VERSION "dbc-export 1 2025.20.8"

NS_ :

BS_:

BU_: ADSP APB APP APS APSB BB BMS CC CMP CMPD CP DAS DI DIF DIR DPB EPAS3P EPAS3S EPASTP EPASTS EPBL EPBR ESP EVSE FC GTW HCML HCMR HVP IBST ICR IDB LS OCS1P PARK PCS PM PMF PMR PNCD PTC RADC RCM RCM2 RCM3 RCU SCCM SCM SCS SDCR TAS TCU TPMS TRCM UI UIS UMC USM VC VCFRONT VCLEFT VCRIGHT VCSEC VEH

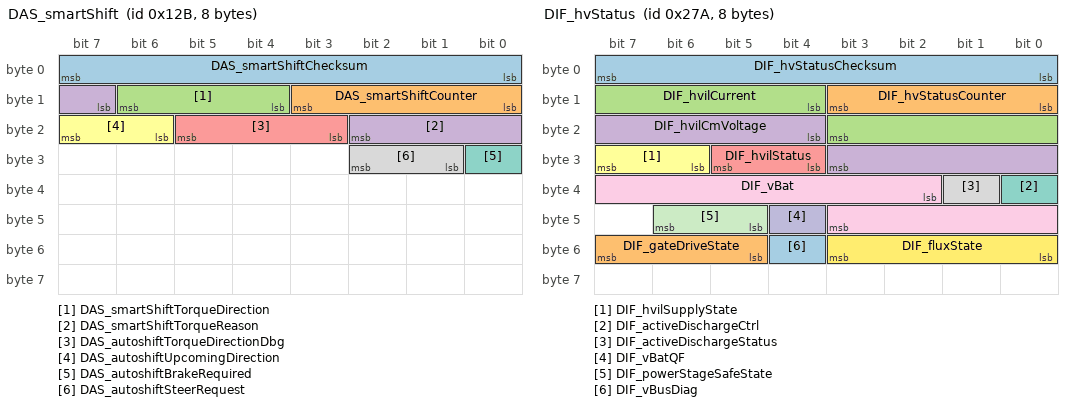
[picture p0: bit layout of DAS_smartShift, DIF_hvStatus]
BO_ 299 DAS_smartShift: 8 DAS
 SG_ DAS_smartShiftChecksum : 0|8@1+ (1,0) [0|255] "" Vector__XXX
 SG_ DAS_smartShiftCounter : 8|4@1+ (1,0) [0|15] "" Vector__XXX
 SG_ DAS_smartShiftTorqueDirection : 12|3@1+ (1,0) [0|7] "" Vector__XXX
 SG_ DAS_smartShiftTorqueReason : 15|4@1+ (1,0) [0|15] "" Vector__XXX
 SG_ DAS_autoshiftTorqueDirectionDbg : 19|3@1+ (1,0) [0|7] "" Vector__XXX
 SG_ DAS_autoshiftUpcomingDirection : 22|2@1+ (1,0) [0|3] "" Vector__XXX
 SG_ DAS_autoshiftBrakeRequired : 24|1@1+ (1,0) [0|1] "" Vector__XXX
 SG_ DAS_autoshiftSteerRequest : 25|2@1+ (1,0) [0|3] "" Vector__XXX

BO_ 921 DAS_status: 8 DAS
 SG_ DAS_autopilotState : 0|4@1+ (1,0) [0|15] "" Vector__XXX
 SG_ DAS_blindSpotRearLeft : 4|2@1+ (1,0) [0|3] "" Vector__XXX
 SG_ DAS_blindSpotRearRight : 6|2@1+ (1,0) [0|3] "" Vector__XXX
 SG_ DAS_fusedSpeedLimit : 8|5@1+ (5,0) [0|150] "kph/mph" Vector__XXX
 SG_ DAS_suppressSpeedWarning : 13|1@1+ (1,0) [0|1] "" Vector__XXX
 SG_ DAS_summonObstacle : 14|1@1+ (1,0) [0|1] "" Vector__XXX
 SG_ DAS_summonClearedGate : 15|1@1+ (1,0) [0|1] "" Vector__XXX
 SG_ DAS_visionOnlySpeedLimit : 16|5@1+ (5,0) [0|150] "kph/mph" Vector__XXX
 SG_ DAS_heaterState : 21|1@1+ (1,0) [0|1] "" Vector__XXX
 SG_ DAS_forwardCollisionWarning : 22|2@1+ (1,0) [0|3] "" Vector__XXX
 SG_ DAS_autoparkReady : 24|1@1+ (1,0) [0|1] "" Vector__XXX
 SG_ DAS_autoParked : 25|1@1+ (1,0) [0|1] "" Vector__XXX
 SG_ DAS_autoparkActive : 26|1@1+ (1,0) [0|1] "" Vector__XXX
 SG_ DAS_summonFwdLeashReached : 27|1@1+ (1,0) [0|1] "" Vector__XXX
 SG_ DAS_summonRvsLeashReached : 28|1@1+ (1,0) [0|1] "" Vector__XXX
 SG_ DAS_lssState : 29|3@1+ (1,0) [0|7] "" Vector__XXX
 SG_ DAS_sideCollisionAvoid : 32|2@1+ (1,0) [0|3] "" Vector__XXX
 SG_ DAS_sideCollisionWarning : 34|2@1+ (1,0) [0|3] "" Vector__XXX
 SG_ DAS_sideCollisionInhibit : 36|1@1+ (1,0) [0|1] "" Vector__XXX
 SG_ DAS_laneDepartureWarning : 37|3@1+ (1,0) [0|7] "" Vector__XXX
 SG_ DAS_fleetSpeedState : 40|2@1+ (1,0) [0|3] "" Vector__XXX
 SG_ DAS_autopilotHandsOnState : 42|4@1+ (1,0) [0|15] "" Vector__XXX
 SG_ DAS_autoLaneChangeState : 46|5@1+ (1,0) [0|31] "" Vector__XXX
 SG_ DAS_summonAvailable : 51|1@1+ (1,0) [0|1] "" Vector__XXX
 SG_ DAS_statusCounter : 52|4@1+ (1,0) [0|15] "" Vector__XXX
 SG_ DAS_statusChecksum : 56|8@1+ (1,0) [0|255] "" Vector__XXX

BO_ 905 DAS_status2: 8 DAS
 SG_ DAS_accSpeedLimit : 0|9@1+ (0.4,0) [0|200] "mph" Vector__XXX
 SG_ DAS_versionIdentifier : 9|1@1+ (1,0) [0|1] "" Vector__XXX
 SG_ DAS_pmmObstacleSeverity : 10|3@1+ (1,0) [0|7] "" Vector__XXX
 SG_ DAS_pmmLoggingRequest : 13|1@1+ (1,0) [0|1] "" Vector__XXX
 SG_ DAS_activationFailureStatus : 14|2@1+ (1,0) [0|3] "" Vector__XXX
 SG_ DAS_pmmUltrasonicsFaultReason : 16|3@1+ (1,0) [0|7] "" Vector__XXX
 SG_ DAS_pmmRadarFaultReason : 19|2@1+ (1,0) [0|3] "" Vector__XXX
 SG_ DAS_pmmSysFaultReason : 21|3@1+ (1,0) [0|7] "" Vector__XXX
 SG_ DAS_pmmCameraFaultReason : 24|2@1+ (1,0) [0|3] "" Vector__XXX
 SG_ DAS_ACC_report : 26|5@1+ (1,0) [0|31] "" Vector__XXX
 SG_ DAS_relaxCruiseLimits : 31|1@1+ (1,0) [0|1] "" Vector__XXX
 SG_ DAS_csaState : 32|2@1+ (1,0) [0|3] "" Vector__XXX
 SG_ DAS_radarTelemetry : 34|2@1+ (1,0) [0|3] "" Vector__XXX
 SG_ DAS_robState : 36|2@1+ (1,0) [0|3] "" Vector__XXX
 SG_ DAS_driverInteractionLevel : 38|2@1+ (1,0) [0|3] "" Vector__XXX
 SG_ DAS_ppOffsetDesiredRamp : 40|8@1+ (0.01,-1.28) [-1.28|1.27] "m" Vector__XXX
 SG_ DAS_longCollisionWarning : 48|4@1+ (1,0) [0|15] "" Vector__XXX
 SG_ DAS_status2Counter : 52|4@1+ (1,0) [0|15] "" Vector__XXX
 SG_ DAS_status2Checksum : 56|8@1+ (1,0) [0|255] "" Vector__XXX

BO_ 1548 DAS_telemetryRadar: 8 DAS
 SG_ DAS_TR_ObjIndex M : 0|5@1+ (1,0) [0|31] "" Vector__XXX
 SG_ DAS_TR_Counter : 54|2@1+ (1,0) [0|3] "" Vector__XXX
 SG_ DAS_TR_Obj00_Class m0 : 5|3@1+ (1,0) [0|7] "" Vector__XXX
 SG_ DAS_TR_Obj00_Dx m0 : 8|10@1+ (0.15625,0) [0|159.84375] "m" Vector__XXX
 SG_ DAS_TR_Obj00_Dy m0 : 18|6@1+ (0.5,-15.5) [-15.5|16] "m" Vector__XXX
 SG_ DAS_TR_Obj00_Vx m0 : 24|8@1+ (0.5,-63.5) [-63.5|64] "m/s" Vector__XXX
 SG_ DAS_TR_Obj00_RCS m0 : 32|8@1+ (0.25,-14) [-14|49.75] "dB" Vector__XXX
 SG_ DAS_TR_Obj00_Length m0 : 40|6@1+ (0.125,0) [0|7.875] "m" Vector__XXX
 SG_ DAS_TR_Obj00_MovingState m0 : 46|2@1+ (1,0) [0|3] "" Vector__XXX
 SG_ DAS_TR_Obj00_Dz m0 : 48|6@1+ (0.25,-5) [-5|10.75] "m" Vector__XXX
 SG_ DAS_TR_Obj00_Exist m0 : 56|5@1+ (3.125,0) [0|96.875] "%" Vector__XXX

BO_ 586 DAS_visualDebug: 8 DAS
 SG_ DAS_autosteerVehiclesUsage : 4|2@1+ (1,0) [0|3] "" Vector__XXX
 SG_ DAS_autosteerHPPUsage : 6|2@1+ (1,0) [0|3] "" Vector__XXX
 SG_ DAS_autosteerNavigationUsage : 8|2@1+ (1,0) [0|3] "" Vector__XXX
 SG_ DAS_autosteerModelUsage : 10|2@1+ (1,0) [0|3] "" Vector__XXX
 SG_ DAS_autosteerBottsDotsUsage : 12|2@1+ (1,0) [0|3] "" Vector__XXX
 SG_ DAS_offsetSide : 14|2@1+ (1,0) [0|3] "" Vector__XXX
 SG_ DAS_roadSurfaceType : 16|2@1+ (1,0) [0|3] "" Vector__XXX
 SG_ DAS_autosteerHealthAnomalyLevel : 18|3@1+ (1,0) [0|7] "" Vector__XXX
 SG_ DAS_autosteerHealthState : 21|3@1+ (1,0) [0|7] "" Vector__XXX
 SG_ DAS_lastLinePreferenceReason : 24|4@1+ (1,0) [0|15] "" Vector__XXX
 SG_ DAS_plannerState : 28|4@1+ (1,0) [0|15] "" Vector__XXX
 SG_ DAS_lastAutosteerAbortReason : 32|6@1+ (1,0) [0|63] "" Vector__XXX
 SG_ DAS_devAppInterfaceEnabled : 38|1@1+ (1,0) [0|1] "" Vector__XXX
 SG_ DAS_navAvailable : 39|1@1+ (1,0) [0|1] "" Vector__XXX
 SG_ DAS_navDistance : 40|8@1+ (100,0) [0|25500] "km" Vector__XXX
 SG_ DAS_accSmartSpeedActive : 48|1@1+ (1,0) [0|1] "" Vector__XXX
 SG_ DAS_accSmartSpeedState : 49|3@1+ (1,0) [0|7] "" Vector__XXX
 SG_ DAS_ulcInProgress : 52|1@1+ (1,0) [0|1] "" Vector__XXX
 SG_ DAS_trafficAwareSetSpeedInUse : 53|1@1+ (1,0) [0|1] "" Vector__XXX
 SG_ DAS_isaSystemState : 54|2@1+ (1,0) [0|3] "" Vector__XXX
 SG_ DAS_behaviorType : 56|2@1+ (1,0) [0|3] "" Vector__XXX
 SG_ DAS_ulcType : 58|2@1+ (1,0) [0|3] "" Vector__XXX
 SG_ DAS_rearVehDetectedThisCycle : 60|1@1+ (1,0) [0|1] "" Vector__XXX
 SG_ DAS_rearLeftVehDetectedCurrent : 61|1@1+ (1,0) [0|1] "" Vector__XXX
 SG_ DAS_rearRightVehDetectedTrip : 62|1@1+ (1,0) [0|1] "" Vector__XXX
 SG_ DAS_rearLeftVehDetectedTrip : 63|1@1+ (1,0) [0|1] "" Vector__XXX

BO_ 2040 DAS_warningMatrix0: 8 DAS
 SG_ DAS_w002_ldwDisabled : 1|1@1+ (1,0) [0|1] "" Vector__XXX
 SG_ DAS_w003_isaDisabled : 2|1@1+ (1,0) [0|1] "" Vector__XXX
 SG_ DAS_w004_accDisabled : 3|1@1+ (1,0) [0|1] "" Vector__XXX
 SG_ DAS_w005_fcwCancelled : 4|1@1+ (1,0) [0|1] "" Vector__XXX
 SG_ DAS_w006_aebCancelled : 5|1@1+ (1,0) [0|1] "" Vector__XXX
 SG_ DAS_w007_ahlbDisabled : 6|1@1+ (1,0) [0|1] "" Vector__XXX
 SG_ DAS_w008_parkDisabled : 7|1@1+ (1,0) [0|1] "" Vector__XXX
 SG_ DAS_w009_aebFault : 8|1@1+ (1,0) [0|1] "" Vector__XXX
 SG_ DAS_w010_radcCalibIssue : 9|1@1+ (1,0) [0|1] "" Vector__XXX
 SG_ DAS_w011_scaEvent : 10|1@1+ (1,0) [0|1] "" Vector__XXX
 SG_ DAS_w012_Cam_BootFailure : 11|1@1+ (1,0) [0|1] "" Vector__XXX
 SG_ DAS_w013_Cam_Watchdog : 12|1@1+ (1,0) [0|1] "" Vector__XXX
 SG_ DAS_w014_swAssert : 13|1@1+ (1,0) [0|1] "" Vector__XXX
 SG_ DAS_w015_Camera_Failsafes : 14|1@1+ (1,0) [0|1] "" Vector__XXX
 SG_ DAS_w016_aeb_e_event : 15|1@1+ (1,0) [0|1] "" Vector__XXX
 SG_ DAS_w017_Cam_Msg_MIA : 16|1@1+ (1,0) [0|1] "" Vector__XXX
 SG_ DAS_w018_ECU_Power_Issue : 17|1@1+ (1,0) [0|1] "" Vector__XXX
 SG_ DAS_w019_ECU_Stack_Overflow : 18|1@1+ (1,0) [0|1] "" Vector__XXX
 SG_ DAS_w020_ECU_checkstopError : 19|1@1+ (1,0) [0|1] "" Vector__XXX
 SG_ DAS_w021_ECU_Temperature_Issue : 20|1@1+ (1,0) [0|1] "" Vector__XXX
 SG_ DAS_w022_ECU_EEPROM_Failure : 21|1@1+ (1,0) [0|1] "" Vector__XXX
 SG_ DAS_w023_ECU_Cam_Statemismatc : 22|1@1+ (1,0) [0|1] "" Vector__XXX
 SG_ DAS_w024_ECU_Watchdog_Reset : 23|1@1+ (1,0) [0|1] "" Vector__XXX
 SG_ DAS_w025_LC_Steering_Override : 24|1@1+ (1,0) [0|1] "" Vector__XXX
 SG_ DAS_w026_ECU_timingIssue : 25|1@1+ (1,0) [0|1] "" Vector__XXX
 SG_ DAS_w027_ECU_Reset_Fault : 26|1@1+ (1,0) [0|1] "" Vector__XXX
 SG_ DAS_w028_spi_rx_error : 27|1@1+ (1,0) [0|1] "" Vector__XXX
 SG_ DAS_w029_spi_tx_error : 28|1@1+ (1,0) [0|1] "" Vector__XXX
 SG_ DAS_w030_Heater_Issue : 29|1@1+ (1,0) [0|1] "" Vector__XXX
 SG_ DAS_w031_canRxError : 30|1@1+ (1,0) [0|1] "" Vector__XXX
 SG_ DAS_w032_canTxError : 31|1@1+ (1,0) [0|1] "" Vector__XXX
 SG_ DAS_w033_gtwMia : 32|1@1+ (1,0) [0|1] "" Vector__XXX
 SG_ DAS_w034_sccmMia : 33|1@1+ (1,0) [0|1] "" Vector__XXX
 SG_ DAS_w035_espMia : 34|1@1+ (1,0) [0|1] "" Vector__XXX
 SG_ DAS_w036_bdyMia : 35|1@1+ (1,0) [0|1] "" Vector__XXX
 SG_ DAS_w037_camTacIssue : 36|1@1+ (1,0) [0|1] "" Vector__XXX
 SG_ DAS_w038_camFailure : 37|1@1+ (1,0) [0|1] "" Vector__XXX
 SG_ DAS_w039_sdm_rcm_Mia : 38|1@1+ (1,0) [0|1] "" Vector__XXX
 SG_ DAS_w040_autopilotAngleSaturated : 39|1@1+ (1,0) [0|1] "" Vector__XXX
 SG_ DAS_w041_autopilotRateSaturated : 40|1@1+ (1,0) [0|1] "" Vector__XXX
 SG_ DAS_w042_autopilotAborting : 41|1@1+ (1,0) [0|1] "" Vector__XXX
 SG_ DAS_w043_camLongRunTime : 42|1@1+ (1,0) [0|1] "" Vector__XXX
 SG_ DAS_w044_appMobileyeFailure : 43|1@1+ (1,0) [0|1] "" Vector__XXX
 SG_ DAS_w045_radMia : 44|1@1+ (1,0) [0|1] "" Vector__XXX
 SG_ DAS_w046_eepromRecordAbsent : 45|1@1+ (1,0) [0|1] "" Vector__XXX
 SG_ DAS_w047_edrEvent : 46|1@1+ (1,0) [0|1] "" Vector__XXX
 SG_ DAS_w048_DAS_Features_Disabled : 47|1@1+ (1,0) [0|1] "" Vector__XXX
 SG_ DAS_w049_eyeqVersionMismatch : 48|1@1+ (1,0) [0|1] "" Vector__XXX
 SG_ DAS_w050_aeb_event : 49|1@1+ (1,0) [0|1] "" Vector__XXX
 SG_ DAS_w051_radcEcuIssue : 50|1@1+ (1,0) [0|1] "" Vector__XXX
 SG_ DAS_w052_radcSensorIssue : 51|1@1+ (1,0) [0|1] "" Vector__XXX
 SG_ DAS_w053_radcCommIssue : 52|1@1+ (1,0) [0|1] "" Vector__XXX
 SG_ DAS_w054_camAutofix : 53|1@1+ (1,0) [0|1] "" Vector__XXX
 SG_ DAS_w055_radcVersionMismatch : 54|1@1+ (1,0) [0|1] "" Vector__XXX
 SG_ DAS_w056_diMia : 55|1@1+ (1,0) [0|1] "" Vector__XXX
 SG_ DAS_w057_mcuMia : 56|1@1+ (1,0) [0|1] "" Vector__XXX
 SG_ DAS_w058_epbMia : 57|1@1+ (1,0) [0|1] "" Vector__XXX
 SG_ DAS_w059_parkMia : 58|1@1+ (1,0) [0|1] "" Vector__XXX
 SG_ DAS_w060_fcw_event : 59|1@1+ (1,0) [0|1] "" Vector__XXX
 SG_ DAS_w061_airSuspensionMia : 60|1@1+ (1,0) [0|1] "" Vector__XXX
 SG_ DAS_w062_radcAlignment : 61|1@1+ (1,0) [0|1] "" Vector__XXX
 SG_ DAS_w063_parkVersionMismatch : 62|1@1+ (1,0) [0|1] "" Vector__XXX
 SG_ DAS_w064_epasMia : 63|1@1+ (1,0) [0|1] "" Vector__XXX

BO_ 874 DAS_warningMatrix1: 8 DAS
 SG_ DAS_w065_deserializerOvercurrent : 0|1@1+ (1,0) [0|1] "" Vector__XXX
 SG_ DAS_w066_deserializerLockLost : 1|1@1+ (1,0) [0|1] "" Vector__XXX
 SG_ DAS_w067_steeringAlignment : 2|1@1+ (1,0) [0|1] "" Vector__XXX
 SG_ DAS_w068_vlInconsistency : 3|1@1+ (1,0) [0|1] "" Vector__XXX
 SG_ DAS_w069_apcSpaceMasked : 4|1@1+ (1,0) [0|1] "" Vector__XXX
 SG_ DAS_w070_apcIncompleteCal : 5|1@1+ (1,0) [0|1] "" Vector__XXX
 SG_ DAS_w071_selfparkStarted : 6|1@1+ (1,0) [0|1] "" Vector__XXX
 SG_ DAS_w072_selfparkComplete : 7|1@1+ (1,0) [0|1] "" Vector__XXX
 SG_ DAS_w073_issueEscalatedLDW : 8|1@1+ (1,0) [0|1] "" Vector__XXX
 SG_ DAS_w074_inPathStationaryObst : 9|1@1+ (1,0) [0|1] "" Vector__XXX
 SG_ DAS_w075_scMia : 10|1@1+ (1,0) [0|1] "" Vector__XXX
 SG_ DAS_w076_mobilEyeSetC : 11|1@1+ (1,0) [0|1] "" Vector__XXX
 SG_ DAS_w077_pmmActive : 12|1@1+ (1,0) [0|1] "" Vector__XXX
 SG_ DAS_w078_pmmActive2 : 13|1@1+ (1,0) [0|1] "" Vector__XXX
 SG_ DAS_w079_edrAvailable : 14|1@1+ (1,0) [0|1] "" Vector__XXX
 SG_ DAS_w080_accFailedActivation : 15|1@1+ (1,0) [0|1] "" Vector__XXX
 SG_ DAS_w081_pmmActiveBraking : 16|1@1+ (1,0) [0|1] "" Vector__XXX
 SG_ DAS_w082_inPathFSviolation : 17|1@1+ (1,0) [0|1] "" Vector__XXX
 SG_ DAS_w083_inPathRADObject : 18|1@1+ (1,0) [0|1] "" Vector__XXX
 SG_ DAS_w084_pmmIPSO : 19|1@1+ (1,0) [0|1] "" Vector__XXX
 SG_ DAS_w085_pmmSteering : 20|1@1+ (1,0) [0|1] "" Vector__XXX
 SG_ DAS_w086_robCollision : 21|1@1+ (1,0) [0|1] "" Vector__XXX
 SG_ DAS_w087_DEPRECATED : 22|1@1+ (1,0) [0|1] "" Vector__XXX
 SG_ DAS_w088_DEPRECATED : 23|1@1+ (1,0) [0|1] "" Vector__XXX
 SG_ DAS_w089_DEPRECATED : 24|1@1+ (1,0) [0|1] "" Vector__XXX
 SG_ DAS_w090_DEPRECATED : 25|1@1+ (1,0) [0|1] "" Vector__XXX
 SG_ DAS_w091_DEPRECATED : 26|1@1+ (1,0) [0|1] "" Vector__XXX
 SG_ DAS_w092_DEPRECATED : 27|1@1+ (1,0) [0|1] "" Vector__XXX
 SG_ DAS_w093_DEPRECATED : 28|1@1+ (1,0) [0|1] "" Vector__XXX
 SG_ DAS_w094_DEPRECATED : 29|1@1+ (1,0) [0|1] "" Vector__XXX
 SG_ DAS_w095_DEPRECATED : 30|1@1+ (1,0) [0|1] "" Vector__XXX
 SG_ DAS_w096_DEPRECATED : 31|1@1+ (1,0) [0|1] "" Vector__XXX
 SG_ DAS_w097_DEPRECATED : 32|1@1+ (1,0) [0|1] "" Vector__XXX
 SG_ DAS_w098_DEPRECATED : 33|1@1+ (1,0) [0|1] "" Vector__XXX
 SG_ DAS_w099_DEPRECATED : 34|1@1+ (1,0) [0|1] "" Vector__XXX
 SG_ DAS_w100_DEPRECATED : 35|1@1+ (1,0) [0|1] "" Vector__XXX
 SG_ DAS_w101_DEPRECATED : 36|1@1+ (1,0) [0|1] "" Vector__XXX
 SG_ DAS_w102_DEPRECATED : 37|1@1+ (1,0) [0|1] "" Vector__XXX
 SG_ DAS_w103_robExperimentalAEB : 38|1@1+ (1,0) [0|1] "" Vector__XXX
 SG_ DAS_w104_DEPRECATED : 39|1@1+ (1,0) [0|1] "" Vector__XXX
 SG_ DAS_w105_DEPRECATED : 40|1@1+ (1,0) [0|1] "" Vector__XXX
 SG_ DAS_w106_torsionBarCalibrated : 41|1@1+ (1,0) [0|1] "" Vector__XXX

BO_ 841 DAS_warningMatrix2: 8 DAS
 SG_ DAS_w129_mainCamExtNotCal : 0|1@1+ (1,0) [0|1] "" Vector__XXX
 SG_ DAS_w130_narrowCamExtNotCal : 1|1@1+ (1,0) [0|1] "" Vector__XXX
 SG_ DAS_w131_mainCamCalSaved : 2|1@1+ (1,0) [0|1] "" Vector__XXX
 SG_ DAS_w132_narrowCamCalSaved : 3|1@1+ (1,0) [0|1] "" Vector__XXX
 SG_ DAS_w133_mainCamInitFault : 4|1@1+ (1,0) [0|1] "" Vector__XXX
 SG_ DAS_w134_narrowCamInitFault : 5|1@1+ (1,0) [0|1] "" Vector__XXX
 SG_ DAS_w135_fisheyeCamInitFault : 6|1@1+ (1,0) [0|1] "" Vector__XXX
 SG_ DAS_w136_lPillarCamInitFault : 7|1@1+ (1,0) [0|1] "" Vector__XXX
 SG_ DAS_w137_rPillarCamInitFault : 8|1@1+ (1,0) [0|1] "" Vector__XXX
 SG_ DAS_w138_lRepeatCamInitFault : 9|1@1+ (1,0) [0|1] "" Vector__XXX
 SG_ DAS_w139_rRepeatCamInitFault : 10|1@1+ (1,0) [0|1] "" Vector__XXX
 SG_ DAS_w140_backupCamInitFault : 11|1@1+ (1,0) [0|1] "" Vector__XXX
 SG_ DAS_w141_ECU_Thermal_Issue : 12|1@1+ (1,0) [0|1] "" Vector__XXX
 SG_ DAS_w142_fwdCamPitchProblem : 13|1@1+ (1,0) [0|1] "" Vector__XXX
 SG_ DAS_w143_IDF_event : 14|1@1+ (1,0) [0|1] "" Vector__XXX
 SG_ DAS_w144_selfieCamInitFault : 15|1@1+ (1,0) [0|1] "" Vector__XXX
 SG_ DAS_w171_fisheyeCamExtNotCal : 42|1@1+ (1,0) [0|1] "" Vector__XXX
 SG_ DAS_w172_lPillarCamExtNotCal : 43|1@1+ (1,0) [0|1] "" Vector__XXX
 SG_ DAS_w173_rPillarCamExtNotCal : 44|1@1+ (1,0) [0|1] "" Vector__XXX
 SG_ DAS_w174_lRepeatCamExtNotCal : 45|1@1+ (1,0) [0|1] "" Vector__XXX
 SG_ DAS_w175_rRepeatCamExtNotCal : 46|1@1+ (1,0) [0|1] "" Vector__XXX
 SG_ DAS_w177_fisheyeCamCalSaved : 48|1@1+ (1,0) [0|1] "" Vector__XXX
 SG_ DAS_w178_lPillarCamCalSaved : 49|1@1+ (1,0) [0|1] "" Vector__XXX
 SG_ DAS_w179_rPillarCamCalSaved : 50|1@1+ (1,0) [0|1] "" Vector__XXX
 SG_ DAS_w180_lRepeatCamCalSaved : 51|1@1+ (1,0) [0|1] "" Vector__XXX
 SG_ DAS_w181_rRepeatCamCalSaved : 52|1@1+ (1,0) [0|1] "" Vector__XXX

BO_ 1082 DAS_warningMatrix3: 8 DAS
 SG_ DAS_w193_camWindshieldUnclean : 0|1@1+ (1,0) [0|1] "" Vector__XXX
 SG_ DAS_w194_accDriverResumeRqrd : 1|1@1+ (1,0) [0|1] "" Vector__XXX
 SG_ DAS_w195_scwUnavailable : 2|1@1+ (1,0) [0|1] "" Vector__XXX
 SG_ DAS_w196_stopSignWarning : 3|1@1+ (1,0) [0|1] "" Vector__XXX
 SG_ DAS_w197_redLightWarning : 4|1@1+ (1,0) [0|1] "" Vector__XXX
 SG_ DAS_w198_tsrUnavailable : 5|1@1+ (1,0) [0|1] "" Vector__XXX
 SG_ DAS_w199_apcAbort : 6|1@1+ (1,0) [0|1] "" Vector__XXX
 SG_ DAS_w200_lcSlowdown : 7|1@1+ (1,0) [0|1] "" Vector__XXX
 SG_ DAS_w201_lcAborting : 8|1@1+ (1,0) [0|1] "" Vector__XXX
 SG_ DAS_w202_scwNoisyEnvironment : 9|1@1+ (1,0) [0|1] "" Vector__XXX
 SG_ DAS_w203_apcActivation : 10|1@1+ (1,0) [0|1] "" Vector__XXX
 SG_ DAS_w204_apcFinalFront : 11|1@1+ (1,0) [0|1] "" Vector__XXX
 SG_ DAS_w205_apcFinalRear : 12|1@1+ (1,0) [0|1] "" Vector__XXX
 SG_ DAS_w206_autosteerNotEnabled : 13|1@1+ (1,0) [0|1] "" Vector__XXX
 SG_ DAS_w207_autosteerUnavailable : 14|1@1+ (1,0) [0|1] "" Vector__XXX
 SG_ DAS_w208_rackDetected : 15|1@1+ (1,0) [0|1] "" Vector__XXX
 SG_ DAS_w209_autoSummonRequest : 16|1@1+ (1,0) [0|1] "" Vector__XXX
 SG_ DAS_w210_camObstrcted : 17|1@1+ (1,0) [0|1] "" Vector__XXX
 SG_ DAS_w211_accNoSeatBelt : 18|1@1+ (1,0) [0|1] "" Vector__XXX
 SG_ DAS_w212_lcUnavailableStrikeOut : 19|1@1+ (1,0) [0|1] "" Vector__XXX
 SG_ DAS_w213_autosteerStruckOut : 20|1@1+ (1,0) [0|1] "" Vector__XXX
 SG_ DAS_w214_driverNotIntracting : 21|1@1+ (1,0) [0|1] "" Vector__XXX
 SG_ DAS_w215_contDriverNotIntracting : 22|1@1+ (1,0) [0|1] "" Vector__XXX
 SG_ DAS_w216_driverOverriding : 23|1@1+ (1,0) [0|1] "" Vector__XXX
 SG_ DAS_w217_lcUnavailableSpeeding : 24|1@1+ (1,0) [0|1] "" Vector__XXX
 SG_ DAS_w218_lcSpeedExceededLimit : 25|1@1+ (1,0) [0|1] "" Vector__XXX
 SG_ DAS_w219_lcTempUnavailableSpeed : 26|1@1+ (1,0) [0|1] "" Vector__XXX
 SG_ DAS_w220_lcTempUnavailableRoad : 27|1@1+ (1,0) [0|1] "" Vector__XXX
 SG_ DAS_w221_accRadarBlind : 28|1@1+ (1,0) [0|1] "" Vector__XXX
 SG_ DAS_w222_accCameraBlind : 29|1@1+ (1,0) [0|1] "" Vector__XXX
 SG_ DAS_w223_accObjectInPath : 30|1@1+ (1,0) [0|1] "" Vector__XXX
 SG_ DAS_w224_accCameraCalibration : 31|1@1+ (1,0) [0|1] "" Vector__XXX
 SG_ DAS_w225_lcDegradedVisSpeedLmt : 32|1@1+ (1,0) [0|1] "" Vector__XXX
 SG_ DAS_w226_lcCamCalNeededSpeedLmt : 33|1@1+ (1,0) [0|1] "" Vector__XXX
 SG_ DAS_w227_virtualWallBlocked : 34|1@1+ (1,0) [0|1] "" Vector__XXX
 SG_ DAS_w228_DEPRECATED : 35|1@1+ (1,0) [0|1] "" Vector__XXX
 SG_ DAS_w229_alcUltrasoundDamaged : 36|1@1+ (1,0) [0|1] "" Vector__XXX
 SG_ DAS_w230_alcUltrasoundBlocked : 37|1@1+ (1,0) [0|1] "" Vector__XXX
 SG_ DAS_w231_idfEvent : 38|1@1+ (1,0) [0|1] "" Vector__XXX
 SG_ DAS_w232_laneChangeRequested : 39|1@1+ (1,0) [0|1] "" Vector__XXX

BO_ 1318 DIF_alertLog: 8 DIF
 SG_ DIF_alertID M : 0|8@1+ (1,0) [0|255] "" Vector__XXX
 SG_ DIF_alertState : 15|1@1+ (1,0) [0|1] "" Vector__XXX
 SG_ DIF_a001_thermalWarning_H m1 : 16|1@1+ (1,0) [0|1] "" Vector__XXX
 SG_ DIF_a001_thermalShutdown_H m1 : 17|1@1+ (1,0) [0|1] "" Vector__XXX
 SG_ DIF_a001_undervoltVL_H m1 : 18|1@1+ (1,0) [0|1] "" Vector__XXX
 SG_ DIF_a001_undervoltVH_H m1 : 19|1@1+ (1,0) [0|1] "" Vector__XXX
 SG_ DIF_a001_sense_H m1 : 20|1@1+ (1,0) [0|1] "" Vector__XXX
 SG_ DIF_a001_desat_H m1 : 21|1@1+ (1,0) [0|1] "" Vector__XXX
 SG_ DIF_a001_overvoltVL_H m1 : 22|1@1+ (1,0) [0|1] "" Vector__XXX
 SG_ DIF_a001_overvoltVH_H m1 : 23|1@1+ (1,0) [0|1] "" Vector__XXX
 SG_ DIF_a001_undervoltVCC_H m1 : 24|1@1+ (1,0) [0|1] "" Vector__XXX
 SG_ DIF_a001_asynchStop_H m1 : 25|1@1+ (1,0) [0|1] "" Vector__XXX
 SG_ DIF_a001_remoteRegError_H m1 : 26|1@1+ (1,0) [0|1] "" Vector__XXX
 SG_ DIF_a001_undervoltVDD_H m1 : 27|1@1+ (1,0) [0|1] "" Vector__XXX
 SG_ DIF_a001_overvoltVDD_H m1 : 28|1@1+ (1,0) [0|1] "" Vector__XXX
 SG_ DIF_a001_localRegError_H m1 : 29|1@1+ (1,0) [0|1] "" Vector__XXX
 SG_ DIF_a001_spiError_H m1 : 30|1@1+ (1,0) [0|1] "" Vector__XXX
 SG_ DIF_a001_deadtimeError_H m1 : 31|1@1+ (1,0) [0|1] "" Vector__XXX
 SG_ DIF_a001_thermalWarning_L m1 : 32|1@1+ (1,0) [0|1] "" Vector__XXX
 SG_ DIF_a001_thermalShutdown_L m1 : 33|1@1+ (1,0) [0|1] "" Vector__XXX
 SG_ DIF_a001_undervoltVL_L m1 : 34|1@1+ (1,0) [0|1] "" Vector__XXX
 SG_ DIF_a001_undervoltVH_L m1 : 35|1@1+ (1,0) [0|1] "" Vector__XXX
 SG_ DIF_a001_sense_L m1 : 36|1@1+ (1,0) [0|1] "" Vector__XXX
 SG_ DIF_a001_desat_L m1 : 37|1@1+ (1,0) [0|1] "" Vector__XXX
 SG_ DIF_a001_overvoltVL_L m1 : 38|1@1+ (1,0) [0|1] "" Vector__XXX
 SG_ DIF_a001_overvoltVH_L m1 : 39|1@1+ (1,0) [0|1] "" Vector__XXX
 SG_ DIF_a001_undervoltVCC_L m1 : 40|1@1+ (1,0) [0|1] "" Vector__XXX
 SG_ DIF_a001_asynchStop_L m1 : 41|1@1+ (1,0) [0|1] "" Vector__XXX
 SG_ DIF_a001_remoteRegError_L m1 : 42|1@1+ (1,0) [0|1] "" Vector__XXX
 SG_ DIF_a001_undervoltVDD_L m1 : 43|1@1+ (1,0) [0|1] "" Vector__XXX
 SG_ DIF_a001_overvoltVDD_L m1 : 44|1@1+ (1,0) [0|1] "" Vector__XXX
 SG_ DIF_a001_localRegError_L m1 : 45|1@1+ (1,0) [0|1] "" Vector__XXX
 SG_ DIF_a001_spiError_L m1 : 46|1@1+ (1,0) [0|1] "" Vector__XXX
 SG_ DIF_a001_deadtimeError_L m1 : 47|1@1+ (1,0) [0|1] "" Vector__XXX
 SG_ DIF_a001_gateDriveErrCounter m1 : 48|4@1+ (1,0) [0|15] "" Vector__XXX
 SG_ DIF_a001_remoteCommError_H m1 : 52|1@1+ (1,0) [0|1] "" Vector__XXX
 SG_ DIF_a001_localCommError_H m1 : 53|1@1+ (1,0) [0|1] "" Vector__XXX
 SG_ DIF_a001_remoteReset_H m1 : 54|1@1+ (1,0) [0|1] "" Vector__XXX
 SG_ DIF_a001_localReset_H m1 : 55|1@1+ (1,0) [0|1] "" Vector__XXX
 SG_ DIF_a001_remoteCommError_L m1 : 56|1@1+ (1,0) [0|1] "" Vector__XXX
 SG_ DIF_a001_localCommError_L m1 : 57|1@1+ (1,0) [0|1] "" Vector__XXX
 SG_ DIF_a001_remoteReset_L m1 : 58|1@1+ (1,0) [0|1] "" Vector__XXX
 SG_ DIF_a001_localReset_L m1 : 59|1@1+ (1,0) [0|1] "" Vector__XXX
 SG_ DIF_a001_faultLine1Gpio_H m1 : 60|1@1+ (1,0) [0|1] "" Vector__XXX
 SG_ DIF_a001_faultLine1Gpio_L m1 : 61|1@1+ (1,0) [0|1] "" Vector__XXX
 SG_ DIF_a002_thermalWarning_H m2 : 16|1@1+ (1,0) [0|1] "" Vector__XXX
 SG_ DIF_a002_thermalShutdown_H m2 : 17|1@1+ (1,0) [0|1] "" Vector__XXX
 SG_ DIF_a002_undervoltVL_H m2 : 18|1@1+ (1,0) [0|1] "" Vector__XXX
 SG_ DIF_a002_undervoltVH_H m2 : 19|1@1+ (1,0) [0|1] "" Vector__XXX
 SG_ DIF_a002_sense_H m2 : 20|1@1+ (1,0) [0|1] "" Vector__XXX
 SG_ DIF_a002_desat_H m2 : 21|1@1+ (1,0) [0|1] "" Vector__XXX
 SG_ DIF_a002_overvoltVL_H m2 : 22|1@1+ (1,0) [0|1] "" Vector__XXX
 SG_ DIF_a002_overvoltVH_H m2 : 23|1@1+ (1,0) [0|1] "" Vector__XXX
 SG_ DIF_a002_undervoltVCC_H m2 : 24|1@1+ (1,0) [0|1] "" Vector__XXX
 SG_ DIF_a002_asynchStop_H m2 : 25|1@1+ (1,0) [0|1] "" Vector__XXX
 SG_ DIF_a002_remoteRegError_H m2 : 26|1@1+ (1,0) [0|1] "" Vector__XXX
 SG_ DIF_a002_undervoltVDD_H m2 : 27|1@1+ (1,0) [0|1] "" Vector__XXX
 SG_ DIF_a002_overvoltVDD_H m2 : 28|1@1+ (1,0) [0|1] "" Vector__XXX
 SG_ DIF_a002_localRegError_H m2 : 29|1@1+ (1,0) [0|1] "" Vector__XXX
 SG_ DIF_a002_spiError_H m2 : 30|1@1+ (1,0) [0|1] "" Vector__XXX
 SG_ DIF_a002_deadtimeError_H m2 : 31|1@1+ (1,0) [0|1] "" Vector__XXX
 SG_ DIF_a002_thermalWarning_L m2 : 32|1@1+ (1,0) [0|1] "" Vector__XXX
 SG_ DIF_a002_thermalShutdown_L m2 : 33|1@1+ (1,0) [0|1] "" Vector__XXX
 SG_ DIF_a002_undervoltVL_L m2 : 34|1@1+ (1,0) [0|1] "" Vector__XXX
 SG_ DIF_a002_undervoltVH_L m2 : 35|1@1+ (1,0) [0|1] "" Vector__XXX
 SG_ DIF_a002_sense_L m2 : 36|1@1+ (1,0) [0|1] "" Vector__XXX
 SG_ DIF_a002_desat_L m2 : 37|1@1+ (1,0) [0|1] "" Vector__XXX
 SG_ DIF_a002_overvoltVL_L m2 : 38|1@1+ (1,0) [0|1] "" Vector__XXX
 SG_ DIF_a002_overvoltVH_L m2 : 39|1@1+ (1,0) [0|1] "" Vector__XXX
 SG_ DIF_a002_undervoltVCC_L m2 : 40|1@1+ (1,0) [0|1] "" Vector__XXX
 SG_ DIF_a002_asynchStop_L m2 : 41|1@1+ (1,0) [0|1] "" Vector__XXX
 SG_ DIF_a002_remoteRegError_L m2 : 42|1@1+ (1,0) [0|1] "" Vector__XXX
 SG_ DIF_a002_undervoltVDD_L m2 : 43|1@1+ (1,0) [0|1] "" Vector__XXX
 SG_ DIF_a002_overvoltVDD_L m2 : 44|1@1+ (1,0) [0|1] "" Vector__XXX
 SG_ DIF_a002_localRegError_L m2 : 45|1@1+ (1,0) [0|1] "" Vector__XXX
 SG_ DIF_a002_spiError_L m2 : 46|1@1+ (1,0) [0|1] "" Vector__XXX
 SG_ DIF_a002_deadtimeError_L m2 : 47|1@1+ (1,0) [0|1] "" Vector__XXX
 SG_ DIF_a002_gateDriveErrCounter m2 : 48|4@1+ (1,0) [0|15] "" Vector__XXX
 SG_ DIF_a002_selftestDesat_L m2 : 52|1@1+ (1,0) [0|1] "" Vector__XXX
 SG_ DIF_a002_selftestDesat_H m2 : 53|1@1+ (1,0) [0|1] "" Vector__XXX
 SG_ DIF_a002_remoteCommError_H m2 : 54|1@1+ (1,0) [0|1] "" Vector__XXX
 SG_ DIF_a002_localCommError_H m2 : 55|1@1+ (1,0) [0|1] "" Vector__XXX
 SG_ DIF_a002_remoteReset_H m2 : 56|1@1+ (1,0) [0|1] "" Vector__XXX
 SG_ DIF_a002_localReset_H m2 : 57|1@1+ (1,0) [0|1] "" Vector__XXX
 SG_ DIF_a002_remoteCommError_L m2 : 58|1@1+ (1,0) [0|1] "" Vector__XXX
 SG_ DIF_a002_localCommError_L m2 : 59|1@1+ (1,0) [0|1] "" Vector__XXX
 SG_ DIF_a002_remoteReset_L m2 : 60|1@1+ (1,0) [0|1] "" Vector__XXX
 SG_ DIF_a002_localReset_L m2 : 61|1@1+ (1,0) [0|1] "" Vector__XXX
 SG_ DIF_a002_faultLine1Gpio_H m2 : 62|1@1+ (1,0) [0|1] "" Vector__XXX
 SG_ DIF_a002_faultLine1Gpio_L m2 : 63|1@1+ (1,0) [0|1] "" Vector__XXX
 SG_ DIF_a003_thermalWarning_H m3 : 16|1@1+ (1,0) [0|1] "" Vector__XXX
 SG_ DIF_a003_thermalShutdown_H m3 : 17|1@1+ (1,0) [0|1] "" Vector__XXX
 SG_ DIF_a003_undervoltVL_H m3 : 18|1@1+ (1,0) [0|1] "" Vector__XXX
 SG_ DIF_a003_undervoltVH_H m3 : 19|1@1+ (1,0) [0|1] "" Vector__XXX
 SG_ DIF_a003_sense_H m3 : 20|1@1+ (1,0) [0|1] "" Vector__XXX
 SG_ DIF_a003_desat_H m3 : 21|1@1+ (1,0) [0|1] "" Vector__XXX
 SG_ DIF_a003_overvoltVL_H m3 : 22|1@1+ (1,0) [0|1] "" Vector__XXX
 SG_ DIF_a003_overvoltVH_H m3 : 23|1@1+ (1,0) [0|1] "" Vector__XXX
 SG_ DIF_a003_undervoltVCC_H m3 : 24|1@1+ (1,0) [0|1] "" Vector__XXX
 SG_ DIF_a003_asynchStop_H m3 : 25|1@1+ (1,0) [0|1] "" Vector__XXX
 SG_ DIF_a003_remoteRegError_H m3 : 26|1@1+ (1,0) [0|1] "" Vector__XXX
 SG_ DIF_a003_undervoltVDD_H m3 : 27|1@1+ (1,0) [0|1] "" Vector__XXX
 SG_ DIF_a003_overvoltVDD_H m3 : 28|1@1+ (1,0) [0|1] "" Vector__XXX
 SG_ DIF_a003_localRegError_H m3 : 29|1@1+ (1,0) [0|1] "" Vector__XXX
 SG_ DIF_a003_spiError_H m3 : 30|1@1+ (1,0) [0|1] "" Vector__XXX
 SG_ DIF_a003_deadtimeError_H m3 : 31|1@1+ (1,0) [0|1] "" Vector__XXX
 SG_ DIF_a003_thermalWarning_L m3 : 32|1@1+ (1,0) [0|1] "" Vector__XXX
 SG_ DIF_a003_thermalShutdown_L m3 : 33|1@1+ (1,0) [0|1] "" Vector__XXX
 SG_ DIF_a003_undervoltVL_L m3 : 34|1@1+ (1,0) [0|1] "" Vector__XXX
 SG_ DIF_a003_undervoltVH_L m3 : 35|1@1+ (1,0) [0|1] "" Vector__XXX
 SG_ DIF_a003_sense_L m3 : 36|1@1+ (1,0) [0|1] "" Vector__XXX
 SG_ DIF_a003_desat_L m3 : 37|1@1+ (1,0) [0|1] "" Vector__XXX
 SG_ DIF_a003_overvoltVL_L m3 : 38|1@1+ (1,0) [0|1] "" Vector__XXX
 SG_ DIF_a003_overvoltVH_L m3 : 39|1@1+ (1,0) [0|1] "" Vector__XXX
 SG_ DIF_a003_undervoltVCC_L m3 : 40|1@1+ (1,0) [0|1] "" Vector__XXX
 SG_ DIF_a003_asynchStop_L m3 : 41|1@1+ (1,0) [0|1] "" Vector__XXX
 SG_ DIF_a003_remoteRegError_L m3 : 42|1@1+ (1,0) [0|1] "" Vector__XXX
 SG_ DIF_a003_undervoltVDD_L m3 : 43|1@1+ (1,0) [0|1] "" Vector__XXX
 SG_ DIF_a003_overvoltVDD_L m3 : 44|1@1+ (1,0) [0|1] "" Vector__XXX
 SG_ DIF_a003_localRegError_L m3 : 45|1@1+ (1,0) [0|1] "" Vector__XXX
 SG_ DIF_a003_spiError_L m3 : 46|1@1+ (1,0) [0|1] "" Vector__XXX
 SG_ DIF_a003_deadtimeError_L m3 : 47|1@1+ (1,0) [0|1] "" Vector__XXX
 SG_ DIF_a003_gateDriveErrCounter m3 : 48|4@1+ (1,0) [0|15] "" Vector__XXX
 SG_ DIF_a003_selftestDesat_L m3 : 52|1@1+ (1,0) [0|1] "" Vector__XXX
 SG_ DIF_a003_selftestDesat_H m3 : 53|1@1+ (1,0) [0|1] "" Vector__XXX
 SG_ DIF_a003_remoteCommError_H m3 : 54|1@1+ (1,0) [0|1] "" Vector__XXX
 SG_ DIF_a003_localCommError_H m3 : 55|1@1+ (1,0) [0|1] "" Vector__XXX
 SG_ DIF_a003_remoteReset_H m3 : 56|1@1+ (1,0) [0|1] "" Vector__XXX
 SG_ DIF_a003_localReset_H m3 : 57|1@1+ (1,0) [0|1] "" Vector__XXX
 SG_ DIF_a003_remoteCommError_L m3 : 58|1@1+ (1,0) [0|1] "" Vector__XXX
 SG_ DIF_a003_localCommError_L m3 : 59|1@1+ (1,0) [0|1] "" Vector__XXX
 SG_ DIF_a003_remoteReset_L m3 : 60|1@1+ (1,0) [0|1] "" Vector__XXX
 SG_ DIF_a003_localReset_L m3 : 61|1@1+ (1,0) [0|1] "" Vector__XXX
 SG_ DIF_a003_faultLine1Gpio_H m3 : 62|1@1+ (1,0) [0|1] "" Vector__XXX
 SG_ DIF_a003_faultLine1Gpio_L m3 : 63|1@1+ (1,0) [0|1] "" Vector__XXX
 SG_ DIF_a007_phaseAcurrent m7 : 16|8@1+ (8,0) [0|2040] "" Vector__XXX
 SG_ DIF_a007_phaseBcurrent m7 : 24|8@1+ (8,0) [0|2040] "" Vector__XXX
 SG_ DIF_a007_offsetError m7 : 32|14@1- (0.0003834952,0) [-3.1415926784|3.1412091832] "" Vector__XXX
 SG_ DIF_a007_idFdbStdDeviation m7 : 46|8@1+ (4,0) [0|1020] "" Vector__XXX
 SG_ DIF_a007_iqFdbStdDeviation m7 : 54|8@1+ (4,0) [0|1020] "" Vector__XXX
 SG_ DIF_a007_motorShift m7 : 62|1@1+ (1,0) [0|1] "" Vector__XXX
 SG_ DIF_a007_motorShort m7 : 63|1@1+ (1,0) [0|1] "" Vector__XXX
 SG_ DIF_a010_sccReset m10 : 16|1@1+ (1,0) [0|1] "" Vector__XXX
 SG_ DIF_a010_hibernate m10 : 17|1@1+ (1,0) [0|1] "" Vector__XXX
 SG_ DIF_a010_hwBist m10 : 18|1@1+ (1,0) [0|1] "" Vector__XXX
 SG_ DIF_a010_nmiWatchdog m10 : 19|1@1+ (1,0) [0|1] "" Vector__XXX
 SG_ DIF_a010_watchdog m10 : 20|1@1+ (1,0) [0|1] "" Vector__XXX
 SG_ DIF_a010_clockFailNmi m10 : 21|1@1+ (1,0) [0|1] "" Vector__XXX
 SG_ DIF_a010_ramUncErrorNmi m10 : 22|1@1+ (1,0) [0|1] "" Vector__XXX
 SG_ DIF_a010_flashUncErrorNmi m10 : 23|1@1+ (1,0) [0|1] "" Vector__XXX
 SG_ DIF_a010_cpu1signMismatchNmi m10 : 24|1@1+ (1,0) [0|1] "" Vector__XXX
 SG_ DIF_a010_cpu2signMismatchNmi m10 : 25|1@1+ (1,0) [0|1] "" Vector__XXX
 SG_ DIF_a010_pieVectErrorNmi m10 : 26|1@1+ (1,0) [0|1] "" Vector__XXX
 SG_ DIF_a010_sysDbgNmi m10 : 27|1@1+ (1,0) [0|1] "" Vector__XXX
 SG_ DIF_a010_rlNmi m10 : 28|1@1+ (1,0) [0|1] "" Vector__XXX
 SG_ DIF_a010_ovfNmi m10 : 29|1@1+ (1,0) [0|1] "" Vector__XXX
 SG_ DIF_a010_wdtFlags m10 : 32|16@1+ (1,0) [0|65535] "" Vector__XXX
 SG_ DIF_a011_reason m11 : 16|3@1+ (1,0) [0|7] "" Vector__XXX
 SG_ DIF_a011_phaseAHigh m11 : 19|1@1+ (1,0) [0|1] "" Vector__XXX
 SG_ DIF_a011_phaseALow m11 : 20|1@1+ (1,0) [0|1] "" Vector__XXX
 SG_ DIF_a011_phaseBHigh m11 : 21|1@1+ (1,0) [0|1] "" Vector__XXX
 SG_ DIF_a011_phaseBLow m11 : 22|1@1+ (1,0) [0|1] "" Vector__XXX
 SG_ DIF_a011_phaseCHigh m11 : 23|1@1+ (1,0) [0|1] "" Vector__XXX
 SG_ DIF_a011_phaseCLow m11 : 24|1@1+ (1,0) [0|1] "" Vector__XXX
 SG_ DIF_a011_regAddress m11 : 25|5@1+ (1,0) [0|31] "" Vector__XXX
 SG_ DIF_a011_badGateDriveIC m11 : 32|3@1+ (1,0) [0|7] "" Vector__XXX
 SG_ DIF_a011_badDataRead m11 : 40|8@1+ (1,0) [0|255] "" Vector__XXX
 SG_ DIF_a011_badDataExpected m11 : 48|8@1+ (1,0) [0|255] "" Vector__XXX
 SG_ DIF_a011_codeBranch m11 : 56|4@1+ (1,0) [0|15] "" Vector__XXX
 SG_ DIF_a012_hvilStatus m12 : 16|2@1+ (1,0) [0|3] "" Vector__XXX
 SG_ DIF_a012_hvilCmVoltage m12 : 24|8@1+ (0.08,0) [0|20.4] "" Vector__XXX
 SG_ DIF_a012_hvilCurrent m12 : 32|8@1+ (0.1,0) [0|25.5] "" Vector__XXX
 SG_ DIF_a012_hvilFaultGpio m12 : 40|1@1+ (1,0) [0|1] "" Vector__XXX
 SG_ DIF_a012_hvilSupplyPinDI m12 : 41|1@1+ (1,0) [0|1] "" Vector__XXX
 SG_ DIF_a012_hvilSupplyPinPM m12 : 42|1@1+ (1,0) [0|1] "" Vector__XXX
 SG_ DIF_a012_activeDisOn3V3 m12 : 43|1@1+ (1,0) [0|1] "" Vector__XXX
 SG_ DIF_a012_hvilHeaderFault m12 : 44|1@1+ (1,0) [0|1] "" Vector__XXX
 SG_ DIF_a013_address m13 : 16|32@1+ (1,0) [0|4294967295] "" Vector__XXX
 SG_ DIF_a013_errorType m13 : 48|4@1+ (1,0) [0|15] "" Vector__XXX
 SG_ DIF_a014_motorSpeed m14 : 16|14@1- (2,0) [-16384|16382] "" Vector__XXX
 SG_ DIF_a014_adState m14 : 30|2@1+ (1,0) [0|3] "" Vector__XXX
 SG_ DIF_a014_torqueCommandFwd m14 : 32|10@1- (2,0) [-1024|1022] "" Vector__XXX
 SG_ DIF_a014_brakeMasterCylPress m14 : 42|10@1+ (0.25,-42.5) [-42.5|213.25] "" Vector__XXX
 SG_ DIF_a014_rmsTorqueError m14 : 52|10@1+ (1,0) [0|1023] "" Vector__XXX
 SG_ DIF_a014_tcEnabled m14 : 62|1@1+ (1,0) [0|1] "" Vector__XXX
 SG_ DIF_a016_newSafeState m16 : 16|2@1+ (1,0) [0|3] "" Vector__XXX
 SG_ DIF_a016_oldSafeState m16 : 18|2@1+ (1,0) [0|3] "" Vector__XXX
 SG_ DIF_a016_gateDriveFaultLine m16 : 20|1@1+ (1,0) [0|1] "" Vector__XXX
 SG_ DIF_a016_ascMonitor m16 : 21|1@1+ (1,0) [0|1] "" Vector__XXX
 SG_ DIF_a016_uncontrolledRegenZone m16 : 22|1@1+ (1,0) [0|1] "" Vector__XXX
 SG_ DIF_a016_pedalMonitorPreWatchdog m16 : 23|1@1+ (1,0) [0|1] "" Vector__XXX
 SG_ DIF_a016_motorRPM m16 : 24|16@1- (1,0) [-32768|32767] "" Vector__XXX
 SG_ DIF_a016_torqueMotor m16 : 40|16@1- (1,0) [-32768|32767] "" Vector__XXX
 SG_ DIF_a016_safetyICfaultLine m16 : 56|1@1+ (1,0) [0|1] "" Vector__XXX
 SG_ DIF_a016_triggerEvent m16 : 57|5@1+ (1,0) [0|31] "" Vector__XXX
 SG_ DIF_a024_vBat m24 : 16|8@1+ (2,0) [0|510] "" Vector__XXX
 SG_ DIF_a024_failReason m24 : 24|3@1+ (1,0) [0|7] "" Vector__XXX
 SG_ DIF_a024_state m24 : 27|4@1+ (1,0) [0|15] "" Vector__XXX
 SG_ DIF_a024_Ia m24 : 31|7@1- (22.5,0) [-1440|1417.5] "" Vector__XXX
 SG_ DIF_a024_Ib m24 : 38|7@1- (22.5,0) [-1440|1417.5] "" Vector__XXX
 SG_ DIF_a024_maxCurrMagSqrd m24 : 45|12@1+ (500,0) [0|2047500] "" Vector__XXX
 SG_ DIF_a024_rotorAngle m24 : 57|7@1- (3,0) [-192|189] "" Vector__XXX
 SG_ DIF_a025_Ia m25 : 16|16@1- (0.1,0) [-3276.8|3276.7] "" Vector__XXX
 SG_ DIF_a025_torqueMotor m25 : 32|13@1- (0.25,0) [-1024|1023.75] "" Vector__XXX
 SG_ DIF_a025_motorSpeed m25 : 48|16@1- (1,0) [-32768|32767] "" Vector__XXX
 SG_ DIF_a026_Ib m26 : 16|16@1- (0.1,0) [-3276.8|3276.7] "" Vector__XXX
 SG_ DIF_a026_torqueMotor m26 : 32|13@1- (0.25,0) [-1024|1023.75] "" Vector__XXX
 SG_ DIF_a026_motorSpeed m26 : 48|16@1- (1,0) [-32768|32767] "" Vector__XXX
 SG_ DIF_a027_Ic m27 : 16|16@1- (0.1,0) [-3276.8|3276.7] "" Vector__XXX
 SG_ DIF_a027_torqueMotor m27 : 32|13@1- (0.25,0) [-1024|1023.75] "" Vector__XXX
 SG_ DIF_a027_motorSpeed m27 : 48|16@1- (1,0) [-32768|32767] "" Vector__XXX
 SG_ DIF_a028_phaseAirms m28 : 16|16@1+ (1,0) [0|65535] "" Vector__XXX
 SG_ DIF_a028_iArmsTorque m28 : 32|16@1+ (0.25,0) [0|16383.75] "" Vector__XXX
 SG_ DIF_a028_iArmsSpeed m28 : 48|16@1+ (1,0) [0|65535] "" Vector__XXX
 SG_ DIF_a029_phaseBirms m29 : 16|16@1+ (1,0) [0|65535] "" Vector__XXX
 SG_ DIF_a029_iBrmsTorque m29 : 32|16@1+ (0.25,0) [0|16383.75] "" Vector__XXX
 SG_ DIF_a029_iBrmsSpeed m29 : 48|16@1+ (1,0) [0|65535] "" Vector__XXX
 SG_ DIF_a030_phaseCirms m30 : 16|16@1+ (1,0) [0|65535] "" Vector__XXX
 SG_ DIF_a030_iCrmsTorque m30 : 32|16@1+ (0.25,0) [0|16383.75] "" Vector__XXX
 SG_ DIF_a030_iCrmsSpeed m30 : 48|16@1+ (1,0) [0|65535] "" Vector__XXX
 SG_ DIF_a031_phaseAoffset m31 : 16|16@1- (0.002,0) [-65.536|65.534] "" Vector__XXX
 SG_ DIF_a032_phaseBoffset m32 : 16|16@1- (0.002,0) [-65.536|65.534] "" Vector__XXX
 SG_ DIF_a033_phaseAcurrent m33 : 16|16@1- (1,0) [-32768|32767] "" Vector__XXX
 SG_ DIF_a033_deltaIa m33 : 32|16@1- (1,0) [-32768|32767] "" Vector__XXX
 SG_ DIF_a033_vRefIa m33 : 48|16@1- (0.001,0) [-32.768|32.767] "" Vector__XXX
 SG_ DIF_a034_phaseBcurrent m34 : 16|16@1- (1,0) [-32768|32767] "" Vector__XXX
 SG_ DIF_a034_deltaIb m34 : 32|16@1- (1,0) [-32768|32767] "" Vector__XXX
 SG_ DIF_a034_vRefIb m34 : 48|16@1- (0.001,0) [-32.768|32.767] "" Vector__XXX
 SG_ DIF_a035_phaseAerror m35 : 16|1@1+ (1,0) [0|1] "" Vector__XXX
 SG_ DIF_a035_phaseBerror m35 : 17|1@1+ (1,0) [0|1] "" Vector__XXX
 SG_ DIF_a035_phaseCerror m35 : 18|1@1+ (1,0) [0|1] "" Vector__XXX
 SG_ DIF_a035_standbyCurrent m35 : 19|1@1+ (1,0) [0|1] "" Vector__XXX
 SG_ DIF_a035_unbalancedCurrent m35 : 20|1@1+ (1,0) [0|1] "" Vector__XXX
 SG_ DIF_a035_wontMoveCurrent m35 : 21|1@1+ (1,0) [0|1] "" Vector__XXX
 SG_ DIF_a035_reportingPhase m35 : 22|2@1+ (1,0) [0|3] "" Vector__XXX
 SG_ DIF_a035_noDriveCurrent m35 : 24|1@1+ (1,0) [0|1] "" Vector__XXX
 SG_ DIF_a035_phaseDifference m35 : 25|7@1+ (1,0) [0|127] "" Vector__XXX
 SG_ DIF_a035_phaseCurrent m35 : 32|16@1+ (1,0) [0|65535] "" Vector__XXX
 SG_ DIF_a035_frequency m35 : 48|10@1+ (1,0) [0|1023] "" Vector__XXX
 SG_ DIF_a036_busVoltage m36 : 16|16@1+ (0.1,0) [0|6553.5] "" Vector__XXX
 SG_ DIF_a036_busHighLimit m36 : 32|16@1+ (0.1,0) [0|6553.5] "" Vector__XXX
 SG_ DIF_a037_busVoltage m37 : 16|16@1+ (0.1,0) [0|6553.5] "" Vector__XXX
 SG_ DIF_a037_busLowLimit m37 : 32|16@1+ (0.1,0) [0|6553.5] "" Vector__XXX
 SG_ DIF_a038_vBMS m38 : 16|13@1+ (0.2,0) [0|1638.2] "" Vector__XXX
 SG_ DIF_a038_vBat m38 : 32|13@1+ (0.2,0) [0|1638.2] "" Vector__XXX
 SG_ DIF_a038_iBat m38 : 48|13@1+ (0.5,0) [0|4095.5] "" Vector__XXX
 SG_ DIF_a038_reason m38 : 61|2@1+ (1,0) [0|3] "" Vector__XXX
 SG_ DIF_a040_torque m40 : 16|1@1+ (1,0) [0|1] "" Vector__XXX
 SG_ DIF_a040_capability m40 : 17|1@1+ (1,0) [0|1] "" Vector__XXX
 SG_ DIF_a040_power m40 : 18|1@1+ (1,0) [0|1] "" Vector__XXX
 SG_ DIF_a040_status m40 : 19|1@1+ (1,0) [0|1] "" Vector__XXX
 SG_ DIF_a040_capability2 m40 : 20|1@1+ (1,0) [0|1] "" Vector__XXX
 SG_ DIF_a040_hvStatus m40 : 21|1@1+ (1,0) [0|1] "" Vector__XXX
 SG_ DIF_a040_temperature m40 : 22|1@1+ (1,0) [0|1] "" Vector__XXX
 SG_ DIF_a041_uartRxDataAvailable m41 : 16|1@1+ (1,0) [0|1] "" Vector__XXX
 SG_ DIF_a041_SDC_status_MIA m41 : 17|1@1+ (1,0) [0|1] "" Vector__XXX
 SG_ DIF_a041_diUartRxVersion m41 : 18|4@1+ (1,0) [0|15] "" Vector__XXX
 SG_ DIF_a041_sdcUartRxVersion m41 : 24|4@1+ (1,0) [0|15] "" Vector__XXX
 SG_ DIF_a043_outletTemp m43 : 16|16@1- (0.1,0) [-3276.8|3276.7] "" Vector__XXX
 SG_ DIF_a044_outletTemp m44 : 16|16@1- (0.1,0) [-3276.8|3276.7] "" Vector__XXX
 SG_ DIF_a045_inletTemp m45 : 16|10@1+ (0.25,-60) [-60|195.75] "" Vector__XXX
 SG_ DIF_a045_outletTemp m45 : 26|10@1+ (0.25,-60) [-60|195.75] "" Vector__XXX
 SG_ DIF_a045_heatsinkTemp m45 : 36|10@1+ (0.25,-60) [-60|195.75] "" Vector__XXX
 SG_ DIF_a045_outletTempSlope m45 : 48|8@1- (0.5,0) [-64|63.5] "" Vector__XXX
 SG_ DIF_a046_statorTemp1 m46 : 16|16@1- (0.1,0) [-3276.8|3276.7] "" Vector__XXX
 SG_ DIF_a046_statorTemp2 m46 : 32|16@1- (0.1,0) [-3276.8|3276.7] "" Vector__XXX
 SG_ DIF_a047_statorTemp1 m47 : 16|16@1- (0.1,0) [-3276.8|3276.7] "" Vector__XXX
 SG_ DIF_a047_statorTslope1 m47 : 32|16@1- (0.1,0) [-3276.8|3276.7] "" Vector__XXX
 SG_ DIF_a050_statorTemp1 m50 : 16|16@1- (0.1,0) [-3276.8|3276.7] "" Vector__XXX
 SG_ DIF_a050_statorTemp2 m50 : 32|16@1- (0.1,0) [-3276.8|3276.7] "" Vector__XXX
 SG_ DIF_a052_torque m52 : 16|1@1+ (1,0) [0|1] "" Vector__XXX
 SG_ DIF_a052_capability m52 : 17|1@1+ (1,0) [0|1] "" Vector__XXX
 SG_ DIF_a052_power m52 : 18|1@1+ (1,0) [0|1] "" Vector__XXX
 SG_ DIF_a052_status m52 : 19|1@1+ (1,0) [0|1] "" Vector__XXX
 SG_ DIF_a052_capability2 m52 : 20|1@1+ (1,0) [0|1] "" Vector__XXX
 SG_ DIF_a052_hvStatus m52 : 21|1@1+ (1,0) [0|1] "" Vector__XXX
 SG_ DIF_a052_temperature m52 : 22|1@1+ (1,0) [0|1] "" Vector__XXX
 SG_ DIF_a054_outletTemp m54 : 16|16@1- (0.1,0) [-3276.8|3276.7] "" Vector__XXX
 SG_ DIF_a054_heatsinkTemp m54 : 32|16@1- (0.1,0) [-3276.8|3276.7] "" Vector__XXX
 SG_ DIF_a055_parameterDI m55 : 16|13@1- (0.25,0) [-1024|1023.75] "" Vector__XXX
 SG_ DIF_a055_parameterPM m55 : 32|13@1- (0.25,0) [-1024|1023.75] "" Vector__XXX
 SG_ DIF_a055_torqueType m55 : 45|2@1+ (1,0) [0|3] "" Vector__XXX
 SG_ DIF_a055_motorRPM m55 : 48|16@1- (1,0) [-32768|32767] "" Vector__XXX
 SG_ DIF_a056_pcbTemp m56 : 16|16@1- (0.1,0) [-3276.8|3276.7] "" Vector__XXX
 SG_ DIF_a057_pcbTemp m57 : 16|16@1- (0.1,0) [-3276.8|3276.7] "" Vector__XXX
 SG_ DIF_a058_pcbTemp m58 : 16|10@1+ (0.25,-60) [-60|195.75] "" Vector__XXX
 SG_ DIF_a058_outletTemp m58 : 26|10@1+ (0.25,-60) [-60|195.75] "" Vector__XXX
 SG_ DIF_a058_heatsinkTemp m58 : 36|10@1+ (0.25,-60) [-60|195.75] "" Vector__XXX
 SG_ DIF_a058_pcbTempSlope m58 : 48|8@1- (0.5,0) [-64|63.5] "" Vector__XXX
 SG_ DIF_a059_heatsinkTemp m59 : 16|16@1- (0.1,0) [-3276.8|3276.7] "" Vector__XXX
 SG_ DIF_a060_heatsinkTemp m60 : 16|16@1- (0.1,0) [-3276.8|3276.7] "" Vector__XXX
 SG_ DIF_a061_sensor m61 : 16|2@1+ (1,0) [0|3] "" Vector__XXX
 SG_ DIF_a061_reason m61 : 18|1@1+ (1,0) [0|1] "" Vector__XXX
 SG_ DIF_a061_phTemp m61 : 24|16@1- (0.1,0) [-3276.8|3276.7] "" Vector__XXX
 SG_ DIF_a061_otherTemp m61 : 40|16@1- (0.1,0) [-3276.8|3276.7] "" Vector__XXX
 SG_ DIF_a062_limpReason m62 : 16|6@1+ (1,0) [0|63] "" Vector__XXX
 SG_ DIF_a063_BB_status m63 : 16|1@1+ (1,0) [0|1] "" Vector__XXX
 SG_ DIF_a064_interventionType m64 : 16|4@1+ (1,0) [0|15] "" Vector__XXX
 SG_ DIF_a064_torqueCmdState m64 : 20|4@1+ (1,0) [0|15] "" Vector__XXX
 SG_ DIF_a066_badValue1 m66 : 16|16@1+ (1,0) [0|65535] "" Vector__XXX
 SG_ DIF_a066_badValue2 m66 : 32|16@1+ (1,0) [0|65535] "" Vector__XXX
 SG_ DIF_a066_canID m66 : 48|12@1+ (1,0) [0|4095] "" Vector__XXX
 SG_ DIF_a066_errorType m66 : 60|3@1+ (1,0) [0|7] "" Vector__XXX
 SG_ DIF_a069_motorSpeed m69 : 16|16@1- (1,0) [-32768|32767] "" Vector__XXX
 SG_ DIF_a069_rotorCoolingPower m69 : 32|8@1+ (20,0) [0|5100] "" Vector__XXX
 SG_ DIF_a069_rotorMagnetTemp m69 : 40|10@1+ (0.25,-60) [-60|195.75] "" Vector__XXX
 SG_ DIF_a069_fittedTorqueLimit m69 : 50|13@1- (0.25,0) [-1024|1023.75] "" Vector__XXX
 SG_ DIF_a072_reason m72 : 16|2@1+ (1,0) [0|3] "" Vector__XXX
 SG_ DIF_a073_motorSpeedrpm m73 : 16|16@1- (1,0) [-32768|32767] "" Vector__XXX
 SG_ DIF_a075_motorSpeed m75 : 16|16@1+ (1,0) [0|65535] "" Vector__XXX
 SG_ DIF_a075_absSpeed m75 : 32|16@1+ (1,0) [0|65535] "" Vector__XXX
 SG_ DIF_a076_lvSupplyV m76 : 16|16@1+ (0.001,0) [0|65.535] "" Vector__XXX
 SG_ DIF_a077_lvSupplyV m77 : 16|16@1+ (0.001,0) [0|65.535] "" Vector__XXX
 SG_ DIF_a078_adcRefChan m78 : 16|4@1+ (1,0) [0|15] "" Vector__XXX
 SG_ DIF_a078_adcRefLowAvg m78 : 24|16@1+ (1,0) [0|65535] "" Vector__XXX
 SG_ DIF_a079_adcRefChan m79 : 16|4@1+ (1,0) [0|15] "" Vector__XXX
 SG_ DIF_a079_adcRefHighAvg m79 : 24|16@1+ (1,0) [0|65535] "" Vector__XXX
 SG_ DIF_a087_gtwCarConfig m87 : 16|1@1+ (1,0) [0|1] "" Vector__XXX
 SG_ DIF_a087_gtwTime m87 : 17|1@1+ (1,0) [0|1] "" Vector__XXX
 SG_ DIF_a087_gtwUpdateStatus m87 : 18|1@1+ (1,0) [0|1] "" Vector__XXX
 SG_ DIF_a087_gearControl m87 : 19|1@1+ (1,0) [0|1] "" Vector__XXX
 SG_ DIF_a087_carState m87 : 20|1@1+ (1,0) [0|1] "" Vector__XXX
 SG_ DIF_a090_reason m90 : 16|1@1+ (1,0) [0|1] "" Vector__XXX
 SG_ DIF_a090_systemState m90 : 17|1@1+ (1,0) [0|1] "" Vector__XXX
 SG_ DIF_a090_state m90 : 18|1@1+ (1,0) [0|1] "" Vector__XXX
 SG_ DIF_a090_locState m90 : 19|1@1+ (1,0) [0|1] "" Vector__XXX
 SG_ DIF_a090_state2 m90 : 20|1@1+ (1,0) [0|1] "" Vector__XXX
 SG_ DIF_a090_state4 m90 : 21|1@1+ (1,0) [0|1] "" Vector__XXX
 SG_ DIF_a091_ESP_brakeTorque m91 : 16|1@1+ (1,0) [0|1] "" Vector__XXX
 SG_ DIF_a091_ESP_wheelSpeeds m91 : 17|1@1+ (1,0) [0|1] "" Vector__XXX
 SG_ DIF_a091_ESP_wheelRotation m91 : 18|1@1+ (1,0) [0|1] "" Vector__XXX
 SG_ DIF_a091_ESP_motorLimits m91 : 19|1@1+ (1,0) [0|1] "" Vector__XXX
 SG_ DIF_a091_ESP_offsets m91 : 20|1@1+ (1,0) [0|1] "" Vector__XXX
 SG_ DIF_a091_ESP_status m91 : 21|1@1+ (1,0) [0|1] "" Vector__XXX
 SG_ DIF_a091_ESP_party3 m91 : 22|1@1+ (1,0) [0|1] "" Vector__XXX
 SG_ DIF_a092_bmsStatus m92 : 16|1@1+ (1,0) [0|1] "" Vector__XXX
 SG_ DIF_a092_bmsDriveLimits m92 : 17|1@1+ (1,0) [0|1] "" Vector__XXX
 SG_ DIF_a092_bmsHvBusStatus m92 : 18|1@1+ (1,0) [0|1] "" Vector__XXX
 SG_ DIF_a092_bmsPowerAvailable m92 : 19|1@1+ (1,0) [0|1] "" Vector__XXX
 SG_ DIF_a092_bmsBmbMinMax m92 : 20|1@1+ (1,0) [0|1] "" Vector__XXX
 SG_ DIF_a092_bmsSocStatus m92 : 21|1@1+ (1,0) [0|1] "" Vector__XXX
 SG_ DIF_a092_bmsThermalStatus m92 : 22|1@1+ (1,0) [0|1] "" Vector__XXX
 SG_ DIF_a092_bmsCtrStatus m92 : 23|1@1+ (1,0) [0|1] "" Vector__XXX
 SG_ DIF_a092_bmsVoltageRegGain m92 : 24|1@1+ (1,0) [0|1] "" Vector__XXX
 SG_ DIF_a092_bmsPackConfig m92 : 25|1@1+ (1,0) [0|1] "" Vector__XXX
 SG_ DIF_a092_bmsSystemStatus m92 : 26|1@1+ (1,0) [0|1] "" Vector__XXX
 SG_ DIF_a094_canID m94 : 16|12@1+ (1,0) [0|4095] "" Vector__XXX
 SG_ DIF_a094_errorType m94 : 28|3@1+ (1,0) [0|7] "" Vector__XXX
 SG_ DIF_a094_badValue1 m94 : 32|16@1+ (1,0) [0|65535] "" Vector__XXX
 SG_ DIF_a094_badValue2 m94 : 48|16@1+ (1,0) [0|65535] "" Vector__XXX
 SG_ DIF_a096_const_fast m96 : 16|1@1+ (1,0) [0|1] "" Vector__XXX
 SG_ DIF_a096_text_fast m96 : 17|1@1+ (1,0) [0|1] "" Vector__XXX
 SG_ DIF_a096_text_flash m96 : 18|1@1+ (1,0) [0|1] "" Vector__XXX
 SG_ DIF_a096_mem_data m96 : 19|1@1+ (1,0) [0|1] "" Vector__XXX
 SG_ DIF_a096_mem_regs m96 : 20|1@1+ (1,0) [0|1] "" Vector__XXX
 SG_ DIF_a096_boot_flash m96 : 21|1@1+ (1,0) [0|1] "" Vector__XXX
 SG_ DIF_a096_word1 m96 : 24|16@1+ (1,0) [0|65535] "" Vector__XXX
 SG_ DIF_a096_word2 m96 : 40|16@1+ (1,0) [0|65535] "" Vector__XXX
 SG_ DIF_a097_errorType m97 : 16|3@1+ (1,0) [0|7] "" Vector__XXX
 SG_ DIF_a097_lineNumber m97 : 24|16@1+ (1,0) [0|65535] "" Vector__XXX
 SG_ DIF_a097_argument m97 : 40|16@1+ (1,0) [0|65535] "" Vector__XXX
 SG_ DIF_a098_pwmCount m98 : 16|16@1+ (1,0) [0|65535] "" Vector__XXX
 SG_ DIF_a098_fluxState m98 : 32|4@1+ (1,0) [0|15] "" Vector__XXX
 SG_ DIF_a103_fluidTorDeltaT m103 : 16|8@1- (2.007874,68.2677154541) [-188.740156546|323.267713454] "" Vector__XXX
 SG_ DIF_a103_noFlowDetected m103 : 24|1@1+ (1,0) [0|1] "" Vector__XXX
 SG_ DIF_a103_lowFlowDetected m103 : 25|1@1+ (1,0) [0|1] "" Vector__XXX
 SG_ DIF_a103_fluidImplausible m103 : 26|1@1+ (1,0) [0|1] "" Vector__XXX
 SG_ DIF_a103_inverterTemp m103 : 27|8@1- (2.007874,68.2677154541) [-188.740156546|323.267713454] "" Vector__XXX
 SG_ DIF_a103_rmsCurrent m103 : 35|10@1- (12.8199605942,0) [-6563.81982423|6550.99986364] "" Vector__XXX
 SG_ DIF_a103_ambientTemp m103 : 45|7@1- (1.5873016119,11.1111106873) [-90.4761924743|111.111112237] "" Vector__XXX
 SG_ DIF_a103_sensorTempEst m103 : 52|8@1- (1.25984251499,40.31496) [-120.944881919|200.314959404] "" Vector__XXX
 SG_ DIF_a107_fpgaVersion m107 : 16|16@1+ (1,0) [0|65535] "" Vector__XXX
 SG_ DIF_a107_fpgaBootVersion m107 : 32|16@1+ (1,0) [0|65535] "" Vector__XXX
 SG_ DIF_a107_fpgaMasterActive m107 : 48|1@1+ (1,0) [0|1] "" Vector__XXX
 SG_ DIF_a107_fpgaFaultActive m107 : 49|1@1+ (1,0) [0|1] "" Vector__XXX
 SG_ DIF_a107_fpgaWarningActive m107 : 50|1@1+ (1,0) [0|1] "" Vector__XXX
 SG_ DIF_a108_fromState m108 : 16|8@1+ (1,0) [0|255] "" Vector__XXX
 SG_ DIF_a108_toState m108 : 24|8@1+ (1,0) [0|255] "" Vector__XXX
 SG_ DIF_a108_blockingAlert m108 : 32|8@1+ (1,0) [0|255] "" Vector__XXX
 SG_ DIF_a110_EPBL_status m110 : 16|1@1+ (1,0) [0|1] "" Vector__XXX
 SG_ DIF_a110_EPBR_status m110 : 17|1@1+ (1,0) [0|1] "" Vector__XXX
 SG_ DIF_a111_phAcalib m111 : 16|16@1+ (1,0) [0|65535] "" Vector__XXX
 SG_ DIF_a111_phBcalib m111 : 32|16@1+ (1,0) [0|65535] "" Vector__XXX
 SG_ DIF_a112_phaseAcurrent m112 : 16|16@1+ (1,0) [0|65535] "" Vector__XXX
 SG_ DIF_a112_phaseBcurrent m112 : 32|16@1+ (1,0) [0|65535] "" Vector__XXX
 SG_ DIF_a113_heatsink1Temp m113 : 16|16@1- (0.1,0) [-3276.8|3276.7] "" Vector__XXX
 SG_ DIF_a113_heatsink2Temp m113 : 32|16@1- (0.1,0) [-3276.8|3276.7] "" Vector__XXX
 SG_ DIF_a113_heatsink3Temp m113 : 48|16@1- (0.1,0) [-3276.8|3276.7] "" Vector__XXX
 SG_ DIF_a115_faultAddress m115 : 16|32@1+ (1,0) [0|4294967295] "" Vector__XXX
 SG_ DIF_a115_isWriteNotRead m115 : 48|1@1+ (1,0) [0|1] "" Vector__XXX
 SG_ DIF_a117_torque m117 : 16|1@1+ (1,0) [0|1] "" Vector__XXX
 SG_ DIF_a117_slaveCommand m117 : 17|1@1+ (1,0) [0|1] "" Vector__XXX
 SG_ DIF_a117_power m117 : 18|1@1+ (1,0) [0|1] "" Vector__XXX
 SG_ DIF_a117_slaveCommand2 m117 : 19|1@1+ (1,0) [0|1] "" Vector__XXX
 SG_ DIF_a117_speed m117 : 20|1@1+ (1,0) [0|1] "" Vector__XXX
 SG_ DIF_a117_chassisControl m117 : 21|1@1+ (1,0) [0|1] "" Vector__XXX
 SG_ DIF_a117_systemStatus m117 : 22|1@1+ (1,0) [0|1] "" Vector__XXX
 SG_ DIF_a117_temperature m117 : 23|1@1+ (1,0) [0|1] "" Vector__XXX
 SG_ DIF_a117_vehicle m117 : 24|1@1+ (1,0) [0|1] "" Vector__XXX
 SG_ DIF_a117_AddTcLimit m117 : 26|1@1+ (1,0) [0|1] "" Vector__XXX
 SG_ DIF_a117_dixCommand m117 : 27|1@1+ (1,0) [0|1] "" Vector__XXX
 SG_ DIF_a117_odometerStatus m117 : 30|1@1+ (1,0) [0|1] "" Vector__XXX
 SG_ DIF_a117_maxRatedPower m117 : 31|1@1+ (1,0) [0|1] "" Vector__XXX
 SG_ DIF_a119_hvpFaults m119 : 16|1@1+ (1,0) [0|1] "" Vector__XXX
 SG_ DIF_a120_dcLinkInfo m120 : 16|1@1+ (1,0) [0|1] "" Vector__XXX
 SG_ DIF_a121_badRegReason m121 : 16|3@1+ (1,0) [0|7] "" Vector__XXX
 SG_ DIF_a121_torqueDelta m121 : 19|13@1- (0.25,0) [-1024|1023.75] "" Vector__XXX
 SG_ DIF_a121_badCurrent m121 : 32|16@1- (0.1,0) [-3276.8|3276.7] "" Vector__XXX
 SG_ DIF_a121_badFlux m121 : 48|16@1+ (0.0001,0) [0|6.5535] "" Vector__XXX
 SG_ DIF_a123_lossReason m123 : 16|3@1+ (1,0) [0|7] "" Vector__XXX
 SG_ DIF_a123_busVoltage m123 : 19|6@1+ (4,250) [250|502] "" Vector__XXX
 SG_ DIF_a123_badFlux m123 : 25|7@1+ (0.0015,0) [0|0.1905] "" Vector__XXX
 SG_ DIF_a123_lossRequest m123 : 32|7@1+ (0.1,0) [0|12.7] "" Vector__XXX
 SG_ DIF_a123_badCurrent m123 : 39|9@1- (10,0) [-2560|2550] "" Vector__XXX
 SG_ DIF_a123_motorRPM m123 : 48|8@1- (150,0) [-19200|19050] "" Vector__XXX
 SG_ DIF_a123_varianceD m123 : 56|4@1+ (20,0) [0|300] "" Vector__XXX
 SG_ DIF_a123_varianceQ m123 : 60|4@1+ (20,0) [0|300] "" Vector__XXX
 SG_ DIF_a126_limpReason m126 : 16|6@1+ (1,0) [0|63] "" Vector__XXX
 SG_ DIF_a127_gpoReason m127 : 16|4@1+ (1,0) [0|15] "" Vector__XXX
 SG_ DIF_a127_temp m127 : 24|16@1- (0.1,0) [-3276.8|3276.7] "" Vector__XXX
 SG_ DIF_a133_capacitorTemp m133 : 16|16@1- (0.1,0) [-3276.8|3276.7] "" Vector__XXX
 SG_ DIF_a133_badValue1 m133 : 32|16@1- (0.1,0) [-3276.8|3276.7] "" Vector__XXX
 SG_ DIF_a133_badValue2 m133 : 48|16@1- (0.1,0) [-3276.8|3276.7] "" Vector__XXX
 SG_ DIF_a134_wheelSpeedDiffFrL m134 : 16|12@1- (0.0625,0) [-128|127.9375] "" Vector__XXX
 SG_ DIF_a134_wheelSpeedDiffFrR m134 : 28|12@1- (0.0625,0) [-128|127.9375] "" Vector__XXX
 SG_ DIF_a134_wheelSpeedDiffReL m134 : 40|12@1- (0.0625,0) [-128|127.9375] "" Vector__XXX
 SG_ DIF_a134_wheelSpeedDiffReR m134 : 52|12@1- (0.0625,0) [-128|127.9375] "" Vector__XXX
 SG_ DIF_a136_spiError_BL m136 : 16|1@1+ (1,0) [0|1] "" Vector__XXX
 SG_ DIF_a136_crcError_BL m136 : 17|1@1+ (1,0) [0|1] "" Vector__XXX
 SG_ DIF_a136_busyError_BL m136 : 18|1@1+ (1,0) [0|1] "" Vector__XXX
 SG_ DIF_a136_spiError_BH m136 : 19|1@1+ (1,0) [0|1] "" Vector__XXX
 SG_ DIF_a136_crcError_BH m136 : 20|1@1+ (1,0) [0|1] "" Vector__XXX
 SG_ DIF_a136_busyError_BH m136 : 21|1@1+ (1,0) [0|1] "" Vector__XXX
 SG_ DIF_a136_spiError_CL m136 : 22|1@1+ (1,0) [0|1] "" Vector__XXX
 SG_ DIF_a136_crcError_CL m136 : 23|1@1+ (1,0) [0|1] "" Vector__XXX
 SG_ DIF_a136_busyError_CL m136 : 24|1@1+ (1,0) [0|1] "" Vector__XXX
 SG_ DIF_a136_spiError_CH m136 : 25|1@1+ (1,0) [0|1] "" Vector__XXX
 SG_ DIF_a136_crcError_CH m136 : 26|1@1+ (1,0) [0|1] "" Vector__XXX
 SG_ DIF_a136_busyError_CH m136 : 27|1@1+ (1,0) [0|1] "" Vector__XXX
 SG_ DIF_a136_spiError_AL m136 : 28|1@1+ (1,0) [0|1] "" Vector__XXX
 SG_ DIF_a136_crcError_AL m136 : 29|1@1+ (1,0) [0|1] "" Vector__XXX
 SG_ DIF_a136_busyError_AL m136 : 30|1@1+ (1,0) [0|1] "" Vector__XXX
 SG_ DIF_a136_spiError_AH m136 : 31|1@1+ (1,0) [0|1] "" Vector__XXX
 SG_ DIF_a136_crcError_AH m136 : 32|1@1+ (1,0) [0|1] "" Vector__XXX
 SG_ DIF_a136_busyError_AH m136 : 33|1@1+ (1,0) [0|1] "" Vector__XXX
 SG_ DIF_a144_autopilot m144 : 16|1@1+ (1,0) [0|1] "" Vector__XXX
 SG_ DIF_a144_chassisType m144 : 17|1@1+ (1,0) [0|1] "" Vector__XXX
 SG_ DIF_a144_drivetrainType m144 : 18|1@1+ (1,0) [0|1] "" Vector__XXX
 SG_ DIF_a144_packEnergy m144 : 19|1@1+ (1,0) [0|1] "" Vector__XXX
 SG_ DIF_a144_packPerformanceDeviatio m144 : 20|1@1+ (1,0) [0|1] "" Vector__XXX
 SG_ DIF_a144_performancePackage m144 : 21|1@1+ (1,0) [0|1] "" Vector__XXX
 SG_ DIF_a144_vdcType m144 : 22|1@1+ (1,0) [0|1] "" Vector__XXX
 SG_ DIF_a144_brakeHWType m144 : 23|1@1+ (1,0) [0|1] "" Vector__XXX
 SG_ DIF_a144_inverterHardware m144 : 24|1@1+ (1,0) [0|1] "" Vector__XXX
 SG_ DIF_a144_cabinPTCHeaterType m144 : 25|1@1+ (1,0) [0|1] "" Vector__XXX
 SG_ DIF_a144_frunkLatchType m144 : 26|1@1+ (1,0) [0|1] "" Vector__XXX
 SG_ DIF_a144_platformMaxBusVoltage m144 : 27|1@1+ (1,0) [0|1] "" Vector__XXX
 SG_ DIF_a144_oilPump1HwType m144 : 28|1@1+ (1,0) [0|1] "" Vector__XXX
 SG_ DIF_a144_oilPump2HwType m144 : 29|1@1+ (1,0) [0|1] "" Vector__XXX
 SG_ DIF_a144_heatsinkType m144 : 30|1@1+ (1,0) [0|1] "" Vector__XXX
 SG_ DIF_a144_softPerformanceLimit m144 : 31|1@1+ (1,0) [0|1] "" Vector__XXX
 SG_ DIF_a144_brakeActuationType m144 : 32|1@1+ (1,0) [0|1] "" Vector__XXX
 SG_ DIF_a144_dasHw m144 : 33|1@1+ (1,0) [0|1] "" Vector__XXX
 SG_ DIF_a144_chassisSubType m144 : 34|1@1+ (1,0) [0|1] "" Vector__XXX
 SG_ DIF_a147_overtorque1UsedCount m147 : 16|8@1+ (1,0) [0|255] "" Vector__XXX
 SG_ DIF_a147_overtorque2UsedCount m147 : 24|10@1+ (1,0) [0|1023] "" Vector__XXX
 SG_ DIF_a147_accumulatedWear m147 : 34|10@1+ (0.005,0) [0|5.115] "" Vector__XXX
 SG_ DIF_a147_wearIsValid m147 : 44|1@1+ (1,0) [0|1] "" Vector__XXX
 SG_ DIF_a149_flow m149 : 16|8@1+ (0.1,0) [0|25.5] "" Vector__XXX
 SG_ DIF_a149_voltage m149 : 24|8@1+ (0.1,0) [0|25.5] "" Vector__XXX
 SG_ DIF_a149_temperature m149 : 32|8@1+ (1,-40) [-40|215] "" Vector__XXX
 SG_ DIF_a149_state m149 : 40|3@1+ (1,0) [0|7] "" Vector__XXX
 SG_ DIF_a149_fluidTempSNA m149 : 43|1@1+ (1,0) [0|1] "" Vector__XXX
 SG_ DIF_a149_insufficientFlow m149 : 44|1@1+ (1,0) [0|1] "" Vector__XXX
 SG_ DIF_a149_motorOpenPhase m149 : 45|1@1+ (1,0) [0|1] "" Vector__XXX
 SG_ DIF_a149_motorShorted m149 : 46|1@1+ (1,0) [0|1] "" Vector__XXX
 SG_ DIF_a149_motorFlowSNA m149 : 47|1@1+ (1,0) [0|1] "" Vector__XXX
 SG_ DIF_a149_responseError m149 : 48|1@1+ (1,0) [0|1] "" Vector__XXX
 SG_ DIF_a149_pcbaID m149 : 49|1@1+ (1,0) [0|1] "" Vector__XXX
 SG_ DIF_a150_vBatRawMinusFiltered m150 : 16|10@1- (1,0) [-512|511] "" Vector__XXX
 SG_ DIF_a150_vBatFilteredRate m150 : 32|8@1- (100,0) [-12800|12700] "" Vector__XXX
 SG_ DIF_a150_elapsedMs m150 : 40|8@1+ (1,0) [0|255] "" Vector__XXX
 SG_ DIF_a150_energy m150 : 48|16@1+ (1,0) [0|65535] "" Vector__XXX
 SG_ DIF_a152_errorType m152 : 16|3@1+ (1,0) [0|7] "" Vector__XXX
 SG_ DIF_a152_frameId m152 : 24|8@1+ (1,0) [0|255] "" Vector__XXX
 SG_ DIF_a152_badValue m152 : 32|8@1+ (1,0) [0|255] "" Vector__XXX
 SG_ DIF_a152_expectedValue m152 : 40|8@1+ (1,0) [0|255] "" Vector__XXX
 SG_ DIF_a153_oilFlow m153 : 16|8@1+ (0.1,0) [0|25.5] "" Vector__XXX
 SG_ DIF_a153_oilTemperature m153 : 24|8@1+ (1,-40) [-40|215] "" Vector__XXX
 SG_ DIF_a153_phaseCurrent m153 : 32|8@1+ (0.1,0) [0|25.5] "" Vector__XXX
 SG_ DIF_a153_dcVoltage m153 : 40|8@1+ (0.3,0) [0|76.5] "" Vector__XXX
 SG_ DIF_a153_lowPressPlausibility m153 : 48|5@1+ (3.3,0) [0|102.3] "" Vector__XXX
 SG_ DIF_a153_state m153 : 53|3@1+ (1,0) [0|7] "" Vector__XXX
 SG_ DIF_a153_oilPumpAlert m153 : 56|5@1+ (1,0) [0|31] "" Vector__XXX
 SG_ DIF_a153_reason m153 : 61|3@1+ (1,0) [0|7] "" Vector__XXX
 SG_ DIF_a154_motorRPM m154 : 16|16@1- (1,0) [-32768|32767] "" Vector__XXX
 SG_ DIF_a154_phaseError m154 : 32|8@1- (0.004,0) [-0.512|0.508] "" Vector__XXX
 SG_ DIF_a154_commonGain m154 : 40|8@1+ (0.02,0) [0|5.1] "" Vector__XXX
 SG_ DIF_a154_noCalibration m154 : 48|1@1+ (1,0) [0|1] "" Vector__XXX
 SG_ DIF_a154_noPhaseLock m154 : 49|1@1+ (1,0) [0|1] "" Vector__XXX
 SG_ DIF_a154_noCarrier m154 : 50|1@1+ (1,0) [0|1] "" Vector__XXX
 SG_ DIF_a154_notReady m154 : 51|1@1+ (1,0) [0|1] "" Vector__XXX
 SG_ DIF_a154_errorTableInvalid m154 : 52|1@1+ (1,0) [0|1] "" Vector__XXX
 SG_ DIF_a154_carrierOffset m154 : 53|1@1+ (1,0) [0|1] "" Vector__XXX
 SG_ DIF_a154_trackerIrrational m154 : 54|1@1+ (1,0) [0|1] "" Vector__XXX
 SG_ DIF_a154_claMIA m154 : 55|1@1+ (1,0) [0|1] "" Vector__XXX
 SG_ DIF_a155_sensors m155 : 16|1@1+ (1,0) [0|1] "" Vector__XXX
 SG_ DIF_a155_coolant m155 : 17|1@1+ (1,0) [0|1] "" Vector__XXX
 SG_ DIF_a155_LVPowerState m155 : 18|1@1+ (1,0) [0|1] "" Vector__XXX
 SG_ DIF_a155_vehicleStatus m155 : 19|1@1+ (1,0) [0|1] "" Vector__XXX
 SG_ DIF_a155_status m155 : 20|1@1+ (1,0) [0|1] "" Vector__XXX
 SG_ DIF_a155_leftDoorStatus m155 : 21|1@1+ (1,0) [0|1] "" Vector__XXX
 SG_ DIF_a155_rightDoorStatus m155 : 22|1@1+ (1,0) [0|1] "" Vector__XXX
 SG_ DIF_a155_vcleftSwitchStatus m155 : 23|1@1+ (1,0) [0|1] "" Vector__XXX
 SG_ DIF_a155_restraintStatus m155 : 24|1@1+ (1,0) [0|1] "" Vector__XXX
 SG_ DIF_a155_systemStatus m155 : 25|1@1+ (1,0) [0|1] "" Vector__XXX
 SG_ DIF_a155_prndStatus m155 : 26|1@1+ (1,0) [0|1] "" Vector__XXX
 SG_ DIF_a155_liftgateStatus m155 : 27|1@1+ (1,0) [0|1] "" Vector__XXX
 SG_ DIF_a157_RCM_inertial1 m157 : 16|1@1+ (1,0) [0|1] "" Vector__XXX
 SG_ DIF_a157_RCM_inertial2 m157 : 17|1@1+ (1,0) [0|1] "" Vector__XXX
 SG_ DIF_a158_IBST_party1 m158 : 16|1@1+ (1,0) [0|1] "" Vector__XXX
 SG_ DIF_a158_BUS1_IBST_status m158 : 17|1@1+ (1,0) [0|1] "" Vector__XXX
 SG_ DIF_a158_BUS2_IBST_status m158 : 18|1@1+ (1,0) [0|1] "" Vector__XXX
 SG_ DIF_a160_vBatRawMinusFiltered m160 : 16|10@1- (1,0) [-512|511] "" Vector__XXX
 SG_ DIF_a160_vBatFilteredRate m160 : 32|8@1- (100,0) [-12800|12700] "" Vector__XXX
 SG_ DIF_a160_elapsedMs m160 : 40|8@1+ (1,0) [0|255] "" Vector__XXX
 SG_ DIF_a160_energy m160 : 48|16@1+ (1,0) [0|65535] "" Vector__XXX
 SG_ DIF_a161_EPAS3P_sysStatus m161 : 16|1@1+ (1,0) [0|1] "" Vector__XXX
 SG_ DIF_a161_EPAS3P_angleCalib m161 : 17|1@1+ (1,0) [0|1] "" Vector__XXX
 SG_ DIF_a202_reason m202 : 16|4@1+ (1,0) [0|15] "" Vector__XXX
 SG_ DIF_a202_movement m202 : 20|9@1+ (0.005,0) [0|2.555] "" Vector__XXX
 SG_ DIF_a202_sysStateExitCondition m202 : 32|5@1+ (1,0) [0|31] "" Vector__XXX
 SG_ DIF_a233_missedMsgCount m233 : 16|4@1+ (1,0) [0|15] "" Vector__XXX
 SG_ DIF_a233_serviceModeActive m233 : 20|1@1+ (1,0) [0|1] "" Vector__XXX
 SG_ DIF_a234_PCS_dcdcStatus m234 : 16|1@1+ (1,0) [0|1] "" Vector__XXX
 SG_ DIF_a236_states m236 : 16|1@1+ (1,0) [0|1] "" Vector__XXX
 SG_ DIF_a242_RotorOffset m242 : 16|1@1+ (1,0) [0|1] "" Vector__XXX
 SG_ DIF_a242_RotorFlux m242 : 17|1@1+ (1,0) [0|1] "" Vector__XXX
 SG_ DIF_a242_ResolverError m242 : 18|1@1+ (1,0) [0|1] "" Vector__XXX
 SG_ DIF_a244_desatHighSide m244 : 16|1@1+ (1,0) [0|1] "" Vector__XXX
 SG_ DIF_a244_desatLowSide m244 : 17|1@1+ (1,0) [0|1] "" Vector__XXX
 SG_ DIF_a244_singleSwitchShort m244 : 18|1@1+ (1,0) [0|1] "" Vector__XXX
 SG_ DIF_a244_flybackFault m244 : 19|1@1+ (1,0) [0|1] "" Vector__XXX
 SG_ DIF_a244_postShortTestFailed m244 : 20|1@1+ (1,0) [0|1] "" Vector__XXX
 SG_ DIF_a244_udsSelfTest m244 : 21|1@1+ (1,0) [0|1] "" Vector__XXX
 SG_ DIF_a244_irSensorV m244 : 24|6@1+ (0.1,0) [0|6.3] "" Vector__XXX
 SG_ DIF_a244_gateDriveICUndervoltage m244 : 30|1@1+ (1,0) [0|1] "" Vector__XXX
 SG_ DIF_a244_plausibleSingleSwitchSh m244 : 31|1@1+ (1,0) [0|1] "" Vector__XXX
 SG_ DIF_a246_atSpeedDIResetCount m246 : 16|4@1+ (1,4294967295) [4294967295|4294967310] "" Vector__XXX
 SG_ DIF_a246_didPMCauseASC m246 : 20|1@1+ (1,0) [0|1] "" Vector__XXX
 SG_ DIF_a246_currentSensorRational m246 : 21|1@1+ (1,0) [0|1] "" Vector__XXX
 SG_ DIF_a246_observerDetectedLS3PS m246 : 22|1@1+ (1,0) [0|1] "" Vector__XXX
 SG_ DIF_a246_hvIsGood m246 : 23|1@1+ (1,0) [0|1] "" Vector__XXX
 SG_ DIF_a246_lvIsGood m246 : 24|1@1+ (1,0) [0|1] "" Vector__XXX
 SG_ DIF_a246_codeBranch m246 : 25|2@1+ (1,0) [0|3] "" Vector__XXX
 SG_ DIF_a246_motorRPM m246 : 32|8@1- (150,0) [-19200|19050] "" Vector__XXX
 SG_ DIF_a246_eepromOffsetIa m246 : 40|6@1- (0.763,0) [-24.416|23.653] "" Vector__XXX
 SG_ DIF_a246_eepromOffsetIb m246 : 48|6@1- (0.763,0) [-24.416|23.653] "" Vector__XXX
 SG_ DIF_a247_rotorOffsetEst m247 : 16|10@1- (0.05,0) [-25.6|25.55] "" Vector__XXX
 SG_ DIF_a247_motorRPM m247 : 32|16@1- (1,0) [-32768|32767] "" Vector__XXX
 SG_ DIF_a247_torqueMotor m247 : 48|16@1- (1,0) [-32768|32767] "" Vector__XXX
 SG_ DIF_a251_oilFlow m251 : 16|8@1+ (0.1,0) [0|25.5] "" Vector__XXX
 SG_ DIF_a251_oilTemperature m251 : 24|8@1+ (1,-40) [-40|215] "" Vector__XXX
 SG_ DIF_a251_dcVoltage m251 : 32|8@1+ (0.3,0) [0|76.5] "" Vector__XXX
 SG_ DIF_a251_dcCurrent m251 : 40|8@1+ (0.1,0) [0|25.5] "" Vector__XXX
 SG_ DIF_a251_phaseCurrent m251 : 48|8@1+ (0.1,0) [0|25.5] "" Vector__XXX
 SG_ DIF_a251_leadAngle m251 : 56|4@1+ (1.875,0) [0|28.125] "" Vector__XXX
 SG_ DIF_a251_reason m251 : 60|3@1+ (1,0) [0|7] "" Vector__XXX

BO_ 854 DIF_alertMatrix1: 8 DIF
 SG_ DIF_a001_hwPhaseAgateDrive : 0|1@1+ (1,0) [0|1] "" Vector__XXX
 SG_ DIF_a002_hwPhaseBgateDrive : 1|1@1+ (1,0) [0|1] "" Vector__XXX
 SG_ DIF_a003_hwPhaseCgateDrive : 2|1@1+ (1,0) [0|1] "" Vector__XXX
 SG_ DIF_a004_hwPhaseApeak : 3|1@1+ (1,0) [0|1] "" Vector__XXX
 SG_ DIF_a005_hwPhaseBpeak : 4|1@1+ (1,0) [0|1] "" Vector__XXX
 SG_ DIF_a006_hwPhaseCpeak : 5|1@1+ (1,0) [0|1] "" Vector__XXX
 SG_ DIF_a007_statorAnomalyDetected : 6|1@1+ (1,0) [0|1] "" Vector__XXX
 SG_ DIF_a008_hwEncoderA : 7|1@1+ (1,0) [0|1] "" Vector__XXX
 SG_ DIF_a009_hwEncoderB : 8|1@1+ (1,0) [0|1] "" Vector__XXX
 SG_ DIF_a010_unintendedReset : 9|1@1+ (1,0) [0|1] "" Vector__XXX
 SG_ DIF_a011_swPowerStageNotReady : 10|1@1+ (1,0) [0|1] "" Vector__XXX
 SG_ DIF_a012_hvilNotClosed : 11|1@1+ (1,0) [0|1] "" Vector__XXX
 SG_ DIF_a013_eccError : 12|1@1+ (1,0) [0|1] "" Vector__XXX
 SG_ DIF_a014_activeDamping : 13|1@1+ (1,0) [0|1] "" Vector__XXX
 SG_ DIF_a015_mechSafeStateAnomaly : 14|1@1+ (1,0) [0|1] "" Vector__XXX
 SG_ DIF_a016_safeStateApplied : 15|1@1+ (1,0) [0|1] "" Vector__XXX
 SG_ DIF_a017_hwPedalMonitor : 16|1@1+ (1,0) [0|1] "" Vector__XXX
 SG_ DIF_a018_hwLVSupplyUV : 17|1@1+ (1,0) [0|1] "" Vector__XXX
 SG_ DIF_a020_hwMotorEncoder : 19|1@1+ (1,0) [0|1] "" Vector__XXX
 SG_ DIF_a021_hwBusOV : 20|1@1+ (1,0) [0|1] "" Vector__XXX
 SG_ DIF_a022_hw5vSupplyUV : 21|1@1+ (1,0) [0|1] "" Vector__XXX
 SG_ DIF_a024_selfTest : 23|1@1+ (1,0) [0|1] "" Vector__XXX
 SG_ DIF_a025_phaseApeak : 24|1@1+ (1,0) [0|1] "" Vector__XXX
 SG_ DIF_a026_phaseBpeak : 25|1@1+ (1,0) [0|1] "" Vector__XXX
 SG_ DIF_a027_phaseCpeak : 26|1@1+ (1,0) [0|1] "" Vector__XXX
 SG_ DIF_a028_phaseArms : 27|1@1+ (1,0) [0|1] "" Vector__XXX
 SG_ DIF_a029_phaseBrms : 28|1@1+ (1,0) [0|1] "" Vector__XXX
 SG_ DIF_a030_phaseCrms : 29|1@1+ (1,0) [0|1] "" Vector__XXX
 SG_ DIF_a031_phaseAcurrentOffset : 30|1@1+ (1,0) [0|1] "" Vector__XXX
 SG_ DIF_a032_phaseBcurrentOffset : 31|1@1+ (1,0) [0|1] "" Vector__XXX
 SG_ DIF_a033_phaseAcurrentSensor : 32|1@1+ (1,0) [0|1] "" Vector__XXX
 SG_ DIF_a034_phaseBcurrentSensor : 33|1@1+ (1,0) [0|1] "" Vector__XXX
 SG_ DIF_a035_phaseCurrentBalance : 34|1@1+ (1,0) [0|1] "" Vector__XXX
 SG_ DIF_a036_busOV : 35|1@1+ (1,0) [0|1] "" Vector__XXX
 SG_ DIF_a037_busUV : 36|1@1+ (1,0) [0|1] "" Vector__XXX
 SG_ DIF_a038_busVsensor : 37|1@1+ (1,0) [0|1] "" Vector__XXX
 SG_ DIF_a039_exceptionUndefinedInstr : 38|1@1+ (1,0) [0|1] "" Vector__XXX
 SG_ DIF_a040_difMIA : 39|1@1+ (1,0) [0|1] "" Vector__XXX
 SG_ DIF_a041_sdcMIA : 40|1@1+ (1,0) [0|1] "" Vector__XXX
 SG_ DIF_a042_inletSensor : 41|1@1+ (1,0) [0|1] "" Vector__XXX
 SG_ DIF_a043_outletOT : 42|1@1+ (1,0) [0|1] "" Vector__XXX
 SG_ DIF_a044_outletUT : 43|1@1+ (1,0) [0|1] "" Vector__XXX
 SG_ DIF_a045_outletSensor : 44|1@1+ (1,0) [0|1] "" Vector__XXX
 SG_ DIF_a046_statorOT : 45|1@1+ (1,0) [0|1] "" Vector__XXX
 SG_ DIF_a047_statorSensor1 : 46|1@1+ (1,0) [0|1] "" Vector__XXX
 SG_ DIF_a048_statorSensor2 : 47|1@1+ (1,0) [0|1] "" Vector__XXX
 SG_ DIF_a049_statorSensorDiff : 48|1@1+ (1,0) [0|1] "" Vector__XXX
 SG_ DIF_a050_noStatorSensor : 49|1@1+ (1,0) [0|1] "" Vector__XXX
 SG_ DIF_a052_dirMIA : 51|1@1+ (1,0) [0|1] "" Vector__XXX
 SG_ DIF_a053_unexpectedLatchState : 52|1@1+ (1,0) [0|1] "" Vector__XXX
 SG_ DIF_a054_driveInverterOT : 53|1@1+ (1,0) [0|1] "" Vector__XXX
 SG_ DIF_a055_trqCrossCheck : 54|1@1+ (1,0) [0|1] "" Vector__XXX
 SG_ DIF_a056_ambientOT : 55|1@1+ (1,0) [0|1] "" Vector__XXX
 SG_ DIF_a057_ambientUT : 56|1@1+ (1,0) [0|1] "" Vector__XXX
 SG_ DIF_a058_ambientSensor : 57|1@1+ (1,0) [0|1] "" Vector__XXX
 SG_ DIF_a059_heatsinkOT : 58|1@1+ (1,0) [0|1] "" Vector__XXX
 SG_ DIF_a060_heatsinkUT : 59|1@1+ (1,0) [0|1] "" Vector__XXX
 SG_ DIF_a061_heatsinkSensor : 60|1@1+ (1,0) [0|1] "" Vector__XXX
 SG_ DIF_a062_systemLimpMode : 61|1@1+ (1,0) [0|1] "" Vector__XXX
 SG_ DIF_a063_bbMIA : 62|1@1+ (1,0) [0|1] "" Vector__XXX
 SG_ DIF_a064_torqueIntervention : 63|1@1+ (1,0) [0|1] "" Vector__XXX

BO_ 855 DIF_alertMatrix2: 8 DIF
 SG_ DIF_a065_canHardwareBusB : 0|1@1+ (1,0) [0|1] "" Vector__XXX
 SG_ DIF_a066_canDataBusB : 1|1@1+ (1,0) [0|1] "" Vector__XXX
 SG_ DIF_a067_canOverrunBusB : 2|1@1+ (1,0) [0|1] "" Vector__XXX
 SG_ DIF_a069_rotorTempLimit : 4|1@1+ (1,0) [0|1] "" Vector__XXX
 SG_ DIF_a070_udsTransactionInitiated : 5|1@1+ (1,0) [0|1] "" Vector__XXX
 SG_ DIF_a071_busDisconnected : 6|1@1+ (1,0) [0|1] "" Vector__XXX
 SG_ DIF_a072_gateDriveFaultCounter : 7|1@1+ (1,0) [0|1] "" Vector__XXX
 SG_ DIF_a073_motorSpeed : 8|1@1+ (1,0) [0|1] "" Vector__XXX
 SG_ DIF_a074_motorEncoder : 9|1@1+ (1,0) [0|1] "" Vector__XXX
 SG_ DIF_a075_motorSpeedMismatch : 10|1@1+ (1,0) [0|1] "" Vector__XXX
 SG_ DIF_a076_lvSupplyOV : 11|1@1+ (1,0) [0|1] "" Vector__XXX
 SG_ DIF_a077_lvSupplyUV : 12|1@1+ (1,0) [0|1] "" Vector__XXX
 SG_ DIF_a078_adcRefLow : 13|1@1+ (1,0) [0|1] "" Vector__XXX
 SG_ DIF_a079_adcRefHigh : 14|1@1+ (1,0) [0|1] "" Vector__XXX
 SG_ DIF_a081_P0BFF_DIF_EM_CurrentHig : 16|1@1+ (1,0) [0|1] "" Vector__XXX
 SG_ DIF_a082_P7837_DIF_ECU_DemoTimer : 17|1@1+ (1,0) [0|1] "" Vector__XXX
 SG_ DIF_a083_PABCD_DIF_ECU_DemoWindo : 18|1@1+ (1,0) [0|1] "" Vector__XXX
 SG_ DIF_a084_eccTestData0 : 19|1@1+ (1,0) [0|1] "" Vector__XXX
 SG_ DIF_a086_activeDischargeOn : 21|1@1+ (1,0) [0|1] "" Vector__XXX
 SG_ DIF_a087_gtwMIA : 22|1@1+ (1,0) [0|1] "" Vector__XXX
 SG_ DIF_a088_uiMIA : 23|1@1+ (1,0) [0|1] "" Vector__XXX
 SG_ DIF_a090_pmMIA : 25|1@1+ (1,0) [0|1] "" Vector__XXX
 SG_ DIF_a091_espMIA : 26|1@1+ (1,0) [0|1] "" Vector__XXX
 SG_ DIF_a092_bmsMIA : 27|1@1+ (1,0) [0|1] "" Vector__XXX
 SG_ DIF_a093_canHardwareBusA : 28|1@1+ (1,0) [0|1] "" Vector__XXX
 SG_ DIF_a094_canDataBusA : 29|1@1+ (1,0) [0|1] "" Vector__XXX
 SG_ DIF_a095_canOverrunBusA : 30|1@1+ (1,0) [0|1] "" Vector__XXX
 SG_ DIF_a096_memoryError : 31|1@1+ (1,0) [0|1] "" Vector__XXX
 SG_ DIF_a097_eepromError : 32|1@1+ (1,0) [0|1] "" Vector__XXX
 SG_ DIF_a098_intTimeTooLong : 33|1@1+ (1,0) [0|1] "" Vector__XXX
 SG_ DIF_a099_threadOverrun : 34|1@1+ (1,0) [0|1] "" Vector__XXX
 SG_ DIF_a100_assertion : 35|1@1+ (1,0) [0|1] "" Vector__XXX
 SG_ DIF_a101_eccTestData1 : 36|1@1+ (1,0) [0|1] "" Vector__XXX
 SG_ DIF_a102_exceptionPrefetchAbort : 37|1@1+ (1,0) [0|1] "" Vector__XXX
 SG_ DIF_a103_lowFlow : 38|1@1+ (1,0) [0|1] "" Vector__XXX
 SG_ DIF_a107_fpgaError : 42|1@1+ (1,0) [0|1] "" Vector__XXX
 SG_ DIF_a108_stateTrans : 43|1@1+ (1,0) [0|1] "" Vector__XXX
 SG_ DIF_a109_ahbWriteError : 44|1@1+ (1,0) [0|1] "" Vector__XXX
 SG_ DIF_a110_brakeMIA : 45|1@1+ (1,0) [0|1] "" Vector__XXX
 SG_ DIF_a111_badPhaseSensorCalib : 46|1@1+ (1,0) [0|1] "" Vector__XXX
 SG_ DIF_a112_noPhaseCurrent : 47|1@1+ (1,0) [0|1] "" Vector__XXX
 SG_ DIF_a113_noFuncHeatsinkSensor : 48|1@1+ (1,0) [0|1] "" Vector__XXX
 SG_ DIF_a114_exceptionDataAbort : 49|1@1+ (1,0) [0|1] "" Vector__XXX
 SG_ DIF_a115_exceptionDataAbort2 : 50|1@1+ (1,0) [0|1] "" Vector__XXX
 SG_ DIF_a116_highSpeedWearCounter : 51|1@1+ (1,0) [0|1] "" Vector__XXX
 SG_ DIF_a117_diMIA : 52|1@1+ (1,0) [0|1] "" Vector__XXX
 SG_ DIF_a119_hvpMIA : 54|1@1+ (1,0) [0|1] "" Vector__XXX
 SG_ DIF_a120_hvlinkMIA : 55|1@1+ (1,0) [0|1] "" Vector__XXX
 SG_ DIF_a121_motorControlRegulation : 56|1@1+ (1,0) [0|1] "" Vector__XXX
 SG_ DIF_a122_highStackUsage : 57|1@1+ (1,0) [0|1] "" Vector__XXX
 SG_ DIF_a123_lossMotorControl : 58|1@1+ (1,0) [0|1] "" Vector__XXX
 SG_ DIF_a126_limpMode : 61|1@1+ (1,0) [0|1] "" Vector__XXX
 SG_ DIF_a127_gracefulPowerOff : 62|1@1+ (1,0) [0|1] "" Vector__XXX
 SG_ DIF_a128_fpgaVersionMismatch : 63|1@1+ (1,0) [0|1] "" Vector__XXX

BO_ 858 DIF_alertMatrix3: 8 DIF
 SG_ DIF_a133_capacitorOT : 4|1@1+ (1,0) [0|1] "" Vector__XXX
 SG_ DIF_a134_wheelSpeedIrrational : 5|1@1+ (1,0) [0|1] "" Vector__XXX
 SG_ DIF_a136_spiError : 7|1@1+ (1,0) [0|1] "" Vector__XXX
 SG_ DIF_a142_highLashAngle : 13|1@1+ (1,0) [0|1] "" Vector__XXX
 SG_ DIF_a144_configMismatch : 15|1@1+ (1,0) [0|1] "" Vector__XXX
 SG_ DIF_a147_highTorqueWearLimit : 18|1@1+ (1,0) [0|1] "" Vector__XXX
 SG_ DIF_a148_burnInCycleEnded : 19|1@1+ (1,0) [0|1] "" Vector__XXX
 SG_ DIF_a149_oilPumpFailure : 20|1@1+ (1,0) [0|1] "" Vector__XXX
 SG_ DIF_a150_busVD : 21|1@1+ (1,0) [0|1] "" Vector__XXX
 SG_ DIF_a151_shockTorqueLimiter : 22|1@1+ (1,0) [0|1] "" Vector__XXX
 SG_ DIF_a152_linError : 23|1@1+ (1,0) [0|1] "" Vector__XXX
 SG_ DIF_a153_oilPumpDiagnostics : 24|1@1+ (1,0) [0|1] "" Vector__XXX
 SG_ DIF_a154_resolver : 25|1@1+ (1,0) [0|1] "" Vector__XXX
 SG_ DIF_a155_vcfrontMIA : 26|1@1+ (1,0) [0|1] "" Vector__XXX
 SG_ DIF_a156_currentObserver : 27|1@1+ (1,0) [0|1] "" Vector__XXX
 SG_ DIF_a157_rcmMIA : 28|1@1+ (1,0) [0|1] "" Vector__XXX
 SG_ DIF_a158_ibstMIA : 29|1@1+ (1,0) [0|1] "" Vector__XXX
 SG_ DIF_a160_busVoltageAnomaly : 31|1@1+ (1,0) [0|1] "" Vector__XXX
 SG_ DIF_a161_epas3pMIA : 32|1@1+ (1,0) [0|1] "" Vector__XXX
 SG_ DIF_a162_endOfLifetimeBurnIn : 33|1@1+ (1,0) [0|1] "" Vector__XXX
 SG_ DIF_a174_unitMayNotRestart : 45|1@1+ (1,0) [0|1] "" Vector__XXX
 SG_ DIF_a176_safetyICFault : 47|1@1+ (1,0) [0|1] "" Vector__XXX
 SG_ DIF_a177_fluxReferenceCorrected : 48|1@1+ (1,0) [0|1] "" Vector__XXX

BO_ 859 DIF_alertMatrix4: 8 DIF
 SG_ DIF_a202_excessHeatUnavailable : 9|1@1+ (1,0) [0|1] "" Vector__XXX
 SG_ DIF_a225_tmpEstPlausibility : 32|1@1+ (1,0) [0|1] "" Vector__XXX
 SG_ DIF_a231_unintendedReset2 : 38|1@1+ (1,0) [0|1] "" Vector__XXX
 SG_ DIF_a233_diMsgMissed : 40|1@1+ (1,0) [0|1] "" Vector__XXX
 SG_ DIF_a234_pcsMIA : 41|1@1+ (1,0) [0|1] "" Vector__XXX
 SG_ DIF_a236_tasMIA : 43|1@1+ (1,0) [0|1] "" Vector__XXX
 SG_ DIF_a241_systemThermallyLimited : 48|1@1+ (1,0) [0|1] "" Vector__XXX
 SG_ DIF_a242_spinDownLearning : 49|1@1+ (1,0) [0|1] "" Vector__XXX
 SG_ DIF_a243_ecuLogAvailable : 50|1@1+ (1,0) [0|1] "" Vector__XXX
 SG_ DIF_a244_mechSafeStateApplied : 51|1@1+ (1,0) [0|1] "" Vector__XXX
 SG_ DIF_a245_mechSafeStatePreWarn : 52|1@1+ (1,0) [0|1] "" Vector__XXX
 SG_ DIF_a246_recoveryAtSpeedError : 53|1@1+ (1,0) [0|1] "" Vector__XXX
 SG_ DIF_a247_rotorOffsetError : 54|1@1+ (1,0) [0|1] "" Vector__XXX
 SG_ DIF_a249_highStatorTempFromResis : 56|1@1+ (1,0) [0|1] "" Vector__XXX
 SG_ DIF_a250_preregulatorRail : 57|1@1+ (1,0) [0|1] "" Vector__XXX
 SG_ DIF_a251_oilPumpService : 58|1@1+ (1,0) [0|1] "" Vector__XXX
 SG_ DIF_a252_currentCoreFallback : 59|1@1+ (1,0) [0|1] "" Vector__XXX
 SG_ DIF_a253_lvBoostedRail : 60|1@1+ (1,0) [0|1] "" Vector__XXX
 SG_ DIF_a254_activeDischargeRail : 61|1@1+ (1,0) [0|1] "" Vector__XXX
 SG_ DIF_a255_currentGainFallback : 62|1@1+ (1,0) [0|1] "" Vector__XXX

BO_ 1879 DIF_debug: 8 DIF
 SG_ DIF_debugSelector M : 0|8@1+ (1,0) [0|255] "" Vector__XXX
 SG_ DIF_phaseOutBusbarTemp m70 : 8|8@1+ (1,-40) [-40|215] "DegC" Vector__XXX
 SG_ DIF_phaseOutBusbarWeldTemp m70 : 16|8@1+ (1,-40) [-40|215] "DegC" Vector__XXX
 SG_ DIF_phaseOutLugTemp m70 : 24|8@1+ (1,-40) [-40|215] "DegC" Vector__XXX
 SG_ DIF_dcLinkCapTemp m70 : 32|8@1+ (1,-40) [-40|215] "DegC" Vector__XXX
 SG_ DIF_hvDcCableTemp m70 : 40|8@1+ (1,-40) [-40|215] "DegC" Vector__XXX
 SG_ DIF_negDcBusbarTemp m70 : 48|8@1+ (1,-40) [-40|215] "DegC" Vector__XXX
 SG_ DIF_posDcBusbarTemp m70 : 56|8@1+ (1,-40) [-40|215] "DegC" Vector__XXX
 SG_ DIF_statorEndWindingTemp m72 : 8|8@1+ (1,-40) [-40|215] "DegC" Vector__XXX
 SG_ DIF_rotorMaxMagnetTemp m72 : 16|8@1+ (1,-40) [-40|215] "DegC" Vector__XXX
 SG_ DIF_lightSenseV m72 : 24|6@1+ (0.1,0) [0|3.3] "V" Vector__XXX
 SG_ DIF_pyroSenseV m72 : 30|8@1+ (0.02,0) [0|3.3] "V" Vector__XXX
 SG_ DIF_statorSlotWindingTemp m72 : 46|8@1+ (1,-40) [-40|215] "DegC" Vector__XXX
 SG_ DIF_intervalMaxHvBusV m72 : 54|10@1+ (1,0) [0|1023] "V" Vector__XXX

BO_ 634 DIF_hvStatus: 8 DIF
 SG_ DIF_hvStatusChecksum : 0|8@1+ (1,0) [0|255] "" Vector__XXX
 SG_ DIF_hvStatusCounter : 8|4@1+ (1,0) [0|15] "" Vector__XXX
 SG_ DIF_hvilCurrent : 12|8@1+ (0.1,0) [0|25.5] "mA" Vector__XXX
 SG_ DIF_hvilCmVoltage : 20|8@1+ (0.08,0) [0|20.4] "V" Vector__XXX
 SG_ DIF_hvilStatus : 28|2@1+ (1,0) [0|3] "" Vector__XXX
 SG_ DIF_hvilSupplyState : 30|2@1+ (1,0) [0|3] "" Vector__XXX
 SG_ DIF_activeDischargeCtrl : 32|1@1+ (1,0) [0|1] "" Vector__XXX
 SG_ DIF_activeDischargeStatus : 33|1@1+ (1,0) [0|1] "" Vector__XXX
 SG_ DIF_vBat : 34|10@1+ (1,0) [0|1023] "V" Vector__XXX
 SG_ DIF_vBatQF : 44|1@1+ (1,0) [0|1] "" Vector__XXX
 SG_ DIF_powerStageSafeState : 45|2@1+ (1,0) [0|3] "" Vector__XXX
 SG_ DIF_fluxState : 48|4@1+ (1,0) [0|15] "" Vector__XXX
 SG_ DIF_vBusDiag : 52|1@1+ (1,0) [0|1] "" Vector__XXX
 SG_ DIF_gateDriveState : 53|3@1+ (1,0) [0|7] "" Vector__XXX

BO_ 1622 DIF_info: 8 DIF
 SG_ DIF_infoIndex M : 0|8@1+ (1,0) [0|255] "" Vector__XXX
 SG_ DIF_buildType m10 : 8|3@1+ (1,0) [0|7] "" Vector__XXX
 SG_ DIF_buildConfigurationId m10 : 16|16@1+ (1,0) [0|65535] "" Vector__XXX
 SG_ DIF_hardwareId m10 : 32|8@1+ (1,0) [0|252] "" Vector__XXX
 SG_ DIF_componentId m10 : 48|16@1+ (1,0) [0|65535] "" Vector__XXX
 SG_ DIF_pcbaId m11 : 16|8@1+ (1,0) [0|255] "" Vector__XXX
 SG_ DIF_assemblyId m11 : 24|8@1+ (1,0) [0|255] "" Vector__XXX
 SG_ DIF_usageId m11 : 32|16@1+ (1,0) [0|65535] "" Vector__XXX
 SG_ DIF_subUsageId m11 : 48|16@1+ (1,0) [0|65535] "" Vector__XXX
 SG_ DIF_motorType m12 : 8|5@1+ (1,0) [0|31] "" Vector__XXX
 SG_ DIF_siliconType m12 : 16|1@1+ (1,0) [0|1] "" Vector__XXX
 SG_ DIF_mechSafeStateType m12 : 24|2@1+ (1,0) [0|3] "" Vector__XXX
 SG_ DIF_applicationCrc m13 : 32|32@1+ (1,0) [0|4294967295] "" Vector__XXX
 SG_ DIF_oilPumpBuildType m16 : 8|3@1+ (1,0) [0|7] "" Vector__XXX
 SG_ DIF_oilPumpAppCrc m16 : 16|32@1+ (1,0) [0|4294967295] "" Vector__XXX
 SG_ DIF_FPGA_version m16 : 48|8@1+ (1,0) [0|255] "" Vector__XXX
 SG_ DIF_appGitHash m17 : 8|56@1+ (1,0) [0|7.20575940379e+16] "" Vector__XXX
 SG_ DIF_bootGitHash m18 : 8|56@1+ (1,0) [0|7.20575940379e+16] "" Vector__XXX
 SG_ DIF_platformTyp m19 : 8|8@1+ (1,0) [0|255] "" Vector__XXX
 SG_ DIF_infoBootLdUdsProtocolVersion m20 : 8|8@1+ (1,0) [0|255] "" Vector__XXX
 SG_ DIF_bootloaderCrc m20 : 32|32@1+ (1,0) [0|4294967295] "" Vector__XXX
 SG_ DIF_oilPumpPcbaId m33 : 8|8@1+ (1,0) [0|255] "" Vector__XXX
 SG_ DIF_oilPumpAssemblyId m33 : 16|8@1+ (1,0) [0|255] "" Vector__XXX
 SG_ DIF_oilPumpUsageId m33 : 24|16@1+ (1,0) [0|65535] "" Vector__XXX
 SG_ DIF_refRotorFlux m35 : 8|16@1+ (0.0001,0) [0|6.5535] "Wb" Vector__XXX
 SG_ DIF_refRotorOffset m35 : 24|12@1- (0.1,0) [-180|180] "deg" Vector__XXX
 SG_ DIF_speedWearTotal m36 : 8|8@1+ (0.4,0) [0|100] "%" Vector__XXX
 SG_ DIF_torqueWearTotal m36 : 24|8@1+ (0.02,0) [0|5.08] "1" Vector__XXX

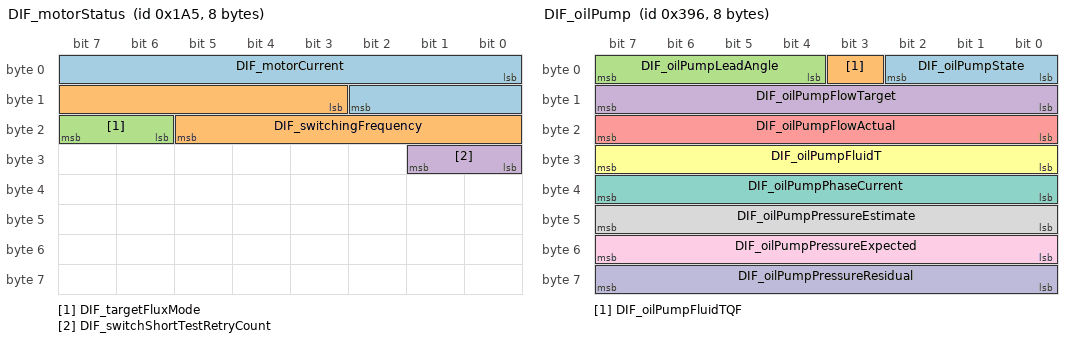
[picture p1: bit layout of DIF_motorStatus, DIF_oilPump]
BO_ 421 DIF_motorStatus: 8 DIF
 SG_ DIF_motorCurrent : 0|11@1+ (1,0) [0|2047] "A" Vector__XXX
 SG_ DIF_switchingFrequency : 11|11@1+ (0.01,0) [0|20] "kHz" Vector__XXX
 SG_ DIF_targetFluxMode : 22|2@1+ (1,0) [0|3] "" Vector__XXX
 SG_ DIF_switchShortTestRetryCount : 24|2@1+ (1,0) [0|3] "" Vector__XXX

BO_ 918 DIF_oilPump: 8 DIF
 SG_ DIF_oilPumpState : 0|3@1+ (1,0) [0|7] "" Vector__XXX
 SG_ DIF_oilPumpFluidTQF : 3|1@1+ (1,0) [0|1] "" Vector__XXX
 SG_ DIF_oilPumpLeadAngle : 4|4@1+ (1.875,0) [0|28.125] "degrees" Vector__XXX
 SG_ DIF_oilPumpFlowTarget : 8|8@1+ (0.1,0) [0|25.4] "LPM" Vector__XXX
 SG_ DIF_oilPumpFlowActual : 16|8@1+ (0.1,0) [0|25.4] "LPM" Vector__XXX
 SG_ DIF_oilPumpFluidT : 24|8@1+ (1,-40) [-40|214] "DegC" Vector__XXX
 SG_ DIF_oilPumpPhaseCurrent : 32|8@1+ (0.1,0) [0|25.4] "A" Vector__XXX
 SG_ DIF_oilPumpPressureEstimate : 40|8@1+ (2,0) [0|500] "kPa" Vector__XXX
 SG_ DIF_oilPumpPressureExpected : 48|8@1+ (2,0) [0|500] "kPa" Vector__XXX
 SG_ DIF_oilPumpPressureResidual : 56|8@1+ (4,-500) [-500|500] "kPa" Vector__XXX

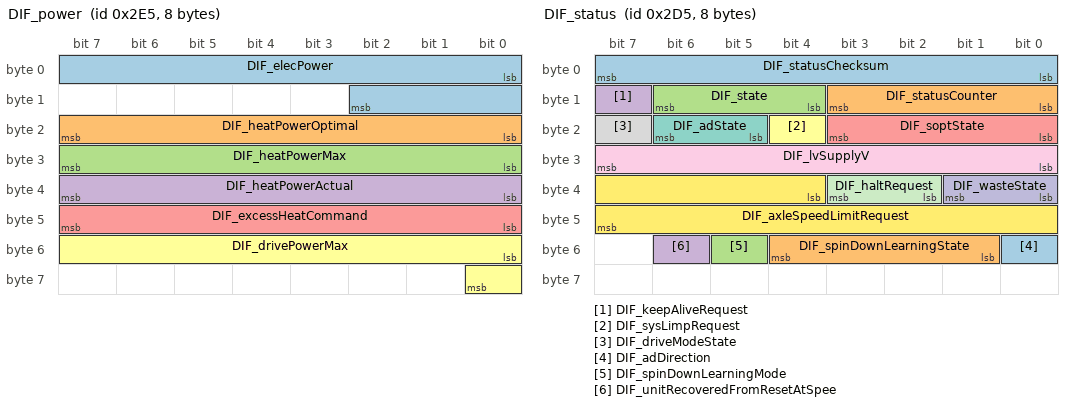
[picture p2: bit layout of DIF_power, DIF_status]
BO_ 741 DIF_power: 8 DIF
 SG_ DIF_elecPower : 0|11@1- (0.5,0) [-500|500] "kW" Vector__XXX
 SG_ DIF_heatPowerOptimal : 16|8@1+ (0.08,0) [0|20] "kW" Vector__XXX
 SG_ DIF_heatPowerMax : 24|8@1+ (0.08,0) [0|20] "kW" Vector__XXX
 SG_ DIF_heatPowerActual : 32|8@1+ (0.08,0) [0|20] "kW" Vector__XXX
 SG_ DIF_excessHeatCommand : 40|8@1+ (0.08,0) [0|20] "kW" Vector__XXX
 SG_ DIF_drivePowerMax : 48|9@1+ (1,0) [0|400] "kW" Vector__XXX

BO_ 725 DIF_status: 8 DIF
 SG_ DIF_statusChecksum : 0|8@1+ (1,0) [0|255] "" Vector__XXX
 SG_ DIF_statusCounter : 8|4@1+ (1,0) [0|15] "" Vector__XXX
 SG_ DIF_state : 12|3@1+ (1,0) [0|7] "" Vector__XXX
 SG_ DIF_keepAliveRequest : 15|1@1+ (1,0) [0|1] "" Vector__XXX
 SG_ DIF_soptState : 16|4@1+ (1,0) [0|15] "" Vector__XXX
 SG_ DIF_sysLimpRequest : 20|1@1+ (1,0) [0|1] "" Vector__XXX
 SG_ DIF_adState : 21|2@1+ (1,0) [0|3] "" Vector__XXX
 SG_ DIF_driveModeState : 23|1@1+ (1,0) [0|1] "" Vector__XXX
 SG_ DIF_lvSupplyV : 24|8@1+ (0.1,0) [0|25.5] "V" Vector__XXX
 SG_ DIF_wasteState : 32|2@1+ (1,0) [0|3] "" Vector__XXX
 SG_ DIF_haltRequest : 34|2@1+ (1,0) [0|3] "" Vector__XXX
 SG_ DIF_axleSpeedLimitRequest : 36|12@1+ (1,40) [40|2750] "RPM" Vector__XXX
 SG_ DIF_adDirection : 48|1@1+ (1,0) [0|1] "" Vector__XXX
 SG_ DIF_spinDownLearningState : 49|4@1+ (1,0) [0|15] "" Vector__XXX
 SG_ DIF_spinDownLearningMode : 53|1@1+ (1,0) [0|1] "" Vector__XXX
 SG_ DIF_unitRecoveredFromResetAtSpee : 54|1@1+ (1,0) [0|1] "" Vector__XXX

CM_ BO_ 299 "Driver assistance computer message: smart shift";
CM_ SG_ 299 DAS_smartShiftChecksum "Driver assistance computer: smart shift checksum";
CM_ SG_ 299 DAS_smartShiftCounter "Driver assistance computer: smart shift counter";
CM_ SG_ 299 DAS_smartShiftTorqueDirection "Reports Driver Assistance System (DAS) Smart Shift torque direction.";
CM_ SG_ 299 DAS_smartShiftTorqueReason "Reports Driver Assistance System (DAS) Smart Shift torque direction reason.";
CM_ SG_ 299 DAS_autoshiftTorqueDirectionDbg "Driver assistance computer: autoshift torque direction dbg";
CM_ SG_ 299 DAS_autoshiftUpcomingDirection "Reports the Driver Assistance System (DAS) upcoming torque direction.";
CM_ SG_ 299 DAS_autoshiftBrakeRequired "Reports whether brake press is required for Autoshift Drive/Reverse (D/R).";
CM_ SG_ 299 DAS_autoshiftSteerRequest "Reports the Driver Assistance System (DAS) steering angle direction requested for Autoshift Drive/Reverse (D/R).";
CM_ BO_ 921 "Driver assistance computer message: status";
CM_ SG_ 921 DAS_autopilotState "Reports the high level autopilot state.";
CM_ SG_ 921 DAS_blindSpotRearLeft "Reports rear left blind spot warning level.";
CM_ SG_ 921 DAS_blindSpotRearRight "Reports rear right blind spot warning level.";
CM_ SG_ 921 DAS_fusedSpeedLimit "Driver assistance computer: fused speed limit";
CM_ SG_ 921 DAS_suppressSpeedWarning "Driver assistance computer: suppress speed warning";
CM_ SG_ 921 DAS_summonObstacle "Driver assistance computer: summon obstacle";
CM_ SG_ 921 DAS_summonClearedGate "Driver assistance computer: summon cleared gate";
CM_ SG_ 921 DAS_visionOnlySpeedLimit "Driver assistance computer: vision only speed limit";
CM_ SG_ 921 DAS_heaterState "The state of the app which runs the front glass heater.";
CM_ SG_ 921 DAS_forwardCollisionWarning "Driver assistance computer: forward collision warning";
CM_ SG_ 921 DAS_autoparkReady "Indicates if all the conditions for Autopark are met.";
CM_ SG_ 921 DAS_autoParked "Driver assistance computer: auto parked";
CM_ SG_ 921 DAS_autoparkActive "Reports whether Autopark is currently active.";
CM_ SG_ 921 DAS_summonFwdLeashReached "Driver assistance computer: summon fwd leash reached";
CM_ SG_ 921 DAS_summonRvsLeashReached "Driver assistance computer: summon rvs leash reached";
CM_ SG_ 921 DAS_lssState "Tracks lane support system state and whether it is controlling steering angle requests for LKA / ELKA.";
CM_ SG_ 921 DAS_sideCollisionAvoid "Reports if the side collision avoidance function is active on the left or right.";
CM_ SG_ 921 DAS_sideCollisionWarning "Reports if the side collision warning function is active in the left or right.";
CM_ SG_ 921 DAS_sideCollisionInhibit "Driver assistance computer: side collision inhibit";
CM_ SG_ 921 DAS_laneDepartureWarning "Driver assistance computer: lane departure warning";
CM_ SG_ 921 DAS_fleetSpeedState "The state of the fleet speed algorithm.";
CM_ SG_ 921 DAS_autopilotHandsOnState "Reports the state of the hands on state machine.";
CM_ SG_ 921 DAS_autoLaneChangeState "Reports the legacy Automatic Lane Change (ALC) state used to drive the instrument cluster User Interface (UI).";
CM_ SG_ 921 DAS_summonAvailable "Driver assistance computer: summon available";
CM_ SG_ 921 DAS_statusCounter "Driver assistance computer: status counter";
CM_ SG_ 921 DAS_statusChecksum "Driver assistance computer: status checksum";
CM_ BO_ 905 "Driver assistance computer message: status2";
CM_ SG_ 905 DAS_accSpeedLimit "Reports the Adaptive Cruise Control (ACC) speed limit, which is derived from speed limits embedded in maps.";
CM_ SG_ 905 DAS_versionIdentifier "Driver assistance computer: version identifier";
CM_ SG_ 905 DAS_pmmObstacleSeverity "Detects the output of the Pedal Misapplication Mitigation (PMM) function, which limits torque or applies the brake.";
CM_ SG_ 905 DAS_pmmLoggingRequest "Driver assistance computer: pmm logging request";
CM_ SG_ 905 DAS_activationFailureStatus "Driver assistance computer: activation failure status";
CM_ SG_ 905 DAS_pmmUltrasonicsFaultReason "Reports if there is a reason Pedal Misapplication Mitigation (PMM) is disabled due to a condition with the ultrasonics.";
CM_ SG_ 905 DAS_pmmRadarFaultReason "Reports if there is a reason Pedal Misapplication Mitigation (PMM) is disabled due to a radar issue.";
CM_ SG_ 905 DAS_pmmSysFaultReason "Reports if there is a reason Pedal Misapplication Mitigation (PMM) is disabled due to a system malfunction.";
CM_ SG_ 905 DAS_pmmCameraFaultReason "Reports if there is a reason Pedal Misapplication Mitigation (PMM) is disabled due to camera issues.";
CM_ SG_ 905 DAS_ACC_report "Indicates what control target Traffic-Aware Cruise Control (TACC) is controlling for. Only relevant during TACC (not Autosteer).";
CM_ SG_ 905 DAS_relaxCruiseLimits "Indicates whether DI should relax accel limits";
CM_ SG_ 905 DAS_csaState "Reports the state of the curve speed adaption algorithm.";
CM_ SG_ 905 DAS_radarTelemetry "Driver assistance computer: radar telemetry";
CM_ SG_ 905 DAS_robState "Driver assistance computer: rob state";
CM_ SG_ 905 DAS_driverInteractionLevel "Driver assistance computer: driver interaction level";
CM_ SG_ 905 DAS_ppOffsetDesiredRamp "Driver assistance computer: pp offset desired ramp";
CM_ SG_ 905 DAS_longCollisionWarning "Driver assistance computer: long collision warning";
CM_ SG_ 905 DAS_status2Counter "Driver assistance computer: status2 counter";
CM_ SG_ 905 DAS_status2Checksum "Driver assistance computer: status2 checksum";
CM_ BO_ 1548 "Driver assistance computer message: telemetry radar";
CM_ SG_ 1548 DAS_TR_ObjIndex "Driver assistance computer: TR obj index";
CM_ SG_ 1548 DAS_TR_Counter "Driver assistance computer: TR counter";
CM_ SG_ 1548 DAS_TR_Obj00_Class "Driver assistance computer: TR obj00 class";
CM_ SG_ 1548 DAS_TR_Obj00_Dx "Driver assistance computer: TR obj00 dx";
CM_ SG_ 1548 DAS_TR_Obj00_Dy "Driver assistance computer: TR obj00 dy";
CM_ SG_ 1548 DAS_TR_Obj00_Vx "Driver assistance computer: TR obj00 vx";
CM_ SG_ 1548 DAS_TR_Obj00_RCS "Driver assistance computer: TR obj00 RCS";
CM_ SG_ 1548 DAS_TR_Obj00_Length "Driver assistance computer: TR obj00 length";
CM_ SG_ 1548 DAS_TR_Obj00_MovingState "Driver assistance computer: TR obj00 moving state";
CM_ SG_ 1548 DAS_TR_Obj00_Dz "Driver assistance computer: TR obj00 dz";
CM_ SG_ 1548 DAS_TR_Obj00_Exist "Driver assistance computer: TR obj00 exist";
CM_ BO_ 586 "Driver assistance computer message: visual debug";
CM_ SG_ 586 DAS_autosteerVehiclesUsage "Driver assistance computer: autosteer vehicles usage";
CM_ SG_ 586 DAS_autosteerHPPUsage "Driver assistance computer: autosteer HPP usage";
CM_ SG_ 586 DAS_autosteerNavigationUsage "Driver assistance computer: autosteer navigation usage";
CM_ SG_ 586 DAS_autosteerModelUsage "Driver assistance computer: autosteer model usage";
CM_ SG_ 586 DAS_autosteerBottsDotsUsage "Driver assistance computer: autosteer botts dots usage";
CM_ SG_ 586 DAS_offsetSide "Driver assistance computer: offset side";
CM_ SG_ 586 DAS_roadSurfaceType "Driver assistance computer: road surface type";
CM_ SG_ 586 DAS_autosteerHealthAnomalyLevel "Driver assistance computer: autosteer health anomaly level";
CM_ SG_ 586 DAS_autosteerHealthState "Driver assistance computer: autosteer health state";
CM_ SG_ 586 DAS_lastLinePreferenceReason "Driver assistance computer: last line preference reason";
CM_ SG_ 586 DAS_plannerState "Driver assistance computer: planner state";
CM_ SG_ 586 DAS_lastAutosteerAbortReason "Driver assistance computer: last autosteer abort reason";
CM_ SG_ 586 DAS_devAppInterfaceEnabled "Driver assistance computer: dev app interface enabled";
CM_ SG_ 586 DAS_navAvailable "Driver assistance computer: nav available";
CM_ SG_ 586 DAS_navDistance "Driver assistance computer: nav distance";
CM_ SG_ 586 DAS_accSmartSpeedActive "Driver assistance computer: acc smart speed active";
CM_ SG_ 586 DAS_accSmartSpeedState "Driver assistance computer: acc smart speed state";
CM_ SG_ 586 DAS_ulcInProgress "Reports active lane changes that were not commanded.";
CM_ SG_ 586 DAS_trafficAwareSetSpeedInUse "Indicates that autopilot is using cruise set speed based on flow of traffic";
CM_ SG_ 586 DAS_isaSystemState "ISA system state";
CM_ SG_ 586 DAS_behaviorType "Driver assistance computer: behavior type";
CM_ SG_ 586 DAS_ulcType "Reports the underlying reason for the uncommanded lane change, whether for speed or route.";
CM_ SG_ 586 DAS_rearVehDetectedThisCycle "Driver assistance computer: rear veh detected this cycle";
CM_ SG_ 586 DAS_rearLeftVehDetectedCurrent "Driver assistance computer: rear left veh detected current";
CM_ SG_ 586 DAS_rearRightVehDetectedTrip "Driver assistance computer: rear right veh detected trip";
CM_ SG_ 586 DAS_rearLeftVehDetectedTrip "Driver assistance computer: rear left veh detected trip";
CM_ BO_ 2040 "Driver assistance computer message: warning matrix0";
CM_ SG_ 2040 DAS_w002_ldwDisabled "Driver assistance computer: w002 ldw disabled";
CM_ SG_ 2040 DAS_w003_isaDisabled "Driver assistance computer: w003 isa disabled";
CM_ SG_ 2040 DAS_w004_accDisabled "Driver assistance computer: w004 acc disabled";
CM_ SG_ 2040 DAS_w005_fcwCancelled "Driver assistance computer: w005 fcw cancelled";
CM_ SG_ 2040 DAS_w006_aebCancelled "Driver assistance computer: w006 aeb cancelled";
CM_ SG_ 2040 DAS_w007_ahlbDisabled "Driver assistance computer: w007 ahlb disabled";
CM_ SG_ 2040 DAS_w008_parkDisabled "Driver assistance computer: w008 park disabled";
CM_ SG_ 2040 DAS_w009_aebFault "Driver assistance computer: w009 aeb fault";
CM_ SG_ 2040 DAS_w010_radcCalibIssue "Driver assistance computer: w010 radc calib issue";
CM_ SG_ 2040 DAS_w011_scaEvent "Driver assistance computer: w011 sca event";
CM_ SG_ 2040 DAS_w012_Cam_BootFailure "Driver assistance computer: w012 cam boot failure";
CM_ SG_ 2040 DAS_w013_Cam_Watchdog "Driver assistance computer: w013 cam watchdog";
CM_ SG_ 2040 DAS_w014_swAssert "Driver assistance computer: w014 sw assert";
CM_ SG_ 2040 DAS_w015_Camera_Failsafes "Driver assistance computer: w015 camera failsafes";
CM_ SG_ 2040 DAS_w016_aeb_e_event "Driver assistance computer: w016 aeb e event";
CM_ SG_ 2040 DAS_w017_Cam_Msg_MIA "Driver assistance computer: w017 cam msg MIA";
CM_ SG_ 2040 DAS_w018_ECU_Power_Issue "Driver assistance computer: w018 ECU power issue";
CM_ SG_ 2040 DAS_w019_ECU_Stack_Overflow "Driver assistance computer: w019 ECU stack overflow";
CM_ SG_ 2040 DAS_w020_ECU_checkstopError "Driver assistance computer: w020 ECU checkstop error";
CM_ SG_ 2040 DAS_w021_ECU_Temperature_Issue "Driver assistance computer: w021 ECU temperature issue";
CM_ SG_ 2040 DAS_w022_ECU_EEPROM_Failure "Driver assistance computer: w022 ECU EEPROM failure";
CM_ SG_ 2040 DAS_w023_ECU_Cam_Statemismatc "Driver assistance computer: w023 ECU cam statemismatc";
CM_ SG_ 2040 DAS_w024_ECU_Watchdog_Reset "Driver assistance computer: w024 ECU watchdog reset";
CM_ SG_ 2040 DAS_w025_LC_Steering_Override "Driver assistance computer: w025 LC steering override";
CM_ SG_ 2040 DAS_w026_ECU_timingIssue "Driver assistance computer: w026 ECU timing issue";
CM_ SG_ 2040 DAS_w027_ECU_Reset_Fault "Driver assistance computer: w027 ECU reset fault";
CM_ SG_ 2040 DAS_w028_spi_rx_error "Driver assistance computer: w028 spi rx error";
CM_ SG_ 2040 DAS_w029_spi_tx_error "Driver assistance computer: w029 spi tx error";
CM_ SG_ 2040 DAS_w030_Heater_Issue "Driver assistance computer: w030 heater issue";
CM_ SG_ 2040 DAS_w031_canRxError "Driver assistance computer: w031 can rx error";
CM_ SG_ 2040 DAS_w032_canTxError "Driver assistance computer: w032 can tx error";
CM_ SG_ 2040 DAS_w033_gtwMia "Driver assistance computer: w033 gtw mia";
CM_ SG_ 2040 DAS_w034_sccmMia "Driver assistance computer: w034 sccm mia";
CM_ SG_ 2040 DAS_w035_espMia "Driver assistance computer: w035 esp mia";
CM_ SG_ 2040 DAS_w036_bdyMia "Driver assistance computer: w036 bdy mia";
CM_ SG_ 2040 DAS_w037_camTacIssue "Driver assistance computer: w037 cam tac issue";
CM_ SG_ 2040 DAS_w038_camFailure "Driver assistance computer: w038 cam failure";
CM_ SG_ 2040 DAS_w039_sdm_rcm_Mia "Driver assistance computer: w039 sdm rcm mia";
CM_ SG_ 2040 DAS_w040_autopilotAngleSaturated "Driver assistance computer: w040 autopilot angle saturated";
CM_ SG_ 2040 DAS_w041_autopilotRateSaturated "Driver assistance computer: w041 autopilot rate saturated";
CM_ SG_ 2040 DAS_w042_autopilotAborting "Driver assistance computer: w042 autopilot aborting";
CM_ SG_ 2040 DAS_w043_camLongRunTime "Driver assistance computer: w043 cam long run time";
CM_ SG_ 2040 DAS_w044_appMobileyeFailure "Driver assistance computer: w044 app mobileye failure";
CM_ SG_ 2040 DAS_w045_radMia "Driver assistance computer: w045 rad mia";
CM_ SG_ 2040 DAS_w046_eepromRecordAbsent "Driver assistance computer: w046 eeprom record absent";
CM_ SG_ 2040 DAS_w047_edrEvent "Driver assistance computer: w047 edr event";
CM_ SG_ 2040 DAS_w048_DAS_Features_Disabled "Driver assistance computer: w048 DAS features disabled";
CM_ SG_ 2040 DAS_w049_eyeqVersionMismatch "Driver assistance computer: w049 eyeq version mismatch";
CM_ SG_ 2040 DAS_w050_aeb_event "Driver assistance computer: w050 aeb event";
CM_ SG_ 2040 DAS_w051_radcEcuIssue "Driver assistance computer: w051 radc ecu issue";
CM_ SG_ 2040 DAS_w052_radcSensorIssue "Driver assistance computer: w052 radc sensor issue";
CM_ SG_ 2040 DAS_w053_radcCommIssue "Driver assistance computer: w053 radc comm issue";
CM_ SG_ 2040 DAS_w054_camAutofix "Driver assistance computer: w054 cam autofix";
CM_ SG_ 2040 DAS_w055_radcVersionMismatch "Driver assistance computer: w055 radc version mismatch";
CM_ SG_ 2040 DAS_w056_diMia "Driver assistance computer: w056 di mia";
CM_ SG_ 2040 DAS_w057_mcuMia "Driver assistance computer: w057 mcu mia";
CM_ SG_ 2040 DAS_w058_epbMia "Driver assistance computer: w058 epb mia";
CM_ SG_ 2040 DAS_w059_parkMia "Driver assistance computer: w059 park mia";
CM_ SG_ 2040 DAS_w060_fcw_event "Driver assistance computer: w060 fcw event";
CM_ SG_ 2040 DAS_w061_airSuspensionMia "Driver assistance computer: w061 air suspension mia";
CM_ SG_ 2040 DAS_w062_radcAlignment "Driver assistance computer: w062 radc alignment";
CM_ SG_ 2040 DAS_w063_parkVersionMismatch "Driver assistance computer: w063 park version mismatch";
CM_ SG_ 2040 DAS_w064_epasMia "Driver assistance computer: w064 epas mia";
CM_ BO_ 874 "Driver assistance computer message: warning matrix1";
CM_ SG_ 874 DAS_w065_deserializerOvercurrent "Driver assistance computer: w065 deserializer overcurrent";
CM_ SG_ 874 DAS_w066_deserializerLockLost "Driver assistance computer: w066 deserializer lock lost";
CM_ SG_ 874 DAS_w067_steeringAlignment "Driver assistance computer: w067 steering alignment";
CM_ SG_ 874 DAS_w068_vlInconsistency "Driver assistance computer: w068 vl inconsistency";
CM_ SG_ 874 DAS_w069_apcSpaceMasked "Driver assistance computer: w069 apc space masked";
CM_ SG_ 874 DAS_w070_apcIncompleteCal "Driver assistance computer: w070 apc incomplete cal";
CM_ SG_ 874 DAS_w071_selfparkStarted "Driver assistance computer: w071 selfpark started";
CM_ SG_ 874 DAS_w072_selfparkComplete "Driver assistance computer: w072 selfpark complete";
CM_ SG_ 874 DAS_w073_issueEscalatedLDW "Driver assistance computer: w073 issue escalated LDW";
CM_ SG_ 874 DAS_w074_inPathStationaryObst "Driver assistance computer: w074 in path stationary obst";
CM_ SG_ 874 DAS_w075_scMia "Driver assistance computer: w075 sc mia";
CM_ SG_ 874 DAS_w076_mobilEyeSetC "Driver assistance computer: w076 mobil eye set c";
CM_ SG_ 874 DAS_w077_pmmActive "Driver assistance computer: w077 pmm active";
CM_ SG_ 874 DAS_w078_pmmActive2 "Driver assistance computer: w078 pmm active2";
CM_ SG_ 874 DAS_w079_edrAvailable "Driver assistance computer: w079 edr available";
CM_ SG_ 874 DAS_w080_accFailedActivation "Driver assistance computer: w080 acc failed activation";
CM_ SG_ 874 DAS_w081_pmmActiveBraking "Driver assistance computer: w081 pmm active braking";
CM_ SG_ 874 DAS_w082_inPathFSviolation "Driver assistance computer: w082 in path f sviolation";
CM_ SG_ 874 DAS_w083_inPathRADObject "Driver assistance computer: w083 in path RAD object";
CM_ SG_ 874 DAS_w084_pmmIPSO "Driver assistance computer: w084 pmm IPSO";
CM_ SG_ 874 DAS_w085_pmmSteering "Driver assistance computer: w085 pmm steering";
CM_ SG_ 874 DAS_w086_robCollision "Driver assistance computer: w086 rob collision";
CM_ SG_ 874 DAS_w087_DEPRECATED "Driver assistance computer: w087 DEPRECATED";
CM_ SG_ 874 DAS_w088_DEPRECATED "Driver assistance computer: w088 DEPRECATED";
CM_ SG_ 874 DAS_w089_DEPRECATED "Driver assistance computer: w089 DEPRECATED";
CM_ SG_ 874 DAS_w090_DEPRECATED "Driver assistance computer: w090 DEPRECATED";
CM_ SG_ 874 DAS_w091_DEPRECATED "Driver assistance computer: w091 DEPRECATED";
CM_ SG_ 874 DAS_w092_DEPRECATED "Driver assistance computer: w092 DEPRECATED";
CM_ SG_ 874 DAS_w093_DEPRECATED "Driver assistance computer: w093 DEPRECATED";
CM_ SG_ 874 DAS_w094_DEPRECATED "Driver assistance computer: w094 DEPRECATED";
CM_ SG_ 874 DAS_w095_DEPRECATED "Driver assistance computer: w095 DEPRECATED";
CM_ SG_ 874 DAS_w096_DEPRECATED "Driver assistance computer: w096 DEPRECATED";
CM_ SG_ 874 DAS_w097_DEPRECATED "Driver assistance computer: w097 DEPRECATED";
CM_ SG_ 874 DAS_w098_DEPRECATED "Driver assistance computer: w098 DEPRECATED";
CM_ SG_ 874 DAS_w099_DEPRECATED "Driver assistance computer: w099 DEPRECATED";
CM_ SG_ 874 DAS_w100_DEPRECATED "Driver assistance computer: w100 DEPRECATED";
CM_ SG_ 874 DAS_w101_DEPRECATED "Driver assistance computer: w101 DEPRECATED";
CM_ SG_ 874 DAS_w102_DEPRECATED "Driver assistance computer: w102 DEPRECATED";
CM_ SG_ 874 DAS_w103_robExperimentalAEB "Driver assistance computer: w103 rob experimental AEB";
CM_ SG_ 874 DAS_w104_DEPRECATED "Driver assistance computer: w104 DEPRECATED";
CM_ SG_ 874 DAS_w105_DEPRECATED "Driver assistance computer: w105 DEPRECATED";
CM_ SG_ 874 DAS_w106_torsionBarCalibrated "Driver assistance computer: w106 torsion bar calibrated";
CM_ BO_ 841 "Driver assistance computer message: warning matrix2";
CM_ SG_ 841 DAS_w129_mainCamExtNotCal "Driver assistance computer: w129 main cam ext not cal";
CM_ SG_ 841 DAS_w130_narrowCamExtNotCal "Driver assistance computer: w130 narrow cam ext not cal";
CM_ SG_ 841 DAS_w131_mainCamCalSaved "Driver assistance computer: w131 main cam cal saved";
CM_ SG_ 841 DAS_w132_narrowCamCalSaved "Driver assistance computer: w132 narrow cam cal saved";
CM_ SG_ 841 DAS_w133_mainCamInitFault "Driver assistance computer: w133 main cam init fault";
CM_ SG_ 841 DAS_w134_narrowCamInitFault "Driver assistance computer: w134 narrow cam init fault";
CM_ SG_ 841 DAS_w135_fisheyeCamInitFault "Driver assistance computer: w135 fisheye cam init fault";
CM_ SG_ 841 DAS_w136_lPillarCamInitFault "Driver assistance computer: w136 l pillar cam init fault";
CM_ SG_ 841 DAS_w137_rPillarCamInitFault "Driver assistance computer: w137 r pillar cam init fault";
CM_ SG_ 841 DAS_w138_lRepeatCamInitFault "Driver assistance computer: w138 l repeat cam init fault";
CM_ SG_ 841 DAS_w139_rRepeatCamInitFault "Driver assistance computer: w139 r repeat cam init fault";
CM_ SG_ 841 DAS_w140_backupCamInitFault "Driver assistance computer: w140 backup cam init fault";
CM_ SG_ 841 DAS_w141_ECU_Thermal_Issue "Driver assistance computer: w141 ECU thermal issue";
CM_ SG_ 841 DAS_w142_fwdCamPitchProblem "Driver assistance computer: w142 fwd cam pitch problem";
CM_ SG_ 841 DAS_w143_IDF_event "Driver assistance computer: w143 IDF event";
CM_ SG_ 841 DAS_w144_selfieCamInitFault "Driver assistance computer: w144 selfie cam init fault";
CM_ SG_ 841 DAS_w171_fisheyeCamExtNotCal "Driver assistance computer: w171 fisheye cam ext not cal";
CM_ SG_ 841 DAS_w172_lPillarCamExtNotCal "Driver assistance computer: w172 l pillar cam ext not cal";
CM_ SG_ 841 DAS_w173_rPillarCamExtNotCal "Driver assistance computer: w173 r pillar cam ext not cal";
CM_ SG_ 841 DAS_w174_lRepeatCamExtNotCal "Driver assistance computer: w174 l repeat cam ext not cal";
CM_ SG_ 841 DAS_w175_rRepeatCamExtNotCal "Driver assistance computer: w175 r repeat cam ext not cal";
CM_ SG_ 841 DAS_w177_fisheyeCamCalSaved "Driver assistance computer: w177 fisheye cam cal saved";
CM_ SG_ 841 DAS_w178_lPillarCamCalSaved "Driver assistance computer: w178 l pillar cam cal saved";
CM_ SG_ 841 DAS_w179_rPillarCamCalSaved "Driver assistance computer: w179 r pillar cam cal saved";
CM_ SG_ 841 DAS_w180_lRepeatCamCalSaved "Driver assistance computer: w180 l repeat cam cal saved";
CM_ SG_ 841 DAS_w181_rRepeatCamCalSaved "Driver assistance computer: w181 r repeat cam cal saved";
CM_ BO_ 1082 "Driver assistance computer message: warning matrix3";
CM_ SG_ 1082 DAS_w193_camWindshieldUnclean "Driver assistance computer: w193 cam windshield unclean";
CM_ SG_ 1082 DAS_w194_accDriverResumeRqrd "Driver assistance computer: w194 acc driver resume rqrd";
CM_ SG_ 1082 DAS_w195_scwUnavailable "Driver assistance computer: w195 scw unavailable";
CM_ SG_ 1082 DAS_w196_stopSignWarning "Driver assistance computer: w196 stop sign warning";
CM_ SG_ 1082 DAS_w197_redLightWarning "Driver assistance computer: w197 red light warning";
CM_ SG_ 1082 DAS_w198_tsrUnavailable "Driver assistance computer: w198 tsr unavailable";
CM_ SG_ 1082 DAS_w199_apcAbort "Driver assistance computer: w199 apc abort";
CM_ SG_ 1082 DAS_w200_lcSlowdown "Driver assistance computer: w200 lc slowdown";
CM_ SG_ 1082 DAS_w201_lcAborting "Driver assistance computer: w201 lc aborting";
CM_ SG_ 1082 DAS_w202_scwNoisyEnvironment "Driver assistance computer: w202 scw noisy environment";
CM_ SG_ 1082 DAS_w203_apcActivation "Driver assistance computer: w203 apc activation";
CM_ SG_ 1082 DAS_w204_apcFinalFront "Driver assistance computer: w204 apc final front";
CM_ SG_ 1082 DAS_w205_apcFinalRear "Driver assistance computer: w205 apc final rear";
CM_ SG_ 1082 DAS_w206_autosteerNotEnabled "Driver assistance computer: w206 autosteer not enabled";
CM_ SG_ 1082 DAS_w207_autosteerUnavailable "Driver assistance computer: w207 autosteer unavailable";
CM_ SG_ 1082 DAS_w208_rackDetected "Driver assistance computer: w208 rack detected";
CM_ SG_ 1082 DAS_w209_autoSummonRequest "Driver assistance computer: w209 auto summon request";
CM_ SG_ 1082 DAS_w210_camObstrcted "Driver assistance computer: w210 cam obstrcted";
CM_ SG_ 1082 DAS_w211_accNoSeatBelt "Driver assistance computer: w211 acc no seat belt";
CM_ SG_ 1082 DAS_w212_lcUnavailableStrikeOut "Driver assistance computer: w212 lc unavailable strike out";
CM_ SG_ 1082 DAS_w213_autosteerStruckOut "Driver assistance computer: w213 autosteer struck out";
CM_ SG_ 1082 DAS_w214_driverNotIntracting "Driver assistance computer: w214 driver not intracting";
CM_ SG_ 1082 DAS_w215_contDriverNotIntracting "Driver assistance computer: w215 cont driver not intracting";
CM_ SG_ 1082 DAS_w216_driverOverriding "Driver assistance computer: w216 driver overriding";
CM_ SG_ 1082 DAS_w217_lcUnavailableSpeeding "Driver assistance computer: w217 lc unavailable speeding";
CM_ SG_ 1082 DAS_w218_lcSpeedExceededLimit "Driver assistance computer: w218 lc speed exceeded limit";
CM_ SG_ 1082 DAS_w219_lcTempUnavailableSpeed "Driver assistance computer: w219 lc temp unavailable speed";
CM_ SG_ 1082 DAS_w220_lcTempUnavailableRoad "Driver assistance computer: w220 lc temp unavailable road";
CM_ SG_ 1082 DAS_w221_accRadarBlind "Driver assistance computer: w221 acc radar blind";
CM_ SG_ 1082 DAS_w222_accCameraBlind "Driver assistance computer: w222 acc camera blind";
CM_ SG_ 1082 DAS_w223_accObjectInPath "Driver assistance computer: w223 acc object in path";
CM_ SG_ 1082 DAS_w224_accCameraCalibration "Driver assistance computer: w224 acc camera calibration";
CM_ SG_ 1082 DAS_w225_lcDegradedVisSpeedLmt "Driver assistance computer: w225 lc degraded vis speed lmt";
CM_ SG_ 1082 DAS_w226_lcCamCalNeededSpeedLmt "Driver assistance computer: w226 lc cam cal needed speed lmt";
CM_ SG_ 1082 DAS_w227_virtualWallBlocked "Driver assistance computer: w227 virtual wall blocked";
CM_ SG_ 1082 DAS_w228_DEPRECATED "Driver assistance computer: w228 DEPRECATED";
CM_ SG_ 1082 DAS_w229_alcUltrasoundDamaged "Driver assistance computer: w229 alc ultrasound damaged";
CM_ SG_ 1082 DAS_w230_alcUltrasoundBlocked "Driver assistance computer: w230 alc ultrasound blocked";
CM_ SG_ 1082 DAS_w231_idfEvent "Driver assistance computer: w231 idf event";
CM_ SG_ 1082 DAS_w232_laneChangeRequested "Driver assistance computer: w232 lane change requested";
CM_ BO_ 1318 "Front drive inverter message: alert log";
CM_ SG_ 1318 DIF_alertID "Front drive inverter: alert ID";
CM_ SG_ 1318 DIF_alertState "Front drive inverter: alert state";
CM_ SG_ 1318 DIF_a001_thermalWarning_H "Front drive inverter: a001 thermal warning h";
CM_ SG_ 1318 DIF_a001_thermalShutdown_H "Front drive inverter: a001 thermal shutdown h";
CM_ SG_ 1318 DIF_a001_undervoltVL_H "Front drive inverter: a001 undervolt VL h";
CM_ SG_ 1318 DIF_a001_undervoltVH_H "Front drive inverter: a001 undervolt VH h";
CM_ SG_ 1318 DIF_a001_sense_H "Front drive inverter: a001 sense h";
CM_ SG_ 1318 DIF_a001_desat_H "Front drive inverter: a001 desat h";
CM_ SG_ 1318 DIF_a001_overvoltVL_H "Front drive inverter: a001 overvolt VL h";
CM_ SG_ 1318 DIF_a001_overvoltVH_H "Front drive inverter: a001 overvolt VH h";
CM_ SG_ 1318 DIF_a001_undervoltVCC_H "Front drive inverter: a001 undervolt VCC h";
CM_ SG_ 1318 DIF_a001_asynchStop_H "Front drive inverter: a001 asynch stop h";
CM_ SG_ 1318 DIF_a001_remoteRegError_H "Front drive inverter: a001 remote reg error h";
CM_ SG_ 1318 DIF_a001_undervoltVDD_H "Front drive inverter: a001 undervolt VDD h";
CM_ SG_ 1318 DIF_a001_overvoltVDD_H "Front drive inverter: a001 overvolt VDD h";
CM_ SG_ 1318 DIF_a001_localRegError_H "Front drive inverter: a001 local reg error h";
CM_ SG_ 1318 DIF_a001_spiError_H "Front drive inverter: a001 spi error h";
CM_ SG_ 1318 DIF_a001_deadtimeError_H "Front drive inverter: a001 deadtime error h";
CM_ SG_ 1318 DIF_a001_thermalWarning_L "Front drive inverter: a001 thermal warning l";
CM_ SG_ 1318 DIF_a001_thermalShutdown_L "Front drive inverter: a001 thermal shutdown l";
CM_ SG_ 1318 DIF_a001_undervoltVL_L "Front drive inverter: a001 undervolt VL l";
CM_ SG_ 1318 DIF_a001_undervoltVH_L "Front drive inverter: a001 undervolt VH l";
CM_ SG_ 1318 DIF_a001_sense_L "Front drive inverter: a001 sense l";
CM_ SG_ 1318 DIF_a001_desat_L "Front drive inverter: a001 desat l";
CM_ SG_ 1318 DIF_a001_overvoltVL_L "Front drive inverter: a001 overvolt VL l";
CM_ SG_ 1318 DIF_a001_overvoltVH_L "Front drive inverter: a001 overvolt VH l";
CM_ SG_ 1318 DIF_a001_undervoltVCC_L "Front drive inverter: a001 undervolt VCC l";
CM_ SG_ 1318 DIF_a001_asynchStop_L "Front drive inverter: a001 asynch stop l";
CM_ SG_ 1318 DIF_a001_remoteRegError_L "Front drive inverter: a001 remote reg error l";
CM_ SG_ 1318 DIF_a001_undervoltVDD_L "Front drive inverter: a001 undervolt VDD l";
CM_ SG_ 1318 DIF_a001_overvoltVDD_L "Front drive inverter: a001 overvolt VDD l";
CM_ SG_ 1318 DIF_a001_localRegError_L "Front drive inverter: a001 local reg error l";
CM_ SG_ 1318 DIF_a001_spiError_L "Front drive inverter: a001 spi error l";
CM_ SG_ 1318 DIF_a001_deadtimeError_L "Front drive inverter: a001 deadtime error l";
CM_ SG_ 1318 DIF_a001_gateDriveErrCounter "Front drive inverter: a001 gate drive err counter";
CM_ SG_ 1318 DIF_a001_remoteCommError_H "Front drive inverter: a001 remote comm error h";
CM_ SG_ 1318 DIF_a001_localCommError_H "Front drive inverter: a001 local comm error h";
CM_ SG_ 1318 DIF_a001_remoteReset_H "Front drive inverter: a001 remote reset h";
CM_ SG_ 1318 DIF_a001_localReset_H "Front drive inverter: a001 local reset h";
CM_ SG_ 1318 DIF_a001_remoteCommError_L "Front drive inverter: a001 remote comm error l";
CM_ SG_ 1318 DIF_a001_localCommError_L "Front drive inverter: a001 local comm error l";
CM_ SG_ 1318 DIF_a001_remoteReset_L "Front drive inverter: a001 remote reset l";
CM_ SG_ 1318 DIF_a001_localReset_L "Front drive inverter: a001 local reset l";
CM_ SG_ 1318 DIF_a001_faultLine1Gpio_H "Front drive inverter: a001 fault line1 gpio h";
CM_ SG_ 1318 DIF_a001_faultLine1Gpio_L "Front drive inverter: a001 fault line1 gpio l";
CM_ SG_ 1318 DIF_a002_thermalWarning_H "Front drive inverter: a002 thermal warning h";
CM_ SG_ 1318 DIF_a002_thermalShutdown_H "Front drive inverter: a002 thermal shutdown h";
CM_ SG_ 1318 DIF_a002_undervoltVL_H "Front drive inverter: a002 undervolt VL h";
CM_ SG_ 1318 DIF_a002_undervoltVH_H "Front drive inverter: a002 undervolt VH h";
CM_ SG_ 1318 DIF_a002_sense_H "Front drive inverter: a002 sense h";
CM_ SG_ 1318 DIF_a002_desat_H "Front drive inverter: a002 desat h";
CM_ SG_ 1318 DIF_a002_overvoltVL_H "Front drive inverter: a002 overvolt VL h";
CM_ SG_ 1318 DIF_a002_overvoltVH_H "Front drive inverter: a002 overvolt VH h";
CM_ SG_ 1318 DIF_a002_undervoltVCC_H "Front drive inverter: a002 undervolt VCC h";
CM_ SG_ 1318 DIF_a002_asynchStop_H "Front drive inverter: a002 asynch stop h";
CM_ SG_ 1318 DIF_a002_remoteRegError_H "Front drive inverter: a002 remote reg error h";
CM_ SG_ 1318 DIF_a002_undervoltVDD_H "Front drive inverter: a002 undervolt VDD h";
CM_ SG_ 1318 DIF_a002_overvoltVDD_H "Front drive inverter: a002 overvolt VDD h";
CM_ SG_ 1318 DIF_a002_localRegError_H "Front drive inverter: a002 local reg error h";
CM_ SG_ 1318 DIF_a002_spiError_H "Front drive inverter: a002 spi error h";
CM_ SG_ 1318 DIF_a002_deadtimeError_H "Front drive inverter: a002 deadtime error h";
CM_ SG_ 1318 DIF_a002_thermalWarning_L "Front drive inverter: a002 thermal warning l";
CM_ SG_ 1318 DIF_a002_thermalShutdown_L "Front drive inverter: a002 thermal shutdown l";
CM_ SG_ 1318 DIF_a002_undervoltVL_L "Front drive inverter: a002 undervolt VL l";
CM_ SG_ 1318 DIF_a002_undervoltVH_L "Front drive inverter: a002 undervolt VH l";
CM_ SG_ 1318 DIF_a002_sense_L "Front drive inverter: a002 sense l";
CM_ SG_ 1318 DIF_a002_desat_L "Front drive inverter: a002 desat l";
CM_ SG_ 1318 DIF_a002_overvoltVL_L "Front drive inverter: a002 overvolt VL l";
CM_ SG_ 1318 DIF_a002_overvoltVH_L "Front drive inverter: a002 overvolt VH l";
CM_ SG_ 1318 DIF_a002_undervoltVCC_L "Front drive inverter: a002 undervolt VCC l";
CM_ SG_ 1318 DIF_a002_asynchStop_L "Front drive inverter: a002 asynch stop l";
CM_ SG_ 1318 DIF_a002_remoteRegError_L "Front drive inverter: a002 remote reg error l";
CM_ SG_ 1318 DIF_a002_undervoltVDD_L "Front drive inverter: a002 undervolt VDD l";
CM_ SG_ 1318 DIF_a002_overvoltVDD_L "Front drive inverter: a002 overvolt VDD l";
CM_ SG_ 1318 DIF_a002_localRegError_L "Front drive inverter: a002 local reg error l";
CM_ SG_ 1318 DIF_a002_spiError_L "Front drive inverter: a002 spi error l";
CM_ SG_ 1318 DIF_a002_deadtimeError_L "Front drive inverter: a002 deadtime error l";
CM_ SG_ 1318 DIF_a002_gateDriveErrCounter "Front drive inverter: a002 gate drive err counter";
CM_ SG_ 1318 DIF_a002_selftestDesat_L "Front drive inverter: a002 selftest desat l";
CM_ SG_ 1318 DIF_a002_selftestDesat_H "Front drive inverter: a002 selftest desat h";
CM_ SG_ 1318 DIF_a002_remoteCommError_H "Front drive inverter: a002 remote comm error h";
CM_ SG_ 1318 DIF_a002_localCommError_H "Front drive inverter: a002 local comm error h";
CM_ SG_ 1318 DIF_a002_remoteReset_H "Front drive inverter: a002 remote reset h";
CM_ SG_ 1318 DIF_a002_localReset_H "Front drive inverter: a002 local reset h";
CM_ SG_ 1318 DIF_a002_remoteCommError_L "Front drive inverter: a002 remote comm error l";
CM_ SG_ 1318 DIF_a002_localCommError_L "Front drive inverter: a002 local comm error l";
CM_ SG_ 1318 DIF_a002_remoteReset_L "Front drive inverter: a002 remote reset l";
CM_ SG_ 1318 DIF_a002_localReset_L "Front drive inverter: a002 local reset l";
CM_ SG_ 1318 DIF_a002_faultLine1Gpio_H "Front drive inverter: a002 fault line1 gpio h";
CM_ SG_ 1318 DIF_a002_faultLine1Gpio_L "Front drive inverter: a002 fault line1 gpio l";
CM_ SG_ 1318 DIF_a003_thermalWarning_H "Front drive inverter: a003 thermal warning h";
CM_ SG_ 1318 DIF_a003_thermalShutdown_H "Front drive inverter: a003 thermal shutdown h";
CM_ SG_ 1318 DIF_a003_undervoltVL_H "Front drive inverter: a003 undervolt VL h";
CM_ SG_ 1318 DIF_a003_undervoltVH_H "Front drive inverter: a003 undervolt VH h";
CM_ SG_ 1318 DIF_a003_sense_H "Front drive inverter: a003 sense h";
CM_ SG_ 1318 DIF_a003_desat_H "Front drive inverter: a003 desat h";
CM_ SG_ 1318 DIF_a003_overvoltVL_H "Front drive inverter: a003 overvolt VL h";
CM_ SG_ 1318 DIF_a003_overvoltVH_H "Front drive inverter: a003 overvolt VH h";
CM_ SG_ 1318 DIF_a003_undervoltVCC_H "Front drive inverter: a003 undervolt VCC h";
CM_ SG_ 1318 DIF_a003_asynchStop_H "Front drive inverter: a003 asynch stop h";
CM_ SG_ 1318 DIF_a003_remoteRegError_H "Front drive inverter: a003 remote reg error h";
CM_ SG_ 1318 DIF_a003_undervoltVDD_H "Front drive inverter: a003 undervolt VDD h";
CM_ SG_ 1318 DIF_a003_overvoltVDD_H "Front drive inverter: a003 overvolt VDD h";
CM_ SG_ 1318 DIF_a003_localRegError_H "Front drive inverter: a003 local reg error h";
CM_ SG_ 1318 DIF_a003_spiError_H "Front drive inverter: a003 spi error h";
CM_ SG_ 1318 DIF_a003_deadtimeError_H "Front drive inverter: a003 deadtime error h";
CM_ SG_ 1318 DIF_a003_thermalWarning_L "Front drive inverter: a003 thermal warning l";
CM_ SG_ 1318 DIF_a003_thermalShutdown_L "Front drive inverter: a003 thermal shutdown l";
CM_ SG_ 1318 DIF_a003_undervoltVL_L "Front drive inverter: a003 undervolt VL l";
CM_ SG_ 1318 DIF_a003_undervoltVH_L "Front drive inverter: a003 undervolt VH l";
CM_ SG_ 1318 DIF_a003_sense_L "Front drive inverter: a003 sense l";
CM_ SG_ 1318 DIF_a003_desat_L "Front drive inverter: a003 desat l";
CM_ SG_ 1318 DIF_a003_overvoltVL_L "Front drive inverter: a003 overvolt VL l";
CM_ SG_ 1318 DIF_a003_overvoltVH_L "Front drive inverter: a003 overvolt VH l";
CM_ SG_ 1318 DIF_a003_undervoltVCC_L "Front drive inverter: a003 undervolt VCC l";
CM_ SG_ 1318 DIF_a003_asynchStop_L "Front drive inverter: a003 asynch stop l";
CM_ SG_ 1318 DIF_a003_remoteRegError_L "Front drive inverter: a003 remote reg error l";
CM_ SG_ 1318 DIF_a003_undervoltVDD_L "Front drive inverter: a003 undervolt VDD l";
CM_ SG_ 1318 DIF_a003_overvoltVDD_L "Front drive inverter: a003 overvolt VDD l";
CM_ SG_ 1318 DIF_a003_localRegError_L "Front drive inverter: a003 local reg error l";
CM_ SG_ 1318 DIF_a003_spiError_L "Front drive inverter: a003 spi error l";
CM_ SG_ 1318 DIF_a003_deadtimeError_L "Front drive inverter: a003 deadtime error l";
CM_ SG_ 1318 DIF_a003_gateDriveErrCounter "Front drive inverter: a003 gate drive err counter";
CM_ SG_ 1318 DIF_a003_selftestDesat_L "Front drive inverter: a003 selftest desat l";
CM_ SG_ 1318 DIF_a003_selftestDesat_H "Front drive inverter: a003 selftest desat h";
CM_ SG_ 1318 DIF_a003_remoteCommError_H "Front drive inverter: a003 remote comm error h";
CM_ SG_ 1318 DIF_a003_localCommError_H "Front drive inverter: a003 local comm error h";
CM_ SG_ 1318 DIF_a003_remoteReset_H "Front drive inverter: a003 remote reset h";
CM_ SG_ 1318 DIF_a003_localReset_H "Front drive inverter: a003 local reset h";
CM_ SG_ 1318 DIF_a003_remoteCommError_L "Front drive inverter: a003 remote comm error l";
CM_ SG_ 1318 DIF_a003_localCommError_L "Front drive inverter: a003 local comm error l";
CM_ SG_ 1318 DIF_a003_remoteReset_L "Front drive inverter: a003 remote reset l";
CM_ SG_ 1318 DIF_a003_localReset_L "Front drive inverter: a003 local reset l";
CM_ SG_ 1318 DIF_a003_faultLine1Gpio_H "Front drive inverter: a003 fault line1 gpio h";
CM_ SG_ 1318 DIF_a003_faultLine1Gpio_L "Front drive inverter: a003 fault line1 gpio l";
CM_ SG_ 1318 DIF_a007_phaseAcurrent "Front drive inverter: a007 phase acurrent";
CM_ SG_ 1318 DIF_a007_phaseBcurrent "Front drive inverter: a007 phase bcurrent";
CM_ SG_ 1318 DIF_a007_offsetError "Front drive inverter: a007 offset error";
CM_ SG_ 1318 DIF_a007_idFdbStdDeviation "Front drive inverter: a007 id fdb std deviation";
CM_ SG_ 1318 DIF_a007_iqFdbStdDeviation "Front drive inverter: a007 iq fdb std deviation";
CM_ SG_ 1318 DIF_a007_motorShift "Front drive inverter: a007 motor shift";
CM_ SG_ 1318 DIF_a007_motorShort "Front drive inverter: a007 motor short";
CM_ SG_ 1318 DIF_a010_sccReset "Front drive inverter: a010 scc reset";
CM_ SG_ 1318 DIF_a010_hibernate "Front drive inverter: a010 hibernate";
CM_ SG_ 1318 DIF_a010_hwBist "Front drive inverter: a010 hw bist";
CM_ SG_ 1318 DIF_a010_nmiWatchdog "Front drive inverter: a010 nmi watchdog";
CM_ SG_ 1318 DIF_a010_watchdog "Front drive inverter: a010 watchdog";
CM_ SG_ 1318 DIF_a010_clockFailNmi "Front drive inverter: a010 clock fail nmi";
CM_ SG_ 1318 DIF_a010_ramUncErrorNmi "Front drive inverter: a010 ram unc error nmi";
CM_ SG_ 1318 DIF_a010_flashUncErrorNmi "Front drive inverter: a010 flash unc error nmi";
CM_ SG_ 1318 DIF_a010_cpu1signMismatchNmi "Front drive inverter: a010 cpu1sign mismatch nmi";
CM_ SG_ 1318 DIF_a010_cpu2signMismatchNmi "Front drive inverter: a010 cpu2sign mismatch nmi";
CM_ SG_ 1318 DIF_a010_pieVectErrorNmi "Front drive inverter: a010 pie vect error nmi";
CM_ SG_ 1318 DIF_a010_sysDbgNmi "Front drive inverter: a010 sys dbg nmi";
CM_ SG_ 1318 DIF_a010_rlNmi "Front drive inverter: a010 rl nmi";
CM_ SG_ 1318 DIF_a010_ovfNmi "Front drive inverter: a010 ovf nmi";
CM_ SG_ 1318 DIF_a010_wdtFlags "Front drive inverter: a010 wdt flags";
CM_ SG_ 1318 DIF_a011_reason "Front drive inverter: a011 reason";
CM_ SG_ 1318 DIF_a011_phaseAHigh "Front drive inverter: a011 phase a high";
CM_ SG_ 1318 DIF_a011_phaseALow "Front drive inverter: a011 phase a low";
CM_ SG_ 1318 DIF_a011_phaseBHigh "Front drive inverter: a011 phase b high";
CM_ SG_ 1318 DIF_a011_phaseBLow "Front drive inverter: a011 phase b low";
CM_ SG_ 1318 DIF_a011_phaseCHigh "Front drive inverter: a011 phase c high";
CM_ SG_ 1318 DIF_a011_phaseCLow "Front drive inverter: a011 phase c low";
CM_ SG_ 1318 DIF_a011_regAddress "Front drive inverter: a011 reg address";
CM_ SG_ 1318 DIF_a011_badGateDriveIC "Front drive inverter: a011 bad gate drive IC";
CM_ SG_ 1318 DIF_a011_badDataRead "Front drive inverter: a011 bad data read";
CM_ SG_ 1318 DIF_a011_badDataExpected "Front drive inverter: a011 bad data expected";
CM_ SG_ 1318 DIF_a011_codeBranch "Front drive inverter: a011 code branch";
CM_ SG_ 1318 DIF_a012_hvilStatus "Front drive inverter: a012 hvil status";
CM_ SG_ 1318 DIF_a012_hvilCmVoltage "Front drive inverter: a012 hvil cm voltage";
CM_ SG_ 1318 DIF_a012_hvilCurrent "Front drive inverter: a012 hvil current";
CM_ SG_ 1318 DIF_a012_hvilFaultGpio "Front drive inverter: a012 hvil fault gpio";
CM_ SG_ 1318 DIF_a012_hvilSupplyPinDI "Front drive inverter: a012 hvil supply pin DI";
CM_ SG_ 1318 DIF_a012_hvilSupplyPinPM "Front drive inverter: a012 hvil supply pin PM";
CM_ SG_ 1318 DIF_a012_activeDisOn3V3 "Front drive inverter: a012 active dis on3 V3";
CM_ SG_ 1318 DIF_a012_hvilHeaderFault "Front drive inverter: a012 hvil header fault";
CM_ SG_ 1318 DIF_a013_address "Front drive inverter: a013 address";
CM_ SG_ 1318 DIF_a013_errorType "Front drive inverter: a013 error type";
CM_ SG_ 1318 DIF_a014_motorSpeed "Front drive inverter: a014 motor speed";
CM_ SG_ 1318 DIF_a014_adState "Front drive inverter: a014 ad state";
CM_ SG_ 1318 DIF_a014_torqueCommandFwd "Front drive inverter: a014 torque command fwd";
CM_ SG_ 1318 DIF_a014_brakeMasterCylPress "Front drive inverter: a014 brake master cyl press";
CM_ SG_ 1318 DIF_a014_rmsTorqueError "Front drive inverter: a014 rms torque error";
CM_ SG_ 1318 DIF_a014_tcEnabled "Front drive inverter: a014 tc enabled";
CM_ SG_ 1318 DIF_a016_newSafeState "Front drive inverter: a016 new safe state";
CM_ SG_ 1318 DIF_a016_oldSafeState "Front drive inverter: a016 old safe state";
CM_ SG_ 1318 DIF_a016_gateDriveFaultLine "Front drive inverter: a016 gate drive fault line";
CM_ SG_ 1318 DIF_a016_ascMonitor "Front drive inverter: a016 asc monitor";
CM_ SG_ 1318 DIF_a016_uncontrolledRegenZone "Front drive inverter: a016 uncontrolled regen zone";
CM_ SG_ 1318 DIF_a016_pedalMonitorPreWatchdog "Front drive inverter: a016 pedal monitor pre watchdog";
CM_ SG_ 1318 DIF_a016_motorRPM "Front drive inverter: a016 motor RPM";
CM_ SG_ 1318 DIF_a016_torqueMotor "Front drive inverter: a016 torque motor";
CM_ SG_ 1318 DIF_a016_safetyICfaultLine "Front drive inverter: a016 safety i cfault line";
CM_ SG_ 1318 DIF_a016_triggerEvent "Front drive inverter: a016 trigger event";
CM_ SG_ 1318 DIF_a024_vBat "Front drive inverter: a024 v bat";
CM_ SG_ 1318 DIF_a024_failReason "Front drive inverter: a024 fail reason";
CM_ SG_ 1318 DIF_a024_state "Front drive inverter: a024 state";
CM_ SG_ 1318 DIF_a024_Ia "Front drive inverter: a024 ia";
CM_ SG_ 1318 DIF_a024_Ib "Front drive inverter: a024 ib";
CM_ SG_ 1318 DIF_a024_maxCurrMagSqrd "Front drive inverter: a024 max curr mag sqrd";
CM_ SG_ 1318 DIF_a024_rotorAngle "Front drive inverter: a024 rotor angle";
CM_ SG_ 1318 DIF_a025_Ia "Front drive inverter: a025 ia";
CM_ SG_ 1318 DIF_a025_torqueMotor "Front drive inverter: a025 torque motor";
CM_ SG_ 1318 DIF_a025_motorSpeed "Front drive inverter: a025 motor speed";
CM_ SG_ 1318 DIF_a026_Ib "Front drive inverter: a026 ib";
CM_ SG_ 1318 DIF_a026_torqueMotor "Front drive inverter: a026 torque motor";
CM_ SG_ 1318 DIF_a026_motorSpeed "Front drive inverter: a026 motor speed";
CM_ SG_ 1318 DIF_a027_Ic "Front drive inverter: a027 ic";
CM_ SG_ 1318 DIF_a027_torqueMotor "Front drive inverter: a027 torque motor";
CM_ SG_ 1318 DIF_a027_motorSpeed "Front drive inverter: a027 motor speed";
CM_ SG_ 1318 DIF_a028_phaseAirms "Front drive inverter: a028 phase airms";
CM_ SG_ 1318 DIF_a028_iArmsTorque "Front drive inverter: a028 i arms torque";
CM_ SG_ 1318 DIF_a028_iArmsSpeed "Front drive inverter: a028 i arms speed";
CM_ SG_ 1318 DIF_a029_phaseBirms "Front drive inverter: a029 phase birms";
CM_ SG_ 1318 DIF_a029_iBrmsTorque "Front drive inverter: a029 i brms torque";
CM_ SG_ 1318 DIF_a029_iBrmsSpeed "Front drive inverter: a029 i brms speed";
CM_ SG_ 1318 DIF_a030_phaseCirms "Front drive inverter: a030 phase cirms";
CM_ SG_ 1318 DIF_a030_iCrmsTorque "Front drive inverter: a030 i crms torque";
CM_ SG_ 1318 DIF_a030_iCrmsSpeed "Front drive inverter: a030 i crms speed";
CM_ SG_ 1318 DIF_a031_phaseAoffset "Front drive inverter: a031 phase aoffset";
CM_ SG_ 1318 DIF_a032_phaseBoffset "Front drive inverter: a032 phase boffset";
CM_ SG_ 1318 DIF_a033_phaseAcurrent "Front drive inverter: a033 phase acurrent";
CM_ SG_ 1318 DIF_a033_deltaIa "Front drive inverter: a033 delta ia";
CM_ SG_ 1318 DIF_a033_vRefIa "Front drive inverter: a033 v ref ia";
CM_ SG_ 1318 DIF_a034_phaseBcurrent "Front drive inverter: a034 phase bcurrent";
CM_ SG_ 1318 DIF_a034_deltaIb "Front drive inverter: a034 delta ib";
CM_ SG_ 1318 DIF_a034_vRefIb "Front drive inverter: a034 v ref ib";
CM_ SG_ 1318 DIF_a035_phaseAerror "Front drive inverter: a035 phase aerror";
CM_ SG_ 1318 DIF_a035_phaseBerror "Front drive inverter: a035 phase berror";
CM_ SG_ 1318 DIF_a035_phaseCerror "Front drive inverter: a035 phase cerror";
CM_ SG_ 1318 DIF_a035_standbyCurrent "Front drive inverter: a035 standby current";
CM_ SG_ 1318 DIF_a035_unbalancedCurrent "Front drive inverter: a035 unbalanced current";
CM_ SG_ 1318 DIF_a035_wontMoveCurrent "Front drive inverter: a035 wont move current";
CM_ SG_ 1318 DIF_a035_reportingPhase "Front drive inverter: a035 reporting phase";
CM_ SG_ 1318 DIF_a035_noDriveCurrent "Front drive inverter: a035 no drive current";
CM_ SG_ 1318 DIF_a035_phaseDifference "Front drive inverter: a035 phase difference";
CM_ SG_ 1318 DIF_a035_phaseCurrent "Front drive inverter: a035 phase current";
CM_ SG_ 1318 DIF_a035_frequency "Front drive inverter: a035 frequency";
CM_ SG_ 1318 DIF_a036_busVoltage "Front drive inverter: a036 bus voltage";
CM_ SG_ 1318 DIF_a036_busHighLimit "Front drive inverter: a036 bus high limit";
CM_ SG_ 1318 DIF_a037_busVoltage "Front drive inverter: a037 bus voltage";
CM_ SG_ 1318 DIF_a037_busLowLimit "Front drive inverter: a037 bus low limit";
CM_ SG_ 1318 DIF_a038_vBMS "Front drive inverter: a038 v BMS";
CM_ SG_ 1318 DIF_a038_vBat "Front drive inverter: a038 v bat";
CM_ SG_ 1318 DIF_a038_iBat "Front drive inverter: a038 i bat";
CM_ SG_ 1318 DIF_a038_reason "Front drive inverter: a038 reason";
CM_ SG_ 1318 DIF_a040_torque "Front drive inverter: a040 torque";
CM_ SG_ 1318 DIF_a040_capability "Front drive inverter: a040 capability";
CM_ SG_ 1318 DIF_a040_power "Front drive inverter: a040 power";
CM_ SG_ 1318 DIF_a040_status "Front drive inverter: a040 status";
CM_ SG_ 1318 DIF_a040_capability2 "Front drive inverter: a040 capability2";
CM_ SG_ 1318 DIF_a040_hvStatus "Front drive inverter: a040 hv status";
CM_ SG_ 1318 DIF_a040_temperature "Front drive inverter: a040 temperature";
CM_ SG_ 1318 DIF_a041_uartRxDataAvailable "Front drive inverter: a041 uart rx data available";
CM_ SG_ 1318 DIF_a041_SDC_status_MIA "Front drive inverter: a041 SDC status MIA";
CM_ SG_ 1318 DIF_a041_diUartRxVersion "Front drive inverter: a041 di uart rx version";
CM_ SG_ 1318 DIF_a041_sdcUartRxVersion "Front drive inverter: a041 sdc uart rx version";
CM_ SG_ 1318 DIF_a043_outletTemp "Front drive inverter: a043 outlet temp";
CM_ SG_ 1318 DIF_a044_outletTemp "Front drive inverter: a044 outlet temp";
CM_ SG_ 1318 DIF_a045_inletTemp "Front drive inverter: a045 inlet temp";
CM_ SG_ 1318 DIF_a045_outletTemp "Front drive inverter: a045 outlet temp";
CM_ SG_ 1318 DIF_a045_heatsinkTemp "Front drive inverter: a045 heatsink temp";
CM_ SG_ 1318 DIF_a045_outletTempSlope "Front drive inverter: a045 outlet temp slope";
CM_ SG_ 1318 DIF_a046_statorTemp1 "Front drive inverter: a046 stator temp1";
CM_ SG_ 1318 DIF_a046_statorTemp2 "Front drive inverter: a046 stator temp2";
CM_ SG_ 1318 DIF_a047_statorTemp1 "Front drive inverter: a047 stator temp1";
CM_ SG_ 1318 DIF_a047_statorTslope1 "Front drive inverter: a047 stator tslope1";
CM_ SG_ 1318 DIF_a050_statorTemp1 "Front drive inverter: a050 stator temp1";
CM_ SG_ 1318 DIF_a050_statorTemp2 "Front drive inverter: a050 stator temp2";
CM_ SG_ 1318 DIF_a052_torque "Front drive inverter: a052 torque";
CM_ SG_ 1318 DIF_a052_capability "Front drive inverter: a052 capability";
CM_ SG_ 1318 DIF_a052_power "Front drive inverter: a052 power";
CM_ SG_ 1318 DIF_a052_status "Front drive inverter: a052 status";
CM_ SG_ 1318 DIF_a052_capability2 "Front drive inverter: a052 capability2";
CM_ SG_ 1318 DIF_a052_hvStatus "Front drive inverter: a052 hv status";
CM_ SG_ 1318 DIF_a052_temperature "Front drive inverter: a052 temperature";
CM_ SG_ 1318 DIF_a054_outletTemp "Front drive inverter: a054 outlet temp";
CM_ SG_ 1318 DIF_a054_heatsinkTemp "Front drive inverter: a054 heatsink temp";
CM_ SG_ 1318 DIF_a055_parameterDI "Front drive inverter: a055 parameter DI";
CM_ SG_ 1318 DIF_a055_parameterPM "Front drive inverter: a055 parameter PM";
CM_ SG_ 1318 DIF_a055_torqueType "Front drive inverter: a055 torque type";
CM_ SG_ 1318 DIF_a055_motorRPM "Front drive inverter: a055 motor RPM";
CM_ SG_ 1318 DIF_a056_pcbTemp "Front drive inverter: a056 pcb temp";
CM_ SG_ 1318 DIF_a057_pcbTemp "Front drive inverter: a057 pcb temp";
CM_ SG_ 1318 DIF_a058_pcbTemp "Front drive inverter: a058 pcb temp";
CM_ SG_ 1318 DIF_a058_outletTemp "Front drive inverter: a058 outlet temp";
CM_ SG_ 1318 DIF_a058_heatsinkTemp "Front drive inverter: a058 heatsink temp";
CM_ SG_ 1318 DIF_a058_pcbTempSlope "Front drive inverter: a058 pcb temp slope";
CM_ SG_ 1318 DIF_a059_heatsinkTemp "Front drive inverter: a059 heatsink temp";
CM_ SG_ 1318 DIF_a060_heatsinkTemp "Front drive inverter: a060 heatsink temp";
CM_ SG_ 1318 DIF_a061_sensor "Front drive inverter: a061 sensor";
CM_ SG_ 1318 DIF_a061_reason "Front drive inverter: a061 reason";
CM_ SG_ 1318 DIF_a061_phTemp "Front drive inverter: a061 ph temp";
CM_ SG_ 1318 DIF_a061_otherTemp "Front drive inverter: a061 other temp";
CM_ SG_ 1318 DIF_a062_limpReason "Front drive inverter: a062 limp reason";
CM_ SG_ 1318 DIF_a063_BB_status "Front drive inverter: a063 BB status";
CM_ SG_ 1318 DIF_a064_interventionType "Front drive inverter: a064 intervention type";
CM_ SG_ 1318 DIF_a064_torqueCmdState "Front drive inverter: a064 torque cmd state";
CM_ SG_ 1318 DIF_a066_badValue1 "Front drive inverter: a066 bad value1";
CM_ SG_ 1318 DIF_a066_badValue2 "Front drive inverter: a066 bad value2";
CM_ SG_ 1318 DIF_a066_canID "Front drive inverter: a066 can ID";
CM_ SG_ 1318 DIF_a066_errorType "Front drive inverter: a066 error type";
CM_ SG_ 1318 DIF_a069_motorSpeed "Front drive inverter: a069 motor speed";
CM_ SG_ 1318 DIF_a069_rotorCoolingPower "Front drive inverter: a069 rotor cooling power";
CM_ SG_ 1318 DIF_a069_rotorMagnetTemp "Front drive inverter: a069 rotor magnet temp";
CM_ SG_ 1318 DIF_a069_fittedTorqueLimit "Front drive inverter: a069 fitted torque limit";
CM_ SG_ 1318 DIF_a072_reason "Front drive inverter: a072 reason";
CM_ SG_ 1318 DIF_a073_motorSpeedrpm "Front drive inverter: a073 motor speedrpm";
CM_ SG_ 1318 DIF_a075_motorSpeed "Front drive inverter: a075 motor speed";
CM_ SG_ 1318 DIF_a075_absSpeed "Front drive inverter: a075 abs speed";
CM_ SG_ 1318 DIF_a076_lvSupplyV "Front drive inverter: a076 lv supply v";
CM_ SG_ 1318 DIF_a077_lvSupplyV "Front drive inverter: a077 lv supply v";
CM_ SG_ 1318 DIF_a078_adcRefChan "Front drive inverter: a078 adc ref chan";
CM_ SG_ 1318 DIF_a078_adcRefLowAvg "Front drive inverter: a078 adc ref low avg";
CM_ SG_ 1318 DIF_a079_adcRefChan "Front drive inverter: a079 adc ref chan";
CM_ SG_ 1318 DIF_a079_adcRefHighAvg "Front drive inverter: a079 adc ref high avg";
CM_ SG_ 1318 DIF_a087_gtwCarConfig "Front drive inverter: a087 gtw car config";
CM_ SG_ 1318 DIF_a087_gtwTime "Front drive inverter: a087 gtw time";
CM_ SG_ 1318 DIF_a087_gtwUpdateStatus "Front drive inverter: a087 gtw update status";
CM_ SG_ 1318 DIF_a087_gearControl "Front drive inverter: a087 gear control";
CM_ SG_ 1318 DIF_a087_carState "Front drive inverter: a087 car state";
CM_ SG_ 1318 DIF_a090_reason "Front drive inverter: a090 reason";
CM_ SG_ 1318 DIF_a090_systemState "Front drive inverter: a090 system state";
CM_ SG_ 1318 DIF_a090_state "Front drive inverter: a090 state";
CM_ SG_ 1318 DIF_a090_locState "Front drive inverter: a090 loc state";
CM_ SG_ 1318 DIF_a090_state2 "Front drive inverter: a090 state2";
CM_ SG_ 1318 DIF_a090_state4 "Front drive inverter: a090 state4";
CM_ SG_ 1318 DIF_a091_ESP_brakeTorque "Front drive inverter: a091 ESP brake torque";
CM_ SG_ 1318 DIF_a091_ESP_wheelSpeeds "Front drive inverter: a091 ESP wheel speeds";
CM_ SG_ 1318 DIF_a091_ESP_wheelRotation "Front drive inverter: a091 ESP wheel rotation";
CM_ SG_ 1318 DIF_a091_ESP_motorLimits "Front drive inverter: a091 ESP motor limits";
CM_ SG_ 1318 DIF_a091_ESP_offsets "Front drive inverter: a091 ESP offsets";
CM_ SG_ 1318 DIF_a091_ESP_status "Front drive inverter: a091 ESP status";
CM_ SG_ 1318 DIF_a091_ESP_party3 "Front drive inverter: a091 ESP party3";
CM_ SG_ 1318 DIF_a092_bmsStatus "Front drive inverter: a092 bms status";
CM_ SG_ 1318 DIF_a092_bmsDriveLimits "Front drive inverter: a092 bms drive limits";
CM_ SG_ 1318 DIF_a092_bmsHvBusStatus "Front drive inverter: a092 bms hv bus status";
CM_ SG_ 1318 DIF_a092_bmsPowerAvailable "Front drive inverter: a092 bms power available";
CM_ SG_ 1318 DIF_a092_bmsBmbMinMax "Front drive inverter: a092 bms bmb min max";
CM_ SG_ 1318 DIF_a092_bmsSocStatus "Front drive inverter: a092 bms soc status";
CM_ SG_ 1318 DIF_a092_bmsThermalStatus "Front drive inverter: a092 bms thermal status";
CM_ SG_ 1318 DIF_a092_bmsCtrStatus "Front drive inverter: a092 bms ctr status";
CM_ SG_ 1318 DIF_a092_bmsVoltageRegGain "Front drive inverter: a092 bms voltage reg gain";
CM_ SG_ 1318 DIF_a092_bmsPackConfig "Front drive inverter: a092 bms pack config";
CM_ SG_ 1318 DIF_a092_bmsSystemStatus "Front drive inverter: a092 bms system status";
CM_ SG_ 1318 DIF_a094_canID "Front drive inverter: a094 can ID";
CM_ SG_ 1318 DIF_a094_errorType "Front drive inverter: a094 error type";
CM_ SG_ 1318 DIF_a094_badValue1 "Front drive inverter: a094 bad value1";
CM_ SG_ 1318 DIF_a094_badValue2 "Front drive inverter: a094 bad value2";
CM_ SG_ 1318 DIF_a096_const_fast "Front drive inverter: a096 const fast";
CM_ SG_ 1318 DIF_a096_text_fast "Front drive inverter: a096 text fast";
CM_ SG_ 1318 DIF_a096_text_flash "Front drive inverter: a096 text flash";
CM_ SG_ 1318 DIF_a096_mem_data "Front drive inverter: a096 mem data";
CM_ SG_ 1318 DIF_a096_mem_regs "Front drive inverter: a096 mem regs";
CM_ SG_ 1318 DIF_a096_boot_flash "Front drive inverter: a096 boot flash";
CM_ SG_ 1318 DIF_a096_word1 "Front drive inverter: a096 word1";
CM_ SG_ 1318 DIF_a096_word2 "Front drive inverter: a096 word2";
CM_ SG_ 1318 DIF_a097_errorType "Front drive inverter: a097 error type";
CM_ SG_ 1318 DIF_a097_lineNumber "Front drive inverter: a097 line number";
CM_ SG_ 1318 DIF_a097_argument "Front drive inverter: a097 argument";
CM_ SG_ 1318 DIF_a098_pwmCount "Front drive inverter: a098 pwm count";
CM_ SG_ 1318 DIF_a098_fluxState "Front drive inverter: a098 flux state";
CM_ SG_ 1318 DIF_a103_fluidTorDeltaT "Front drive inverter: a103 fluid tor delta t";
CM_ SG_ 1318 DIF_a103_noFlowDetected "Front drive inverter: a103 no flow detected";
CM_ SG_ 1318 DIF_a103_lowFlowDetected "Front drive inverter: a103 low flow detected";
CM_ SG_ 1318 DIF_a103_fluidImplausible "Front drive inverter: a103 fluid implausible";
CM_ SG_ 1318 DIF_a103_inverterTemp "Front drive inverter: a103 inverter temp";
CM_ SG_ 1318 DIF_a103_rmsCurrent "Front drive inverter: a103 rms current";
CM_ SG_ 1318 DIF_a103_ambientTemp "Front drive inverter: a103 ambient temp";
CM_ SG_ 1318 DIF_a103_sensorTempEst "Front drive inverter: a103 sensor temp est";
CM_ SG_ 1318 DIF_a107_fpgaVersion "Front drive inverter: a107 fpga version";
CM_ SG_ 1318 DIF_a107_fpgaBootVersion "Front drive inverter: a107 fpga boot version";
CM_ SG_ 1318 DIF_a107_fpgaMasterActive "Front drive inverter: a107 fpga master active";
CM_ SG_ 1318 DIF_a107_fpgaFaultActive "Front drive inverter: a107 fpga fault active";
CM_ SG_ 1318 DIF_a107_fpgaWarningActive "Front drive inverter: a107 fpga warning active";
CM_ SG_ 1318 DIF_a108_fromState "Front drive inverter: a108 from state";
CM_ SG_ 1318 DIF_a108_toState "Front drive inverter: a108 to state";
CM_ SG_ 1318 DIF_a108_blockingAlert "Front drive inverter: a108 blocking alert";
CM_ SG_ 1318 DIF_a110_EPBL_status "Front drive inverter: a110 EPBL status";
CM_ SG_ 1318 DIF_a110_EPBR_status "Front drive inverter: a110 EPBR status";
CM_ SG_ 1318 DIF_a111_phAcalib "Front drive inverter: a111 ph acalib";
CM_ SG_ 1318 DIF_a111_phBcalib "Front drive inverter: a111 ph bcalib";
CM_ SG_ 1318 DIF_a112_phaseAcurrent "Front drive inverter: a112 phase acurrent";
CM_ SG_ 1318 DIF_a112_phaseBcurrent "Front drive inverter: a112 phase bcurrent";
CM_ SG_ 1318 DIF_a113_heatsink1Temp "Front drive inverter: a113 heatsink1 temp";
CM_ SG_ 1318 DIF_a113_heatsink2Temp "Front drive inverter: a113 heatsink2 temp";
CM_ SG_ 1318 DIF_a113_heatsink3Temp "Front drive inverter: a113 heatsink3 temp";
CM_ SG_ 1318 DIF_a115_faultAddress "Front drive inverter: a115 fault address";
CM_ SG_ 1318 DIF_a115_isWriteNotRead "Front drive inverter: a115 is write not read";
CM_ SG_ 1318 DIF_a117_torque "Front drive inverter: a117 torque";
CM_ SG_ 1318 DIF_a117_slaveCommand "Front drive inverter: a117 slave command";
CM_ SG_ 1318 DIF_a117_power "Front drive inverter: a117 power";
CM_ SG_ 1318 DIF_a117_slaveCommand2 "Front drive inverter: a117 slave command2";
CM_ SG_ 1318 DIF_a117_speed "Front drive inverter: a117 speed";
CM_ SG_ 1318 DIF_a117_chassisControl "Front drive inverter: a117 chassis control";
CM_ SG_ 1318 DIF_a117_systemStatus "Front drive inverter: a117 system status";
CM_ SG_ 1318 DIF_a117_temperature "Front drive inverter: a117 temperature";
CM_ SG_ 1318 DIF_a117_vehicle "Front drive inverter: a117 vehicle";
CM_ SG_ 1318 DIF_a117_AddTcLimit "Front drive inverter: a117 add tc limit";
CM_ SG_ 1318 DIF_a117_dixCommand "Front drive inverter: a117 dix command";
CM_ SG_ 1318 DIF_a117_odometerStatus "Front drive inverter: a117 odometer status";
CM_ SG_ 1318 DIF_a117_maxRatedPower "Front drive inverter: a117 max rated power";
CM_ SG_ 1318 DIF_a119_hvpFaults "Front drive inverter: a119 hvp faults";
CM_ SG_ 1318 DIF_a120_dcLinkInfo "Front drive inverter: a120 dc link info";
CM_ SG_ 1318 DIF_a121_badRegReason "Front drive inverter: a121 bad reg reason";
CM_ SG_ 1318 DIF_a121_torqueDelta "Front drive inverter: a121 torque delta";
CM_ SG_ 1318 DIF_a121_badCurrent "Front drive inverter: a121 bad current";
CM_ SG_ 1318 DIF_a121_badFlux "Front drive inverter: a121 bad flux";
CM_ SG_ 1318 DIF_a123_lossReason "Front drive inverter: a123 loss reason";
CM_ SG_ 1318 DIF_a123_busVoltage "Front drive inverter: a123 bus voltage";
CM_ SG_ 1318 DIF_a123_badFlux "Front drive inverter: a123 bad flux";
CM_ SG_ 1318 DIF_a123_lossRequest "Front drive inverter: a123 loss request";
CM_ SG_ 1318 DIF_a123_badCurrent "Front drive inverter: a123 bad current";
CM_ SG_ 1318 DIF_a123_motorRPM "Front drive inverter: a123 motor RPM";
CM_ SG_ 1318 DIF_a123_varianceD "Front drive inverter: a123 variance d";
CM_ SG_ 1318 DIF_a123_varianceQ "Front drive inverter: a123 variance q";
CM_ SG_ 1318 DIF_a126_limpReason "Front drive inverter: a126 limp reason";
CM_ SG_ 1318 DIF_a127_gpoReason "Front drive inverter: a127 gpo reason";
CM_ SG_ 1318 DIF_a127_temp "Front drive inverter: a127 temp";
CM_ SG_ 1318 DIF_a133_capacitorTemp "Front drive inverter: a133 capacitor temp";
CM_ SG_ 1318 DIF_a133_badValue1 "Front drive inverter: a133 bad value1";
CM_ SG_ 1318 DIF_a133_badValue2 "Front drive inverter: a133 bad value2";
CM_ SG_ 1318 DIF_a134_wheelSpeedDiffFrL "Front drive inverter: a134 wheel speed diff fr l";
CM_ SG_ 1318 DIF_a134_wheelSpeedDiffFrR "Front drive inverter: a134 wheel speed diff fr r";
CM_ SG_ 1318 DIF_a134_wheelSpeedDiffReL "Front drive inverter: a134 wheel speed diff re l";
CM_ SG_ 1318 DIF_a134_wheelSpeedDiffReR "Front drive inverter: a134 wheel speed diff re r";
CM_ SG_ 1318 DIF_a136_spiError_BL "Front drive inverter: a136 spi error BL";
CM_ SG_ 1318 DIF_a136_crcError_BL "Front drive inverter: a136 crc error BL";
CM_ SG_ 1318 DIF_a136_busyError_BL "Front drive inverter: a136 busy error BL";
CM_ SG_ 1318 DIF_a136_spiError_BH "Front drive inverter: a136 spi error BH";
CM_ SG_ 1318 DIF_a136_crcError_BH "Front drive inverter: a136 crc error BH";
CM_ SG_ 1318 DIF_a136_busyError_BH "Front drive inverter: a136 busy error BH";
CM_ SG_ 1318 DIF_a136_spiError_CL "Front drive inverter: a136 spi error CL";
CM_ SG_ 1318 DIF_a136_crcError_CL "Front drive inverter: a136 crc error CL";
CM_ SG_ 1318 DIF_a136_busyError_CL "Front drive inverter: a136 busy error CL";
CM_ SG_ 1318 DIF_a136_spiError_CH "Front drive inverter: a136 spi error CH";
CM_ SG_ 1318 DIF_a136_crcError_CH "Front drive inverter: a136 crc error CH";
CM_ SG_ 1318 DIF_a136_busyError_CH "Front drive inverter: a136 busy error CH";
CM_ SG_ 1318 DIF_a136_spiError_AL "Front drive inverter: a136 spi error AL";
CM_ SG_ 1318 DIF_a136_crcError_AL "Front drive inverter: a136 crc error AL";
CM_ SG_ 1318 DIF_a136_busyError_AL "Front drive inverter: a136 busy error AL";
CM_ SG_ 1318 DIF_a136_spiError_AH "Front drive inverter: a136 spi error AH";
CM_ SG_ 1318 DIF_a136_crcError_AH "Front drive inverter: a136 crc error AH";
CM_ SG_ 1318 DIF_a136_busyError_AH "Front drive inverter: a136 busy error AH";
CM_ SG_ 1318 DIF_a144_autopilot "Front drive inverter: a144 autopilot";
CM_ SG_ 1318 DIF_a144_chassisType "Front drive inverter: a144 chassis type";
CM_ SG_ 1318 DIF_a144_drivetrainType "Front drive inverter: a144 drivetrain type";
CM_ SG_ 1318 DIF_a144_packEnergy "Front drive inverter: a144 pack energy";
CM_ SG_ 1318 DIF_a144_packPerformanceDeviatio "Front drive inverter: a144 pack performance deviation";
CM_ SG_ 1318 DIF_a144_performancePackage "Front drive inverter: a144 performance package";
CM_ SG_ 1318 DIF_a144_vdcType "Front drive inverter: a144 vdc type";
CM_ SG_ 1318 DIF_a144_brakeHWType "Front drive inverter: a144 brake HW type";
CM_ SG_ 1318 DIF_a144_inverterHardware "Front drive inverter: a144 inverter hardware";
CM_ SG_ 1318 DIF_a144_cabinPTCHeaterType "Front drive inverter: a144 cabin PTC heater type";
CM_ SG_ 1318 DIF_a144_frunkLatchType "Front drive inverter: a144 frunk latch type";
CM_ SG_ 1318 DIF_a144_platformMaxBusVoltage "Front drive inverter: a144 platform max bus voltage";
CM_ SG_ 1318 DIF_a144_oilPump1HwType "Front drive inverter: a144 oil pump1 hw type";
CM_ SG_ 1318 DIF_a144_oilPump2HwType "Front drive inverter: a144 oil pump2 hw type";
CM_ SG_ 1318 DIF_a144_heatsinkType "Front drive inverter: a144 heatsink type";
CM_ SG_ 1318 DIF_a144_softPerformanceLimit "Front drive inverter: a144 soft performance limit";
CM_ SG_ 1318 DIF_a144_brakeActuationType "Front drive inverter: a144 brake actuation type";
CM_ SG_ 1318 DIF_a144_dasHw "Front drive inverter: a144 das hw";
CM_ SG_ 1318 DIF_a144_chassisSubType "Front drive inverter: a144 chassis sub type";
CM_ SG_ 1318 DIF_a147_overtorque1UsedCount "Front drive inverter: a147 overtorque1 used count";
CM_ SG_ 1318 DIF_a147_overtorque2UsedCount "Front drive inverter: a147 overtorque2 used count";
CM_ SG_ 1318 DIF_a147_accumulatedWear "Front drive inverter: a147 accumulated wear";
CM_ SG_ 1318 DIF_a147_wearIsValid "Front drive inverter: a147 wear is valid";
CM_ SG_ 1318 DIF_a149_flow "Front drive inverter: a149 flow";
CM_ SG_ 1318 DIF_a149_voltage "Front drive inverter: a149 voltage";
CM_ SG_ 1318 DIF_a149_temperature "Front drive inverter: a149 temperature";
CM_ SG_ 1318 DIF_a149_state "Front drive inverter: a149 state";
CM_ SG_ 1318 DIF_a149_fluidTempSNA "Front drive inverter: a149 fluid temp SNA";
CM_ SG_ 1318 DIF_a149_insufficientFlow "Front drive inverter: a149 insufficient flow";
CM_ SG_ 1318 DIF_a149_motorOpenPhase "Front drive inverter: a149 motor open phase";
CM_ SG_ 1318 DIF_a149_motorShorted "Front drive inverter: a149 motor shorted";
CM_ SG_ 1318 DIF_a149_motorFlowSNA "Front drive inverter: a149 motor flow SNA";
CM_ SG_ 1318 DIF_a149_responseError "Front drive inverter: a149 response error";
CM_ SG_ 1318 DIF_a149_pcbaID "Front drive inverter: a149 pcba ID";
CM_ SG_ 1318 DIF_a150_vBatRawMinusFiltered "Front drive inverter: a150 v bat raw minus filtered";
CM_ SG_ 1318 DIF_a150_vBatFilteredRate "Front drive inverter: a150 v bat filtered rate";
CM_ SG_ 1318 DIF_a150_elapsedMs "Front drive inverter: a150 elapsed ms";
CM_ SG_ 1318 DIF_a150_energy "Front drive inverter: a150 energy";
CM_ SG_ 1318 DIF_a152_errorType "Front drive inverter: a152 error type";
CM_ SG_ 1318 DIF_a152_frameId "Front drive inverter: a152 frame id";
CM_ SG_ 1318 DIF_a152_badValue "Front drive inverter: a152 bad value";
CM_ SG_ 1318 DIF_a152_expectedValue "Front drive inverter: a152 expected value";
CM_ SG_ 1318 DIF_a153_oilFlow "Front drive inverter: a153 oil flow";
CM_ SG_ 1318 DIF_a153_oilTemperature "Front drive inverter: a153 oil temperature";
CM_ SG_ 1318 DIF_a153_phaseCurrent "Front drive inverter: a153 phase current";
CM_ SG_ 1318 DIF_a153_dcVoltage "Front drive inverter: a153 dc voltage";
CM_ SG_ 1318 DIF_a153_lowPressPlausibility "Front drive inverter: a153 low press plausibility";
CM_ SG_ 1318 DIF_a153_state "Front drive inverter: a153 state";
CM_ SG_ 1318 DIF_a153_oilPumpAlert "Front drive inverter: a153 oil pump alert";
CM_ SG_ 1318 DIF_a153_reason "Front drive inverter: a153 reason";
CM_ SG_ 1318 DIF_a154_motorRPM "Front drive inverter: a154 motor RPM";
CM_ SG_ 1318 DIF_a154_phaseError "Front drive inverter: a154 phase error";
CM_ SG_ 1318 DIF_a154_commonGain "Front drive inverter: a154 common gain";
CM_ SG_ 1318 DIF_a154_noCalibration "Front drive inverter: a154 no calibration";
CM_ SG_ 1318 DIF_a154_noPhaseLock "Front drive inverter: a154 no phase lock";
CM_ SG_ 1318 DIF_a154_noCarrier "Front drive inverter: a154 no carrier";
CM_ SG_ 1318 DIF_a154_notReady "Front drive inverter: a154 not ready";
CM_ SG_ 1318 DIF_a154_errorTableInvalid "Front drive inverter: a154 error table invalid";
CM_ SG_ 1318 DIF_a154_carrierOffset "Front drive inverter: a154 carrier offset";
CM_ SG_ 1318 DIF_a154_trackerIrrational "Front drive inverter: a154 tracker irrational";
CM_ SG_ 1318 DIF_a154_claMIA "Front drive inverter: a154 cla MIA";
CM_ SG_ 1318 DIF_a155_sensors "Front drive inverter: a155 sensors";
CM_ SG_ 1318 DIF_a155_coolant "Front drive inverter: a155 coolant";
CM_ SG_ 1318 DIF_a155_LVPowerState "Front drive inverter: a155 LV power state";
CM_ SG_ 1318 DIF_a155_vehicleStatus "Front drive inverter: a155 vehicle status";
CM_ SG_ 1318 DIF_a155_status "Front drive inverter: a155 status";
CM_ SG_ 1318 DIF_a155_leftDoorStatus "Front drive inverter: a155 left door status";
CM_ SG_ 1318 DIF_a155_rightDoorStatus "Front drive inverter: a155 right door status";
CM_ SG_ 1318 DIF_a155_vcleftSwitchStatus "Front drive inverter: a155 vcleft switch status";
CM_ SG_ 1318 DIF_a155_restraintStatus "Front drive inverter: a155 restraint status";
CM_ SG_ 1318 DIF_a155_systemStatus "Front drive inverter: a155 system status";
CM_ SG_ 1318 DIF_a155_prndStatus "Front drive inverter: a155 prnd status";
CM_ SG_ 1318 DIF_a155_liftgateStatus "Front drive inverter: a155 liftgate status";
CM_ SG_ 1318 DIF_a157_RCM_inertial1 "Front drive inverter: a157 RCM inertial1";
CM_ SG_ 1318 DIF_a157_RCM_inertial2 "Front drive inverter: a157 RCM inertial2";
CM_ SG_ 1318 DIF_a158_IBST_party1 "Front drive inverter: a158 IBST party1";
CM_ SG_ 1318 DIF_a158_BUS1_IBST_status "Front drive inverter: a158 BUS1 IBST status";
CM_ SG_ 1318 DIF_a158_BUS2_IBST_status "Front drive inverter: a158 BUS2 IBST status";
CM_ SG_ 1318 DIF_a160_vBatRawMinusFiltered "Front drive inverter: a160 v bat raw minus filtered";
CM_ SG_ 1318 DIF_a160_vBatFilteredRate "Front drive inverter: a160 v bat filtered rate";
CM_ SG_ 1318 DIF_a160_elapsedMs "Front drive inverter: a160 elapsed ms";
CM_ SG_ 1318 DIF_a160_energy "Front drive inverter: a160 energy";
CM_ SG_ 1318 DIF_a161_EPAS3P_sysStatus "Front drive inverter: a161 EPAS3 p sys status";
CM_ SG_ 1318 DIF_a161_EPAS3P_angleCalib "Front drive inverter: a161 EPAS3 p angle calib";
CM_ SG_ 1318 DIF_a202_reason "Front drive inverter: a202 reason";
CM_ SG_ 1318 DIF_a202_movement "Front drive inverter: a202 movement";
CM_ SG_ 1318 DIF_a202_sysStateExitCondition "Front drive inverter: a202 sys state exit condition";
CM_ SG_ 1318 DIF_a233_missedMsgCount "Front drive inverter: a233 missed msg count";
CM_ SG_ 1318 DIF_a233_serviceModeActive "Signal reported by Front drive inverter";
CM_ SG_ 1318 DIF_a234_PCS_dcdcStatus "Front drive inverter: a234 PCS dcdc status";
CM_ SG_ 1318 DIF_a236_states "Front drive inverter: a236 states";
CM_ SG_ 1318 DIF_a242_RotorOffset "Front drive inverter: a242 rotor offset";
CM_ SG_ 1318 DIF_a242_RotorFlux "Front drive inverter: a242 rotor flux";
CM_ SG_ 1318 DIF_a242_ResolverError "Front drive inverter: a242 resolver error";
CM_ SG_ 1318 DIF_a244_desatHighSide "Front drive inverter: a244 desat high side";
CM_ SG_ 1318 DIF_a244_desatLowSide "Front drive inverter: a244 desat low side";
CM_ SG_ 1318 DIF_a244_singleSwitchShort "Front drive inverter: a244 single switch short";
CM_ SG_ 1318 DIF_a244_flybackFault "Front drive inverter: a244 flyback fault";
CM_ SG_ 1318 DIF_a244_postShortTestFailed "Front drive inverter: a244 post short test failed";
CM_ SG_ 1318 DIF_a244_udsSelfTest "Front drive inverter: a244 uds self test";
CM_ SG_ 1318 DIF_a244_irSensorV "Front drive inverter: a244 ir sensor v";
CM_ SG_ 1318 DIF_a244_gateDriveICUndervoltage "Front drive inverter: a244 gate drive IC undervoltage";
CM_ SG_ 1318 DIF_a244_plausibleSingleSwitchSh "Front drive inverter: a244 plausible single switch short only";
CM_ SG_ 1318 DIF_a246_atSpeedDIResetCount "Front drive inverter: a246 at speed DI reset count";
CM_ SG_ 1318 DIF_a246_didPMCauseASC "Front drive inverter: a246 did PM cause ASC";
CM_ SG_ 1318 DIF_a246_currentSensorRational "Front drive inverter: a246 current sensor rational";
CM_ SG_ 1318 DIF_a246_observerDetectedLS3PS "Front drive inverter: a246 observer detected LS3 PS";
CM_ SG_ 1318 DIF_a246_hvIsGood "Front drive inverter: a246 hv is good";
CM_ SG_ 1318 DIF_a246_lvIsGood "Front drive inverter: a246 lv is good";
CM_ SG_ 1318 DIF_a246_codeBranch "Front drive inverter: a246 code branch";
CM_ SG_ 1318 DIF_a246_motorRPM "Front drive inverter: a246 motor RPM";
CM_ SG_ 1318 DIF_a246_eepromOffsetIa "Front drive inverter: a246 eeprom offset ia";
CM_ SG_ 1318 DIF_a246_eepromOffsetIb "Front drive inverter: a246 eeprom offset ib";
CM_ SG_ 1318 DIF_a247_rotorOffsetEst "Front drive inverter: a247 rotor offset est";
CM_ SG_ 1318 DIF_a247_motorRPM "Front drive inverter: a247 motor RPM";
CM_ SG_ 1318 DIF_a247_torqueMotor "Front drive inverter: a247 torque motor";
CM_ SG_ 1318 DIF_a251_oilFlow "Front drive inverter: a251 oil flow";
CM_ SG_ 1318 DIF_a251_oilTemperature "Front drive inverter: a251 oil temperature";
CM_ SG_ 1318 DIF_a251_dcVoltage "Front drive inverter: a251 dc voltage";
CM_ SG_ 1318 DIF_a251_dcCurrent "Front drive inverter: a251 dc current";
CM_ SG_ 1318 DIF_a251_phaseCurrent "Front drive inverter: a251 phase current";
CM_ SG_ 1318 DIF_a251_leadAngle "Front drive inverter: a251 lead angle";
CM_ SG_ 1318 DIF_a251_reason "Front drive inverter: a251 reason";
CM_ BO_ 854 "Front drive inverter message: alert matrix1";
CM_ SG_ 854 DIF_a001_hwPhaseAgateDrive "Front drive inverter: a001 hw phase agate drive";
CM_ SG_ 854 DIF_a002_hwPhaseBgateDrive "Front drive inverter: a002 hw phase bgate drive";
CM_ SG_ 854 DIF_a003_hwPhaseCgateDrive "Front drive inverter: a003 hw phase cgate drive";
CM_ SG_ 854 DIF_a004_hwPhaseApeak "Front drive inverter: a004 hw phase apeak";
CM_ SG_ 854 DIF_a005_hwPhaseBpeak "Front drive inverter: a005 hw phase bpeak";
CM_ SG_ 854 DIF_a006_hwPhaseCpeak "Front drive inverter: a006 hw phase cpeak";
CM_ SG_ 854 DIF_a007_statorAnomalyDetected "Front drive inverter: a007 stator anomaly detected";
CM_ SG_ 854 DIF_a008_hwEncoderA "Front drive inverter: a008 hw encoder a";
CM_ SG_ 854 DIF_a009_hwEncoderB "Front drive inverter: a009 hw encoder b";
CM_ SG_ 854 DIF_a010_unintendedReset "Front drive inverter: a010 unintended reset";
CM_ SG_ 854 DIF_a011_swPowerStageNotReady "Front drive inverter: a011 sw power stage not ready";
CM_ SG_ 854 DIF_a012_hvilNotClosed "Front drive inverter: a012 hvil not closed";
CM_ SG_ 854 DIF_a013_eccError "Front drive inverter: a013 ecc error";
CM_ SG_ 854 DIF_a014_activeDamping "Front drive inverter: a014 active damping";
CM_ SG_ 854 DIF_a015_mechSafeStateAnomaly "Front drive inverter: a015 mech safe state anomaly";
CM_ SG_ 854 DIF_a016_safeStateApplied "Front drive inverter: a016 safe state applied";
CM_ SG_ 854 DIF_a017_hwPedalMonitor "Front drive inverter: a017 hw pedal monitor";
CM_ SG_ 854 DIF_a018_hwLVSupplyUV "Front drive inverter: a018 hw LV supply UV";
CM_ SG_ 854 DIF_a020_hwMotorEncoder "Front drive inverter: a020 hw motor encoder";
CM_ SG_ 854 DIF_a021_hwBusOV "Front drive inverter: a021 hw bus OV";
CM_ SG_ 854 DIF_a022_hw5vSupplyUV "Front drive inverter: a022 hw5v supply UV";
CM_ SG_ 854 DIF_a024_selfTest "Front drive inverter: a024 self test";
CM_ SG_ 854 DIF_a025_phaseApeak "Front drive inverter: a025 phase apeak";
CM_ SG_ 854 DIF_a026_phaseBpeak "Front drive inverter: a026 phase bpeak";
CM_ SG_ 854 DIF_a027_phaseCpeak "Front drive inverter: a027 phase cpeak";
CM_ SG_ 854 DIF_a028_phaseArms "Front drive inverter: a028 phase arms";
CM_ SG_ 854 DIF_a029_phaseBrms "Front drive inverter: a029 phase brms";
CM_ SG_ 854 DIF_a030_phaseCrms "Front drive inverter: a030 phase crms";
CM_ SG_ 854 DIF_a031_phaseAcurrentOffset "Front drive inverter: a031 phase acurrent offset";
CM_ SG_ 854 DIF_a032_phaseBcurrentOffset "Front drive inverter: a032 phase bcurrent offset";
CM_ SG_ 854 DIF_a033_phaseAcurrentSensor "Front drive inverter: a033 phase acurrent sensor";
CM_ SG_ 854 DIF_a034_phaseBcurrentSensor "Front drive inverter: a034 phase bcurrent sensor";
CM_ SG_ 854 DIF_a035_phaseCurrentBalance "Front drive inverter: a035 phase current balance";
CM_ SG_ 854 DIF_a036_busOV "Front drive inverter: a036 bus OV";
CM_ SG_ 854 DIF_a037_busUV "Front drive inverter: a037 bus UV";
CM_ SG_ 854 DIF_a038_busVsensor "Front drive inverter: a038 bus vsensor";
CM_ SG_ 854 DIF_a039_exceptionUndefinedInstr "Front drive inverter: a039 exception undefined instruction";
CM_ SG_ 854 DIF_a040_difMIA "Front drive inverter: a040 dif MIA";
CM_ SG_ 854 DIF_a041_sdcMIA "Front drive inverter: a041 sdc MIA";
CM_ SG_ 854 DIF_a042_inletSensor "Front drive inverter: a042 inlet sensor";
CM_ SG_ 854 DIF_a043_outletOT "Front drive inverter: a043 outlet OT";
CM_ SG_ 854 DIF_a044_outletUT "Front drive inverter: a044 outlet UT";
CM_ SG_ 854 DIF_a045_outletSensor "Front drive inverter: a045 outlet sensor";
CM_ SG_ 854 DIF_a046_statorOT "Front drive inverter: a046 stator OT";
CM_ SG_ 854 DIF_a047_statorSensor1 "Front drive inverter: a047 stator sensor1";
CM_ SG_ 854 DIF_a048_statorSensor2 "Front drive inverter: a048 stator sensor2";
CM_ SG_ 854 DIF_a049_statorSensorDiff "Front drive inverter: a049 stator sensor diff";
CM_ SG_ 854 DIF_a050_noStatorSensor "Front drive inverter: a050 no stator sensor";
CM_ SG_ 854 DIF_a052_dirMIA "Front drive inverter: a052 dir MIA";
CM_ SG_ 854 DIF_a053_unexpectedLatchState "Front drive inverter: a053 unexpected latch state";
CM_ SG_ 854 DIF_a054_driveInverterOT "Front drive inverter: a054 drive inverter OT";
CM_ SG_ 854 DIF_a055_trqCrossCheck "Front drive inverter: a055 trq cross check";
CM_ SG_ 854 DIF_a056_ambientOT "Front drive inverter: a056 ambient OT";
CM_ SG_ 854 DIF_a057_ambientUT "Front drive inverter: a057 ambient UT";
CM_ SG_ 854 DIF_a058_ambientSensor "Front drive inverter: a058 ambient sensor";
CM_ SG_ 854 DIF_a059_heatsinkOT "Front drive inverter: a059 heatsink OT";
CM_ SG_ 854 DIF_a060_heatsinkUT "Front drive inverter: a060 heatsink UT";
CM_ SG_ 854 DIF_a061_heatsinkSensor "Front drive inverter: a061 heatsink sensor";
CM_ SG_ 854 DIF_a062_systemLimpMode "Front drive inverter: a062 system limp mode";
CM_ SG_ 854 DIF_a063_bbMIA "Front drive inverter: a063 bb MIA";
CM_ SG_ 854 DIF_a064_torqueIntervention "Front drive inverter: a064 torque intervention";
CM_ BO_ 855 "Front drive inverter message: alert matrix2";
CM_ SG_ 855 DIF_a065_canHardwareBusB "Front drive inverter: a065 can hardware bus b";
CM_ SG_ 855 DIF_a066_canDataBusB "Front drive inverter: a066 can data bus b";
CM_ SG_ 855 DIF_a067_canOverrunBusB "Front drive inverter: a067 can overrun bus b";
CM_ SG_ 855 DIF_a069_rotorTempLimit "Front drive inverter: a069 rotor temp limit";
CM_ SG_ 855 DIF_a070_udsTransactionInitiated "Front drive inverter: a070 uds transaction initiated";
CM_ SG_ 855 DIF_a071_busDisconnected "Front drive inverter: a071 bus disconnected";
CM_ SG_ 855 DIF_a072_gateDriveFaultCounter "Front drive inverter: a072 gate drive fault counter";
CM_ SG_ 855 DIF_a073_motorSpeed "Front drive inverter: a073 motor speed";
CM_ SG_ 855 DIF_a074_motorEncoder "Front drive inverter: a074 motor encoder";
CM_ SG_ 855 DIF_a075_motorSpeedMismatch "Front drive inverter: a075 motor speed mismatch";
CM_ SG_ 855 DIF_a076_lvSupplyOV "Front drive inverter: a076 lv supply OV";
CM_ SG_ 855 DIF_a077_lvSupplyUV "Front drive inverter: a077 lv supply UV";
CM_ SG_ 855 DIF_a078_adcRefLow "Front drive inverter: a078 adc ref low";
CM_ SG_ 855 DIF_a079_adcRefHigh "Front drive inverter: a079 adc ref high";
CM_ SG_ 855 DIF_a081_P0BFF_DIF_EM_CurrentHig "Front drive inverter: a081 P0 BFF DIF EM current high";
CM_ SG_ 855 DIF_a082_P7837_DIF_ECU_DemoTimer "Front drive inverter: a082 P7837 DIF ECU demo timer";
CM_ SG_ 855 DIF_a083_PABCD_DIF_ECU_DemoWindo "Front drive inverter: a083 PABCD DIF ECU demo window";
CM_ SG_ 855 DIF_a084_eccTestData0 "Front drive inverter: a084 ecc test data0";
CM_ SG_ 855 DIF_a086_activeDischargeOn "Front drive inverter: a086 active discharge on";
CM_ SG_ 855 DIF_a087_gtwMIA "Front drive inverter: a087 gtw MIA";
CM_ SG_ 855 DIF_a088_uiMIA "Front drive inverter: a088 ui MIA";
CM_ SG_ 855 DIF_a090_pmMIA "Front drive inverter: a090 pm MIA";
CM_ SG_ 855 DIF_a091_espMIA "Front drive inverter: a091 esp MIA";
CM_ SG_ 855 DIF_a092_bmsMIA "Front drive inverter: a092 bms MIA";
CM_ SG_ 855 DIF_a093_canHardwareBusA "Front drive inverter: a093 can hardware bus a";
CM_ SG_ 855 DIF_a094_canDataBusA "Front drive inverter: a094 can data bus a";
CM_ SG_ 855 DIF_a095_canOverrunBusA "Front drive inverter: a095 can overrun bus a";
CM_ SG_ 855 DIF_a096_memoryError "Front drive inverter: a096 memory error";
CM_ SG_ 855 DIF_a097_eepromError "Front drive inverter: a097 eeprom error";
CM_ SG_ 855 DIF_a098_intTimeTooLong "Front drive inverter: a098 int time too long";
CM_ SG_ 855 DIF_a099_threadOverrun "Front drive inverter: a099 thread overrun";
CM_ SG_ 855 DIF_a100_assertion "Front drive inverter: a100 assertion";
CM_ SG_ 855 DIF_a101_eccTestData1 "Front drive inverter: a101 ecc test data1";
CM_ SG_ 855 DIF_a102_exceptionPrefetchAbort "Front drive inverter: a102 exception prefetch abort";
CM_ SG_ 855 DIF_a103_lowFlow "Front drive inverter: a103 low flow";
CM_ SG_ 855 DIF_a107_fpgaError "Front drive inverter: a107 fpga error";
CM_ SG_ 855 DIF_a108_stateTrans "Front drive inverter: a108 state trans";
CM_ SG_ 855 DIF_a109_ahbWriteError "Front drive inverter: a109 ahb write error";
CM_ SG_ 855 DIF_a110_brakeMIA "Front drive inverter: a110 brake MIA";
CM_ SG_ 855 DIF_a111_badPhaseSensorCalib "Front drive inverter: a111 bad phase sensor calib";
CM_ SG_ 855 DIF_a112_noPhaseCurrent "Front drive inverter: a112 no phase current";
CM_ SG_ 855 DIF_a113_noFuncHeatsinkSensor "Front drive inverter: a113 no func heatsink sensor";
CM_ SG_ 855 DIF_a114_exceptionDataAbort "Front drive inverter: a114 exception data abort";
CM_ SG_ 855 DIF_a115_exceptionDataAbort2 "Front drive inverter: a115 exception data abort2";
CM_ SG_ 855 DIF_a116_highSpeedWearCounter "Front drive inverter: a116 high speed wear counter";
CM_ SG_ 855 DIF_a117_diMIA "Front drive inverter: a117 di MIA";
CM_ SG_ 855 DIF_a119_hvpMIA "Front drive inverter: a119 hvp MIA";
CM_ SG_ 855 DIF_a120_hvlinkMIA "Front drive inverter: a120 hvlink MIA";
CM_ SG_ 855 DIF_a121_motorControlRegulation "Front drive inverter: a121 motor control regulation";
CM_ SG_ 855 DIF_a122_highStackUsage "Front drive inverter: a122 high stack usage";
CM_ SG_ 855 DIF_a123_lossMotorControl "Front drive inverter: a123 loss motor control";
CM_ SG_ 855 DIF_a126_limpMode "Front drive inverter: a126 limp mode";
CM_ SG_ 855 DIF_a127_gracefulPowerOff "Front drive inverter: a127 graceful power off";
CM_ SG_ 855 DIF_a128_fpgaVersionMismatch "Front drive inverter: a128 fpga version mismatch";
CM_ BO_ 858 "Front drive inverter message: alert matrix3";
CM_ SG_ 858 DIF_a133_capacitorOT "Front drive inverter: a133 capacitor OT";
CM_ SG_ 858 DIF_a134_wheelSpeedIrrational "Front drive inverter: a134 wheel speed irrational";
CM_ SG_ 858 DIF_a136_spiError "Front drive inverter: a136 spi error";
CM_ SG_ 858 DIF_a142_highLashAngle "Front drive inverter: a142 high lash angle";
CM_ SG_ 858 DIF_a144_configMismatch "Front drive inverter: a144 config mismatch";
CM_ SG_ 858 DIF_a147_highTorqueWearLimit "Front drive inverter: a147 high torque wear limit";
CM_ SG_ 858 DIF_a148_burnInCycleEnded "Front drive inverter: a148 burn in cycle ended";
CM_ SG_ 858 DIF_a149_oilPumpFailure "Front drive inverter: a149 oil pump failure";
CM_ SG_ 858 DIF_a150_busVD "Front drive inverter: a150 bus VD";
CM_ SG_ 858 DIF_a151_shockTorqueLimiter "Front drive inverter: a151 shock torque limiter";
CM_ SG_ 858 DIF_a152_linError "Front drive inverter: a152 lin error";
CM_ SG_ 858 DIF_a153_oilPumpDiagnostics "Front drive inverter: a153 oil pump diagnostics";
CM_ SG_ 858 DIF_a154_resolver "Front drive inverter: a154 resolver";
CM_ SG_ 858 DIF_a155_vcfrontMIA "Front drive inverter: a155 vcfront MIA";
CM_ SG_ 858 DIF_a156_currentObserver "Front drive inverter: a156 current observer";
CM_ SG_ 858 DIF_a157_rcmMIA "Front drive inverter: a157 rcm MIA";
CM_ SG_ 858 DIF_a158_ibstMIA "Front drive inverter: a158 ibst MIA";
CM_ SG_ 858 DIF_a160_busVoltageAnomaly "Front drive inverter: a160 bus voltage anomaly";
CM_ SG_ 858 DIF_a161_epas3pMIA "Front drive inverter: a161 epas3p MIA";
CM_ SG_ 858 DIF_a162_endOfLifetimeBurnIn "Front drive inverter: a162 end of lifetime burn in";
CM_ SG_ 858 DIF_a174_unitMayNotRestart "Front drive inverter: a174 unit may not restart";
CM_ SG_ 858 DIF_a176_safetyICFault "Front drive inverter: a176 safety IC fault";
CM_ SG_ 858 DIF_a177_fluxReferenceCorrected "Front drive inverter: a177 flux reference corrected";
CM_ BO_ 859 "Front drive inverter message: alert matrix4";
CM_ SG_ 859 DIF_a202_excessHeatUnavailable "Front drive inverter: a202 excess heat unavailable";
CM_ SG_ 859 DIF_a225_tmpEstPlausibility "Front drive inverter: a225 tmp est plausibility";
CM_ SG_ 859 DIF_a231_unintendedReset2 "Front drive inverter: a231 unintended reset2";
CM_ SG_ 859 DIF_a233_diMsgMissed "Front drive inverter: a233 di msg missed";
CM_ SG_ 859 DIF_a234_pcsMIA "Front drive inverter: a234 pcs MIA";
CM_ SG_ 859 DIF_a236_tasMIA "Front drive inverter: a236 tas MIA";
CM_ SG_ 859 DIF_a241_systemThermallyLimited "Front drive inverter: a241 system thermally limited";
CM_ SG_ 859 DIF_a242_spinDownLearning "Front drive inverter: a242 spin down learning";
CM_ SG_ 859 DIF_a243_ecuLogAvailable "Front drive inverter: a243 ecu log available";
CM_ SG_ 859 DIF_a244_mechSafeStateApplied "Front drive inverter: a244 mech safe state applied";
CM_ SG_ 859 DIF_a245_mechSafeStatePreWarn "Front drive inverter: a245 mech safe state pre warn";
CM_ SG_ 859 DIF_a246_recoveryAtSpeedError "Front drive inverter: a246 recovery at speed error";
CM_ SG_ 859 DIF_a247_rotorOffsetError "Front drive inverter: a247 rotor offset error";
CM_ SG_ 859 DIF_a249_highStatorTempFromResis "Front drive inverter: a249 high stator temp from resist";
CM_ SG_ 859 DIF_a250_preregulatorRail "Front drive inverter: a250 preregulator rail";
CM_ SG_ 859 DIF_a251_oilPumpService "Front drive inverter: a251 oil pump service";
CM_ SG_ 859 DIF_a252_currentCoreFallback "Front drive inverter: a252 current core fallback";
CM_ SG_ 859 DIF_a253_lvBoostedRail "Front drive inverter: a253 lv boosted rail";
CM_ SG_ 859 DIF_a254_activeDischargeRail "Front drive inverter: a254 active discharge rail";
CM_ SG_ 859 DIF_a255_currentGainFallback "Front drive inverter: a255 current gain fallback";
CM_ BO_ 1879 "Front drive inverter message: debug";
CM_ SG_ 1879 DIF_debugSelector "Front drive inverter: debug selector";
CM_ SG_ 1879 DIF_phaseOutBusbarTemp "Front drive inverter: phase out busbar temp";
CM_ SG_ 1879 DIF_phaseOutBusbarWeldTemp "Front drive inverter: phase out busbar weld temp";
CM_ SG_ 1879 DIF_phaseOutLugTemp "Front drive inverter: phase out lug temp";
CM_ SG_ 1879 DIF_dcLinkCapTemp "Front drive inverter: dc link cap temp";
CM_ SG_ 1879 DIF_hvDcCableTemp "Front drive inverter: hv dc cable temp";
CM_ SG_ 1879 DIF_negDcBusbarTemp "Front drive inverter: neg dc busbar temp";
CM_ SG_ 1879 DIF_posDcBusbarTemp "Front drive inverter: pos dc busbar temp";
CM_ SG_ 1879 DIF_statorEndWindingTemp "Front drive inverter: stator end winding temp";
CM_ SG_ 1879 DIF_rotorMaxMagnetTemp "Reports the maximum temperature of the rotor magnet.";
CM_ SG_ 1879 DIF_lightSenseV "Front drive inverter: light sense v";
CM_ SG_ 1879 DIF_pyroSenseV "Front drive inverter: pyro sense v";
CM_ SG_ 1879 DIF_statorSlotWindingTemp "Front drive inverter: stator slot winding temp";
CM_ SG_ 1879 DIF_intervalMaxHvBusV "Front drive inverter: interval max hv bus v";
CM_ BO_ 634 "Front drive inverter message: hv status";
CM_ SG_ 634 DIF_hvStatusChecksum "Front drive inverter: hv status checksum";
CM_ SG_ 634 DIF_hvStatusCounter "Front drive inverter: hv status counter";
CM_ SG_ 634 DIF_hvilCurrent "HVIL Current";
CM_ SG_ 634 DIF_hvilCmVoltage "HVIL Common Mode Voltage";
CM_ SG_ 634 DIF_hvilStatus "Aggregated hardware and measured HVIL unit status";
CM_ SG_ 634 DIF_hvilSupplyState "Front drive inverter: hvil supply state";
CM_ SG_ 634 DIF_activeDischargeCtrl "Front drive inverter: active discharge ctrl";
CM_ SG_ 634 DIF_activeDischargeStatus "Active discharge status from HVIL_FAULT signal.";
CM_ SG_ 634 DIF_vBat "Reports the battery voltage measured by the Drive Inverter's local Analog to Digital Converter (ADC).";
CM_ SG_ 634 DIF_vBatQF "Front drive inverter: v bat QF";
CM_ SG_ 634 DIF_powerStageSafeState "Front drive inverter: power stage safe state";
CM_ SG_ 634 DIF_fluxState "Front drive inverter: flux state";
CM_ SG_ 634 DIF_vBusDiag "Front drive inverter: v bus diag";
CM_ SG_ 634 DIF_gateDriveState "Front drive inverter: gate drive state";
CM_ BO_ 1622 "Front drive inverter message: info";
CM_ SG_ 1622 DIF_infoIndex "Front drive inverter: info index";
CM_ SG_ 1622 DIF_buildType "Front drive inverter: build type";
CM_ SG_ 1622 DIF_buildConfigurationId "Front drive inverter: build configuration id";
CM_ SG_ 1622 DIF_hardwareId "Front drive inverter: hardware id";
CM_ SG_ 1622 DIF_componentId "Front drive inverter: component id";
CM_ SG_ 1622 DIF_pcbaId "Front drive inverter: pcba id";
CM_ SG_ 1622 DIF_assemblyId "Front drive inverter: assembly id";
CM_ SG_ 1622 DIF_usageId "Front drive inverter: usage id";
CM_ SG_ 1622 DIF_subUsageId "Front drive inverter: sub usage id";
CM_ SG_ 1622 DIF_motorType "Front drive inverter: motor type";
CM_ SG_ 1622 DIF_siliconType "Front drive inverter: silicon type";
CM_ SG_ 1622 DIF_mechSafeStateType "Front drive inverter: mech safe state type";
CM_ SG_ 1622 DIF_applicationCrc "Front drive inverter: application crc";
CM_ SG_ 1622 DIF_oilPumpBuildType "Front drive inverter: oil pump build type";
CM_ SG_ 1622 DIF_oilPumpAppCrc "Front drive inverter: oil pump app crc";
CM_ SG_ 1622 DIF_FPGA_version "Front drive inverter: FPGA version";
CM_ SG_ 1622 DIF_appGitHash "Front drive inverter: app git hash";
CM_ SG_ 1622 DIF_bootGitHash "Front drive inverter: boot git hash";
CM_ SG_ 1622 DIF_platformTyp "Front drive inverter: platform typ";
CM_ SG_ 1622 DIF_infoBootLdUdsProtocolVersion "Front drive inverter: info boot ld uds protocol version";
CM_ SG_ 1622 DIF_bootloaderCrc "Front drive inverter: bootloader crc";
CM_ SG_ 1622 DIF_oilPumpPcbaId "Front drive inverter: oil pump pcba id";
CM_ SG_ 1622 DIF_oilPumpAssemblyId "Front drive inverter: oil pump assembly id";
CM_ SG_ 1622 DIF_oilPumpUsageId "Front drive inverter: oil pump usage id";
CM_ SG_ 1622 DIF_refRotorFlux "Front drive inverter: ref rotor flux";
CM_ SG_ 1622 DIF_refRotorOffset "Front drive inverter: ref rotor offset";
CM_ SG_ 1622 DIF_speedWearTotal "Front drive inverter: speed wear total";
CM_ SG_ 1622 DIF_torqueWearTotal "Front drive inverter: torque wear total";
CM_ BO_ 421 "Front drive inverter message: motor status";
CM_ SG_ 421 DIF_motorCurrent "Drive Inverer measured motor RMS phase current.";
CM_ SG_ 421 DIF_switchingFrequency "Front drive inverter: switching frequency";
CM_ SG_ 421 DIF_targetFluxMode "Front drive inverter: target flux mode";
CM_ SG_ 421 DIF_switchShortTestRetryCount "Front drive inverter: switch short test retry count";
CM_ BO_ 918 "Front drive inverter message: oil pump";
CM_ SG_ 918 DIF_oilPumpState "Reports the state of the oil pump.";
CM_ SG_ 918 DIF_oilPumpFluidTQF "Front drive inverter: oil pump fluid TQF";
CM_ SG_ 918 DIF_oilPumpLeadAngle "Front drive inverter: oil pump lead angle";
CM_ SG_ 918 DIF_oilPumpFlowTarget "Detects oil pump flow target.";
CM_ SG_ 918 DIF_oilPumpFlowActual "Detects oil pump flow.";
CM_ SG_ 918 DIF_oilPumpFluidT "Detects oil pump fluid tester.";
CM_ SG_ 918 DIF_oilPumpPhaseCurrent "Front drive inverter: oil pump phase current";
CM_ SG_ 918 DIF_oilPumpPressureEstimate "Oil pump pressure estimate.";
CM_ SG_ 918 DIF_oilPumpPressureExpected "Oil pump pressure expected.";
CM_ SG_ 918 DIF_oilPumpPressureResidual "Oil pressure error outside of allowed tolerance";
CM_ BO_ 741 "Front drive inverter message: power";
CM_ SG_ 741 DIF_elecPower "Front drive inverter: elec power";
CM_ SG_ 741 DIF_heatPowerOptimal "Front drive inverter: heat power optimal";
CM_ SG_ 741 DIF_heatPowerMax "Drive Inverter maximum heat power capability";
CM_ SG_ 741 DIF_heatPowerActual "Drive Inverter heat power";
CM_ SG_ 741 DIF_excessHeatCommand "Drive Inverter excess heat command";
CM_ SG_ 741 DIF_drivePowerMax "Front drive inverter: drive power max";
CM_ BO_ 725 "Front drive inverter message: status";
CM_ SG_ 725 DIF_statusChecksum "Front drive inverter: status checksum";
CM_ SG_ 725 DIF_statusCounter "Front drive inverter: status counter";
CM_ SG_ 725 DIF_state "DI unit state machine state.";
CM_ SG_ 725 DIF_keepAliveRequest "Used to detect that the Drive Inverter (DI) expects 12V and High Voltage (HV) to be kept up in order to protect hardware.";
CM_ SG_ 725 DIF_soptState "Detects the state of the the Switch Off Path Test (SOPT).";
CM_ SG_ 725 DIF_sysLimpRequest "Front drive inverter: sys limp request";
CM_ SG_ 725 DIF_adState "Front drive inverter: ad state";
CM_ SG_ 725 DIF_driveModeState "Reports the system drive mode state.";
CM_ SG_ 725 DIF_lvSupplyV "Front drive inverter: lv supply v";
CM_ SG_ 725 DIF_wasteState "Reports the Drive Inverter (DI) waste heat state.";
CM_ SG_ 725 DIF_haltRequest "Front drive inverter: halt request";
CM_ SG_ 725 DIF_axleSpeedLimitRequest "Front drive inverter: axle speed limit request";
CM_ SG_ 725 DIF_adDirection "Front drive inverter: ad direction";
CM_ SG_ 725 DIF_spinDownLearningState "Front drive inverter: spin down learning state";
CM_ SG_ 725 DIF_spinDownLearningMode "Front drive inverter: spin down learning mode";
CM_ SG_ 725 DIF_unitRecoveredFromResetAtSpee "Front drive inverter: unit recovered from reset at speed";
BA_DEF_ BO_ "GenMsgCycleTime" INT 0 3600000;
BA_DEF_ BO_ "GenMsgSendType" ENUM "Cyclic","NotUsed","NotUsed","NotUsed","NotUsed","NotUsed","NotUsed","IfActive","NoMsgSendType","NotUsed";
BA_DEF_ BO_ "VFrameFormat" ENUM "StandardCAN","ExtendedCAN","reserved","J1939PG","reserved","reserved","reserved","reserved","reserved","reserved","reserved","reserved","reserved","reserved","StandardCAN_FD","ExtendedCAN_FD";
BA_DEF_ BO_ "CANFD_BRS" ENUM "0","1";
BA_DEF_ SG_ "SystemSignalLongSymbol" STRING;
BA_DEF_ SG_ "Confidence" ENUM "layout-only","plausible","validated";
BA_DEF_DEF_ "GenMsgCycleTime" 0;
BA_DEF_DEF_ "GenMsgSendType" "NoMsgSendType";
BA_DEF_DEF_ "VFrameFormat" "StandardCAN";
BA_DEF_DEF_ "CANFD_BRS" "1";
BA_DEF_DEF_ "SystemSignalLongSymbol" "";
BA_DEF_DEF_ "Confidence" "layout-only";
BA_ "Confidence" SG_ 299 DAS_smartShiftTorqueDirection 1;
BA_ "Confidence" SG_ 299 DAS_smartShiftTorqueReason 1;
BA_ "Confidence" SG_ 299 DAS_autoshiftTorqueDirectionDbg 1;
BA_ "Confidence" SG_ 299 DAS_autoshiftUpcomingDirection 1;
BA_ "Confidence" SG_ 299 DAS_autoshiftBrakeRequired 1;
BA_ "Confidence" SG_ 299 DAS_autoshiftSteerRequest 1;
BA_ "Confidence" SG_ 921 DAS_autopilotState 1;
BA_ "Confidence" SG_ 921 DAS_blindSpotRearLeft 1;
BA_ "Confidence" SG_ 921 DAS_blindSpotRearRight 1;
BA_ "Confidence" SG_ 921 DAS_fusedSpeedLimit 1;
BA_ "Confidence" SG_ 921 DAS_suppressSpeedWarning 1;
BA_ "Confidence" SG_ 921 DAS_visionOnlySpeedLimit 1;
BA_ "Confidence" SG_ 921 DAS_heaterState 1;
BA_ "Confidence" SG_ 921 DAS_forwardCollisionWarning 1;
BA_ "Confidence" SG_ 921 DAS_autoparkReady 1;
BA_ "Confidence" SG_ 921 DAS_autoparkActive 1;
BA_ "Confidence" SG_ 921 DAS_lssState 1;
BA_ "Confidence" SG_ 921 DAS_sideCollisionAvoid 1;
BA_ "Confidence" SG_ 921 DAS_sideCollisionWarning 1;
BA_ "Confidence" SG_ 921 DAS_sideCollisionInhibit 1;
BA_ "Confidence" SG_ 921 DAS_laneDepartureWarning 1;
BA_ "Confidence" SG_ 921 DAS_fleetSpeedState 1;
BA_ "Confidence" SG_ 921 DAS_autopilotHandsOnState 1;
BA_ "Confidence" SG_ 921 DAS_autoLaneChangeState 1;
BA_ "Confidence" SG_ 905 DAS_accSpeedLimit 1;
BA_ "Confidence" SG_ 905 DAS_pmmObstacleSeverity 1;
BA_ "Confidence" SG_ 905 DAS_pmmLoggingRequest 1;
BA_ "Confidence" SG_ 905 DAS_activationFailureStatus 1;
BA_ "Confidence" SG_ 905 DAS_pmmUltrasonicsFaultReason 1;
BA_ "Confidence" SG_ 905 DAS_pmmRadarFaultReason 1;
BA_ "Confidence" SG_ 905 DAS_pmmSysFaultReason 1;
BA_ "Confidence" SG_ 905 DAS_pmmCameraFaultReason 1;
BA_ "Confidence" SG_ 905 DAS_ACC_report 1;
BA_ "Confidence" SG_ 905 DAS_relaxCruiseLimits 1;
BA_ "Confidence" SG_ 905 DAS_csaState 1;
BA_ "Confidence" SG_ 905 DAS_radarTelemetry 1;
BA_ "Confidence" SG_ 905 DAS_robState 1;
BA_ "Confidence" SG_ 905 DAS_driverInteractionLevel 1;
BA_ "Confidence" SG_ 905 DAS_ppOffsetDesiredRamp 1;
BA_ "Confidence" SG_ 905 DAS_longCollisionWarning 1;
BA_ "Confidence" SG_ 1548 DAS_TR_Obj00_Class 1;
BA_ "Confidence" SG_ 1548 DAS_TR_Obj00_Dx 1;
BA_ "Confidence" SG_ 1548 DAS_TR_Obj00_Dy 1;
BA_ "Confidence" SG_ 1548 DAS_TR_Obj00_Vx 1;
BA_ "Confidence" SG_ 1548 DAS_TR_Obj00_RCS 1;
BA_ "Confidence" SG_ 1548 DAS_TR_Obj00_Length 1;
BA_ "Confidence" SG_ 1548 DAS_TR_Obj00_MovingState 1;
BA_ "Confidence" SG_ 1548 DAS_TR_Obj00_Dz 1;
BA_ "Confidence" SG_ 1548 DAS_TR_Obj00_Exist 1;
BA_ "Confidence" SG_ 586 DAS_autosteerVehiclesUsage 1;
BA_ "Confidence" SG_ 586 DAS_autosteerHPPUsage 1;
BA_ "Confidence" SG_ 586 DAS_autosteerNavigationUsage 1;
BA_ "Confidence" SG_ 586 DAS_autosteerModelUsage 1;
BA_ "Confidence" SG_ 586 DAS_autosteerBottsDotsUsage 1;
BA_ "Confidence" SG_ 586 DAS_offsetSide 1;
BA_ "Confidence" SG_ 586 DAS_roadSurfaceType 1;
BA_ "Confidence" SG_ 586 DAS_autosteerHealthState 1;
BA_ "Confidence" SG_ 586 DAS_lastLinePreferenceReason 1;
BA_ "Confidence" SG_ 586 DAS_plannerState 1;
BA_ "Confidence" SG_ 586 DAS_lastAutosteerAbortReason 1;
BA_ "Confidence" SG_ 586 DAS_navAvailable 1;
BA_ "Confidence" SG_ 586 DAS_navDistance 1;
BA_ "Confidence" SG_ 586 DAS_accSmartSpeedState 1;
BA_ "Confidence" SG_ 586 DAS_ulcInProgress 1;
BA_ "Confidence" SG_ 586 DAS_trafficAwareSetSpeedInUse 1;
BA_ "Confidence" SG_ 586 DAS_isaSystemState 1;
BA_ "Confidence" SG_ 586 DAS_behaviorType 1;
BA_ "Confidence" SG_ 586 DAS_ulcType 1;
BA_ "Confidence" SG_ 586 DAS_rearVehDetectedThisCycle 1;
BA_ "Confidence" SG_ 586 DAS_rearLeftVehDetectedCurrent 1;
BA_ "Confidence" SG_ 586 DAS_rearRightVehDetectedTrip 1;
BA_ "Confidence" SG_ 586 DAS_rearLeftVehDetectedTrip 1;
BA_ "SystemSignalLongSymbol" SG_ 1318 DIF_a144_packPerformanceDeviatio "DIF_a144_packPerformanceDeviation";
BA_ "SystemSignalLongSymbol" SG_ 1318 DIF_a244_plausibleSingleSwitchSh "DIF_a244_plausibleSingleSwitchShortOnly";
BA_ "SystemSignalLongSymbol" SG_ 854 DIF_a039_exceptionUndefinedInstr "DIF_a039_exceptionUndefinedInstruction";
BA_ "SystemSignalLongSymbol" SG_ 855 DIF_a081_P0BFF_DIF_EM_CurrentHig "DIF_a081_P0BFF_DIF_EM_CurrentHigh";
BA_ "SystemSignalLongSymbol" SG_ 855 DIF_a083_PABCD_DIF_ECU_DemoWindo "DIF_a083_PABCD_DIF_ECU_DemoWindow";
BA_ "SystemSignalLongSymbol" SG_ 859 DIF_a249_highStatorTempFromResis "DIF_a249_highStatorTempFromResist";
BA_ "Confidence" SG_ 1879 DIF_phaseOutBusbarTemp 1;
BA_ "Confidence" SG_ 1879 DIF_phaseOutBusbarWeldTemp 1;
BA_ "Confidence" SG_ 1879 DIF_phaseOutLugTemp 1;
BA_ "Confidence" SG_ 1879 DIF_dcLinkCapTemp 1;
BA_ "Confidence" SG_ 1879 DIF_hvDcCableTemp 1;
BA_ "Confidence" SG_ 1879 DIF_negDcBusbarTemp 1;
BA_ "Confidence" SG_ 1879 DIF_posDcBusbarTemp 1;
BA_ "Confidence" SG_ 1879 DIF_statorEndWindingTemp 1;
BA_ "Confidence" SG_ 1879 DIF_rotorMaxMagnetTemp 1;
BA_ "Confidence" SG_ 1879 DIF_lightSenseV 1;
BA_ "Confidence" SG_ 1879 DIF_pyroSenseV 1;
BA_ "Confidence" SG_ 1879 DIF_statorSlotWindingTemp 1;
BA_ "Confidence" SG_ 1879 DIF_intervalMaxHvBusV 1;
BA_ "Confidence" SG_ 634 DIF_hvilCurrent 1;
BA_ "Confidence" SG_ 634 DIF_hvilCmVoltage 1;
BA_ "Confidence" SG_ 634 DIF_hvilStatus 1;
BA_ "Confidence" SG_ 634 DIF_hvilSupplyState 1;
BA_ "Confidence" SG_ 634 DIF_activeDischargeStatus 1;
BA_ "Confidence" SG_ 634 DIF_vBat 1;
BA_ "Confidence" SG_ 634 DIF_vBatQF 1;
BA_ "Confidence" SG_ 634 DIF_powerStageSafeState 1;
BA_ "Confidence" SG_ 634 DIF_fluxState 1;
BA_ "Confidence" SG_ 634 DIF_gateDriveState 1;
BA_ "Confidence" SG_ 1622 DIF_buildType 1;
BA_ "Confidence" SG_ 1622 DIF_motorType 1;
BA_ "Confidence" SG_ 1622 DIF_siliconType 1;
BA_ "Confidence" SG_ 1622 DIF_mechSafeStateType 1;
BA_ "Confidence" SG_ 1622 DIF_oilPumpBuildType 1;
BA_ "Confidence" SG_ 1622 DIF_refRotorFlux 1;
BA_ "Confidence" SG_ 1622 DIF_refRotorOffset 1;
BA_ "Confidence" SG_ 1622 DIF_speedWearTotal 1;
BA_ "Confidence" SG_ 1622 DIF_torqueWearTotal 1;
BA_ "Confidence" SG_ 421 DIF_motorCurrent 1;
BA_ "Confidence" SG_ 421 DIF_switchingFrequency 1;
BA_ "Confidence" SG_ 421 DIF_targetFluxMode 1;
BA_ "Confidence" SG_ 918 DIF_oilPumpState 1;
BA_ "Confidence" SG_ 918 DIF_oilPumpFluidTQF 1;
BA_ "Confidence" SG_ 918 DIF_oilPumpLeadAngle 1;
BA_ "Confidence" SG_ 918 DIF_oilPumpFlowTarget 1;
BA_ "Confidence" SG_ 918 DIF_oilPumpFlowActual 1;
BA_ "Confidence" SG_ 918 DIF_oilPumpFluidT 1;
BA_ "Confidence" SG_ 918 DIF_oilPumpPhaseCurrent 1;
BA_ "Confidence" SG_ 918 DIF_oilPumpPressureEstimate 1;
BA_ "Confidence" SG_ 918 DIF_oilPumpPressureExpected 1;
BA_ "Confidence" SG_ 918 DIF_oilPumpPressureResidual 1;
BA_ "Confidence" SG_ 741 DIF_elecPower 1;
BA_ "Confidence" SG_ 741 DIF_heatPowerOptimal 1;
BA_ "Confidence" SG_ 741 DIF_heatPowerMax 1;
BA_ "Confidence" SG_ 741 DIF_heatPowerActual 1;
BA_ "Confidence" SG_ 741 DIF_excessHeatCommand 1;
BA_ "Confidence" SG_ 741 DIF_drivePowerMax 1;
BA_ "Confidence" SG_ 725 DIF_state 1;
BA_ "Confidence" SG_ 725 DIF_keepAliveRequest 1;
BA_ "Confidence" SG_ 725 DIF_soptState 1;
BA_ "Confidence" SG_ 725 DIF_adState 1;
BA_ "Confidence" SG_ 725 DIF_driveModeState 1;
BA_ "Confidence" SG_ 725 DIF_lvSupplyV 1;
BA_ "Confidence" SG_ 725 DIF_wasteState 1;
BA_ "Confidence" SG_ 725 DIF_haltRequest 1;
BA_ "Confidence" SG_ 725 DIF_axleSpeedLimitRequest 1;
BA_ "Confidence" SG_ 725 DIF_adDirection 1;
BA_ "Confidence" SG_ 725 DIF_spinDownLearningState 1;
BA_ "Confidence" SG_ 725 DIF_spinDownLearningMode 1;
BA_ "SystemSignalLongSymbol" SG_ 725 DIF_unitRecoveredFromResetAtSpee "DIF_unitRecoveredFromResetAtSpeed";
VAL_ 299 DAS_smartShiftTorqueDirection 4 "SUGGESTED_TORQUE_DIRECTION_NOT_READY" 3 "SUGGESTED_TORQUE_DIRECTION_FORWARD" 2 "SUGGESTED_TORQUE_DIRECTION_REVERSE" 1 "SUGGESTED_TORQUE_DIRECTION_NOT_CONFIDENT" 0 "SUGGESTED_TORQUE_DIRECTION_SNA" ;
VAL_ 299 DAS_smartShiftTorqueReason 15 "SUGGESTED_TORQUE_REASON_FSD_E2E" 14 "SUGGESTED_TORQUE_REASON_PERP_PARKING" 13 "SUGGESTED_TORQUE_REASON_PLL_PARKING" 12 "SUGGESTED_TORQUE_REASON_BLOCKING_VEHICLE" 11 "SUGGESTED_TORQUE_REASON_STATIC_OBSTACLE" 10 "SUGGESTED_TORQUE_REASON_CURB" 9 "SUGGESTED_TORQUE_REASON_RETRACE" 8 "SUGGESTED_TORQUE_REASON_PLL_TO_ROAD_SUBS_SHFT" 7 "SUGGESTED_TORQUE_REASON_PLL_TO_ROAD_1ST_SHFT" 6 "SUGGESTED_TORQUE_REASON_CIPV" 5 "SUGGESTED_TORQUE_REASON_GATE" 4 "SUGGESTED_TORQUE_REASON_ROAD_MARKING" 3 "SUGGESTED_TORQUE_REASON_SMART_SUMMON_SHORT_PLAN" 2 "SUGGESTED_TORQUE_REASON_SMART_SUMMON_PLAN" 1 "SUGGESTED_TORQUE_REASON_SMART_SHIFT_PLAN" 0 "SUGGESTED_TORQUE_REASON_SNA" ;
VAL_ 299 DAS_autoshiftTorqueDirectionDbg 4 "SUGGESTED_TORQUE_DIRECTION_NOT_READY" 3 "SUGGESTED_TORQUE_DIRECTION_FORWARD" 2 "SUGGESTED_TORQUE_DIRECTION_REVERSE" 1 "SUGGESTED_TORQUE_DIRECTION_NOT_CONFIDENT" 0 "SUGGESTED_TORQUE_DIRECTION_SNA" ;
VAL_ 299 DAS_autoshiftUpcomingDirection 3 "AUTOSHIFT_DIRECTION_SNA" 2 "AUTOSHIFT_DIRECTION_DRIVE" 1 "AUTOSHIFT_DIRECTION_REVERSE" 0 "AUTOSHIFT_DIRECTION_NONE" ;
VAL_ 299 DAS_autoshiftSteerRequest 3 "AUTOSHIFT_STEERING_DIRECTION_LEFT" 2 "AUTOSHIFT_STEERING_DIRECTION_RIGHT" 1 "AUTOSHIFT_STEERING_DIRECTION_ANY" 0 "AUTOSHIFT_STEERING_DIRECTION_NONE" ;
VAL_ 921 DAS_autopilotState 14 "FAULT" 9 "ABORTED" 8 "ABORTING" 6 "ACTIVE_FSD" 5 "ACTIVE_NAV" 4 "ACTIVE_RESTRICTED" 3 "ACTIVE_NOMINAL" 2 "AVAILABLE" 1 "UNAVAILABLE" 0 "DISABLED" ;
VAL_ 921 DAS_blindSpotRearLeft 2 "WARNING_LEVEL_2" 1 "WARNING_LEVEL_1" 0 "NO_WARNING" ;
VAL_ 921 DAS_blindSpotRearRight 2 "WARNING_LEVEL_2" 1 "WARNING_LEVEL_1" 0 "NO_WARNING" ;
VAL_ 921 DAS_suppressSpeedWarning 1 "Suppress_Speed_Warning" 0 "Do_Not_Suppress" ;
VAL_ 921 DAS_heaterState 1 "HEATER_ON" 0 "HEATER_OFF_SNA" ;
VAL_ 921 DAS_forwardCollisionWarning 1 "FORWARD_COLLISION_WARNING" 0 "NONE" ;
VAL_ 921 DAS_autoparkReady 1 "AUTOPARK_READY" 0 "AUTOPARK_UNAVAILABLE" ;
VAL_ 921 DAS_lssState 7 "LSS_STATE_OFF" 6 "LSS_STATE_ABORT" 5 "LSS_STATE_BLINDSPOT" 4 "LSS_STATE_MONITOR" 3 "LSS_STATE_ELK" 2 "LSS_STATE_LKA" 1 "LSS_STATE_LDW" 0 "LSS_STATE_FAULT" ;
VAL_ 921 DAS_sideCollisionAvoid 2 "AVOID_RIGHT" 1 "AVOID_LEFT" 0 "NONE" ;
VAL_ 921 DAS_sideCollisionWarning 3 "WARN_LEFT_RIGHT" 2 "WARN_RIGHT" 1 "WARN_LEFT" 0 "NONE" ;
VAL_ 921 DAS_sideCollisionInhibit 1 "INHIBIT" 0 "NO_INHIBIT" ;
VAL_ 921 DAS_laneDepartureWarning 4 "RIGHT_WARNING_SEVERE" 3 "LEFT_WARNING_SEVERE" 2 "RIGHT_WARNING" 1 "LEFT_WARNING" 0 "NONE" ;
VAL_ 921 DAS_fleetSpeedState 3 "FLEETSPEED_HOLD" 2 "FLEETSPEED_ACTIVE" 1 "FLEETSPEED_AVAILABLE" 0 "FLEETSPEED_UNAVAILABLE" ;
VAL_ 921 DAS_autopilotHandsOnState 15 "LC_HANDS_ON_SNA" 10 "LC_HANDS_ON_REQD_ESCALATED_CHIME_2" 9 "LC_HANDS_ON_REQD_ESCALATED_CHIME_1" 8 "LC_HANDS_ON_SUSPENDED" 7 "LC_HANDS_ON_REQD_STRUCK_OUT" 6 "LC_HANDS_ON_REQD_SLOWING" 5 "LC_HANDS_ON_REQD_CHIME_2" 4 "LC_HANDS_ON_REQD_CHIME_1" 3 "LC_HANDS_ON_REQD_VISUAL" 2 "LC_HANDS_ON_REQD_NOT_DETECTED" 1 "LC_HANDS_ON_REQD_DETECTED" 0 "LC_HANDS_ON_NOT_REQD" ;
VAL_ 921 DAS_autoLaneChangeState 31 "ALC_SNA" 30 "ALC_ABORT_MISSION_PLAN_INVALID" 29 "ALC_ABORT_TIMEOUT" 28 "ALC_WAITING_HANDS_ON" 27 "ALC_BLOCKED_LANE_TYPE_R" 26 "ALC_BLOCKED_LANE_TYPE_L" 25 "ALC_BLOCKED_VEH_TTC_AND_USS_R" 24 "ALC_BLOCKED_VEH_TTC_R" 23 "ALC_BLOCKED_VEH_TTC_AND_USS_L" 22 "ALC_BLOCKED_VEH_TTC_L" 21 "ALC_UNAVAILABLE_SOLID_LANE_LINE" 20 "ALC_ABORT_OTHER_REASON" 19 "ALC_ABORT_BLINKER_TURNED_OFF" 18 "ALC_ABORT_LC_HEALTH_BAD" 17 "ALC_ABORT_POOR_VIEW_RANGE" 16 "ALC_ABORT_SIDE_OBSTACLE_PRESENT_R" 15 "ALC_ABORT_SIDE_OBSTACLE_PRESENT_L" 14 "ALC_WAITING_FOR_FWD_OBST_TO_PASS_R" 13 "ALC_WAITING_FOR_FWD_OBST_TO_PASS_L" 12 "ALC_WAITING_FOR_SIDE_OBST_TO_PASS_R" 11 "ALC_WAITING_FOR_SIDE_OBST_TO_PASS_L" 10 "ALC_IN_PROGRESS_R" 9 "ALC_IN_PROGRESS_L" 8 "ALC_AVAILABLE_BOTH" 7 "ALC_AVAILABLE_ONLY_R" 6 "ALC_AVAILABLE_ONLY_L" 5 "ALC_UNAVAILABLE_VEHICLE_SPEED" 4 "ALC_UNAVAILABLE_EXITING_HIGHWAY" 3 "ALC_UNAVAILABLE_TP_FOLLOW" 2 "ALC_UNAVAILABLE_SONICS_INVALID" 1 "ALC_UNAVAILABLE_NO_LANES" 0 "ALC_UNAVAILABLE_DISABLED" ;
VAL_ 905 DAS_pmmObstacleSeverity 7 "PMM_SNA" 6 "PMM_ACCEL_LIMIT" 5 "PMM_CRASH_FRONT" 4 "PMM_CRASH_REAR" 3 "PMM_BRAKE_REQUEST" 2 "PMM_IMMINENT_FRONT" 1 "PMM_IMMINENT_REAR" 0 "PMM_NONE" ;
VAL_ 905 DAS_pmmLoggingRequest 1 "TRUE" 0 "FALSE" ;
VAL_ 905 DAS_activationFailureStatus 2 "LC_ACTIVATION_FAILED_2" 1 "LC_ACTIVATION_FAILED_1" 0 "LC_ACTIVATION_IDLE" ;
VAL_ 905 DAS_pmmUltrasonicsFaultReason 4 "PMM_ULTRASONICS_INVALID_MIA" 3 "PMM_ULTRASONICS_BLOCKED_BOTH" 2 "PMM_ULTRASONICS_BLOCKED_REAR" 1 "PMM_ULTRASONICS_BLOCKED_FRONT" 0 "PMM_ULTRASONICS_NO_FAULT" ;
VAL_ 905 DAS_pmmRadarFaultReason 2 "PMM_RADAR_INVALID_MIA" 1 "PMM_RADAR_BLOCKED_FRONT" 0 "PMM_RADAR_NO_FAULT" ;
VAL_ 905 DAS_pmmSysFaultReason 7 "PMM_FAULT_BRAKE_PEDAL_INHIBIT" 6 "PMM_FAULT_ROAD_TYPE" 5 "PMM_FAULT_DISABLED_BY_USER" 4 "PMM_FAULT_STEERING_ANGLE_RATE" 3 "PMM_FAULT_DI_FAULT" 2 "PMM_FAULT_SPEED" 1 "PMM_FAULT_DAS_DISABLED" 0 "PMM_FAULT_NONE" ;
VAL_ 905 DAS_pmmCameraFaultReason 2 "PMM_CAMERA_INVALID_MIA" 1 "PMM_CAMERA_BLOCKED_FRONT" 0 "PMM_CAMERA_NO_FAULT" ;
VAL_ 905 DAS_ACC_report 24 "ACC_REPORT_BEHAVIOR_REPORT" 23 "ACC_REPORT_CAMERA_ONLY" 22 "ACC_REPORT_RADAR_OBJ_FIVE" 21 "ACC_REPORT_CIPV_CUTTING_OUT" 20 "ACC_REPORT_MCVLR_IN_PATH" 19 "ACC_REPORT_MCVLR_DPP" 18 "ACC_REPORT_FLEET_SPEEDS" 17 "ACC_REPORT_TARGET_MCP" 16 "ACC_REPORT_RADAR_OBJ_TWO" 15 "ACC_REPORT_RADAR_OBJ_ONE" 14 "ACC_REPORT_LC_EXTERNAL_STATE_ACTIVE_RESTRICTED" 13 "ACC_REPORT_LC_EXTERNAL_STATE_ABORTED" 12 "ACC_REPORT_LC_EXTERNAL_STATE_ABORTING" 11 "ACC_REPORT_LC_HANDS_ON_REQD_STRUCK_OUT" 10 "ACC_REPORT_CSA" 9 "ACC_REPORT_TARGET_TYPE_FAULT" 8 "ACC_REPORT_TARGET_TYPE_IPSO" 7 "ACC_REPORT_TARGET_TYPE_TRAFFIC_LIGHT" 6 "ACC_REPORT_TARGET_TYPE_STOP_SIGN" 5 "ACC_REPORT_TARGET_CUTIN" 4 "ACC_REPORT_TARGET_MCVR" 3 "ACC_REPORT_TARGET_MCVL" 2 "ACC_REPORT_TARGET_IN_FRONT_OF_CIPV" 1 "ACC_REPORT_TARGET_CIPV" 0 "ACC_REPORT_TARGET_NONE" ;
VAL_ 905 DAS_csaState 3 "CSA_EXTERNAL_STATE_HOLD" 2 "CSA_EXTERNAL_STATE_ENABLE" 1 "CSA_EXTERNAL_STATE_AVAILABLE" 0 "CSA_EXTERNAL_STATE_UNAVAILABLE" ;
VAL_ 905 DAS_radarTelemetry 2 "RADAR_TELEMETRY_URGENT" 1 "RADAR_TELEMETRY_NORMAL" 0 "RADAR_TELEMETRY_IDLE" ;
VAL_ 905 DAS_robState 3 "ROB_STATE_MAPLESS" 2 "ROB_STATE_ACTIVE" 1 "ROB_STATE_MEASURE" 0 "ROB_STATE_INHIBITED" ;
VAL_ 905 DAS_driverInteractionLevel 2 "CONTINUED_DRIVER_NOT_INTERACTING" 1 "DRIVER_NOT_INTERACTING" 0 "DRIVER_INTERACTING" ;
VAL_ 905 DAS_longCollisionWarning 15 "FCM_LONG_COLLISION_WARNING_SNA" 12 "FCM_LONG_COLLISION_WARNING_VEHICLE_CIPV2" 11 "FCM_LONG_COLLISION_WARNING_VEHICLE_MCVR2" 10 "FCM_LONG_COLLISION_WARNING_VEHICLE_MCVR" 9 "FCM_LONG_COLLISION_WARNING_VEHICLE_MCVL2" 8 "FCM_LONG_COLLISION_WARNING_VEHICLE_MCVL" 7 "FCM_LONG_COLLISION_WARNING_VEHICLE_CUTIN" 6 "FCM_LONG_COLLISION_WARNING_VEHICLE_CIPV" 5 "FCM_LONG_COLLISION_WARNING_TFL_STOPLINE" 4 "FCM_LONG_COLLISION_WARNING_STOPSIGN_STOPLINE" 3 "FCM_LONG_COLLISION_WARNING_IPSO" 2 "FCM_LONG_COLLISION_WARNING_PEDESTRIAN" 1 "FCM_LONG_COLLISION_WARNING_VEHICLE_UNKNOWN" 0 "FCM_LONG_COLLISION_WARNING_NONE" ;
VAL_ 1548 DAS_TR_Obj00_Class 4 "RADAR_CLASS_CONSTRUCTION_ELEMENT" 3 "RADAR_CLASS_MOVING_PEDESTRIAN" 2 "RADAR_CLASS_MOVING_TWO_WHEEL_VEHICLE" 1 "RADAR_CLASS_MOVING_FOUR_WHEEL_VEHICLE" 0 "RADAR_CLASS_UNKNOWN" ;
VAL_ 1548 DAS_TR_Obj00_MovingState 3 "RADAR_MOVESTATE_STANDING" 2 "RADAR_MOVESTATE_STOPPED" 1 "RADAR_MOVESTATE_MOVING" 0 "RADAR_MOVESTATE_INDETERMINATE" ;
VAL_ 586 DAS_autosteerVehiclesUsage 3 "BLACKLISTED" 2 "FUSED" 1 "AVAILABLE" 0 "REJECTED_UNAVAILABLE" ;
VAL_ 586 DAS_autosteerHPPUsage 3 "BLACKLISTED" 2 "FUSED" 1 "AVAILABLE" 0 "REJECTED_UNAVAILABLE" ;
VAL_ 586 DAS_autosteerNavigationUsage 3 "BLACKLISTED" 2 "FUSED" 1 "AVAILABLE" 0 "REJECTED_UNAVAILABLE" ;
VAL_ 586 DAS_autosteerModelUsage 3 "BLACKLISTED" 2 "FUSED" 1 "AVAILABLE" 0 "REJECTED_UNAVAILABLE" ;
VAL_ 586 DAS_autosteerBottsDotsUsage 3 "BLACKLISTED" 2 "FUSED" 1 "AVAILABLE" 0 "REJECTED_UNAVAILABLE" ;
VAL_ 586 DAS_offsetSide 3 "OFFSET_BOTH_OBJECTS" 2 "OFFSET_LEFT_OBJECT" 1 "OFFSET_RIGHT_OBJECT" 0 "NO_OFFSET" ;
VAL_ 586 DAS_roadSurfaceType 2 "ROAD_SURFACE_ENHANCED" 1 "ROAD_SURFACE_NORMAL" 0 "ROAD_SURFACE_SNA" ;
VAL_ 586 DAS_autosteerHealthState 5 "HEALTH_FAULT" 4 "HEALTH_ABORTING" 3 "HEALTH_SEVERELY_DEGRADED" 2 "HEALTH_DEGRADED" 1 "HEALTH_NOMINAL" 0 "HEALTH_UNAVAILABLE" ;
VAL_ 586 DAS_lastLinePreferenceReason 15 "NONE" 5 "COUNTRY_DRIVING_SIDE" 4 "AVOID_ONCOMING_LANES" 3 "NAVIGATION_BRANCH" 2 "NEIGHBOR_LANE_PROBABILIY" 1 "AGREEMENT_WITH_NEIGHBOR_LANES" 0 "OTHER_LANE_DISAGREES_WITH_MODEL" ;
VAL_ 586 DAS_plannerState 7 "TP_EXTSTATE_LANECHANGE_ABORT" 6 "TP_EXTSTATE_LANECHANGE_WAIT_FOR_FWD_OBSTACLE" 5 "TP_EXTSTATE_LANECHANGE_WAIT_FOR_SIDE_OBSTACLE" 4 "TP_EXTSTATE_LANECHANGE_IN_PROGRESS" 3 "TP_EXTSTATE_LANECHANGE_REQUESTED" 2 "TP_EXTSTATE_FOLLOW" 1 "TP_EXTSTATE_VL" 0 "TP_EXTSTATE_DISABLED" ;
VAL_ 586 DAS_lastAutosteerAbortReason 36 "UI_ABORT_REASON_AHB_MANUAL_OVERRIDE" 35 "UI_ABORT_REASON_DRIVER_NOT_PRESENT" 34 "UI_ABORT_REASON_USER_OVERRIDE_STRIKEOUT" 33 "UI_ABORT_REASON_SEATBELT_UNBUCKLED" 32 "UI_ABORT_REASON_AEB" 31 "UI_ABORT_REASON_NO_ABORT" 30 "UI_ABORT_REASON_CAMERA_FAILSAFES" 29 "UI_ABORT_REASON_ACC_CANCEL" 28 "UI_ABORT_REASON_EPAS_ERROR_CODE" 27 "UI_ABORT_REASON_PLANNER_OUTPUT_INVALID" 26 "UI_ABORT_REASON_FOLLOWER_OUTPUT_INVALID" 25 "UI_ABORT_REASON_VEHICLE_SPEED_ABOVE_MAX" 24 "UI_ABORT_REASON_DRIVING_OFF_NAV" 23 "UI_ABORT_REASON_CID_SWITCH_DISABLED" 22 "UI_ABORT_REASON_CRUISE_FAULT" 21 "UI_ABORT_REASON_COMPONENT_MIA" 20 "UI_ABORT_REASON_EPAS_EAC_DENIED" 19 "UI_ABORT_REASON_SIDE_COLLISION_IMMINENT" 18 "UI_ABORT_REASON_TRAILER_MODE" 17 "UI_ABORT_REASON_CAM_WATCHDOG" 16 "UI_ABORT_REASON_CAM_MSG_MIA" 15 "UI_ABORT_REASON_ME_MAIN_STATE_NOT_VISION" 14 "UI_ABORT_REASON_APP_ME_STATE_NOT_VISION" 2 "UI_ABORT_REASON_HM_STEERING_ERROR" 1 "UI_ABORT_REASON_HM_VIRTUAL_LANE_NO_INPUTS" 0 "UI_ABORT_REASON_HM_LANE_VIEW_RANGE" ;
VAL_ 586 DAS_navAvailable 1 "DAS_NAV_AVAILABLE" 0 "DAS_NAV_UNAVAILABLE" ;
VAL_ 586 DAS_accSmartSpeedState 5 "OFFRAMP_DELAY" 4 "SET_SPEED_SET_REQUESTED" 3 "ACTIVE_ONRAMP" 2 "ACTIVE_INTEGRATING" 1 "ACTIVE_OFFRAMP" 0 "NOT_ACTIVE" ;
VAL_ 586 DAS_ulcInProgress 1 "ULC_ACTIVE" 0 "ULC_INACTIVE" ;
VAL_ 586 DAS_isaSystemState 3 "ISA_UNAVAILABLE" 2 "ISA_INVALID" 1 "ISA_ASSUMED_LIMITS" 0 "ISA_NOMINAL" ;
VAL_ 586 DAS_behaviorType 3 "DAS_BEHAVIOR_LANE_CHANGE_RIGHT" 2 "DAS_BEHAVIOR_LANE_CHANGE_LEFT" 1 "DAS_BEHAVIOR_IN_LANE" 0 "DAS_BEHAVIOR_INVALID" ;
VAL_ 586 DAS_ulcType 2 "ULC_TYPE_SPEED" 1 "ULC_TYPE_NAV" 0 "ULC_TYPE_NONE" ;
VAL_ 586 DAS_rearVehDetectedThisCycle 1 "VEHICLE_DETECTED" 0 "VEHICLE_NOT_DETECTED" ;
VAL_ 586 DAS_rearLeftVehDetectedCurrent 1 "VEHICLE_DETECTED" 0 "VEHICLE_NOT_DETECTED" ;
VAL_ 586 DAS_rearRightVehDetectedTrip 1 "VEHICLE_DETECTED" 0 "VEHICLE_NOT_DETECTED" ;
VAL_ 586 DAS_rearLeftVehDetectedTrip 1 "VEHICLE_DETECTED" 0 "VEHICLE_NOT_DETECTED" ;
VAL_ 634 DIF_hvilStatus 2 "CLOSED" 1 "OPEN" 0 "DISABLED" ;
VAL_ 634 DIF_hvilSupplyState 2 "ACTIVE" 1 "INACTIVE" 0 "NOT_AVAILABLE" ;
VAL_ 634 DIF_vBatQF 1 "QUALIFIED" 0 "NOT_QUALIFIED" ;
VAL_ 634 DIF_powerStageSafeState 3 "PSTG_SAFESTATE_3PS_LOW" 2 "PSTG_SAFESTATE_3PS_HIGH" 1 "PSTG_SAFESTATE_ALL_OFF" 0 "PSTG_SAFESTATE_NONE" ;
VAL_ 634 DIF_fluxState 12 "DI_FLUXSTATE_DISABLED" 11 "DI_FLUXSTATE_MAGNET_FLUX_DETECT" 10 "DI_FLUXSTATE_STATIONARY_WASTE" 9 "DI_FLUXSTATE_FAULT" 7 "DI_FLUXSTATE_VCONTROL" 6 "DI_FLUXSTATE_ICONTROL" 5 "DI_FLUXSTATE_ENABLED" 4 "DI_FLUXSTATE_FLUX_DOWN" 3 "DI_FLUXSTATE_FLUX_UP" 2 "DI_FLUXSTATE_STANDBY" 1 "DI_FLUXSTATE_TEST" 0 "DI_FLUXSTATE_START" ;
VAL_ 634 DIF_gateDriveState 4 "PSTG_GD_STATE_NOT_CONFIGURED" 3 "PSTG_GD_STATE_CONFIGURED" 2 "PSTG_GD_STATE_CONFIGURING" 1 "PSTG_GD_STATE_SELFTEST" 0 "PSTG_GD_STATE_INIT" ;
VAL_ 1622 DIF_buildType 4 "INFO_MFG_BUILD" 3 "INFO_TRACEABLE_CI_BUILD" 2 "INFO_LOCAL_BUILD" 1 "INFO_PLATFORM_BUILD" 0 "INFO_UNKNOWN_BUILD" ;
VAL_ 1622 DIF_motorType 31 "DI_MOTOR_PM216E" 20 "DI_MOTOR_PM215D_1KV" 18 "DI_MOTOR_IM260E_1KV" 17 "DI_MOTOR_IM260D_1KV" 16 "DI_MOTOR_PM261C" 15 "DI_MOTOR_PM215C_1KV" 14 "DI_MOTOR_IM260C_1KV" 13 "DI_MOTOR_PM215A_1KV" 12 "DI_MOTOR_IM260A_1KV" 11 "DI_MOTOR_IM228HEA" 10 "DI_MOTOR_PM228HEA" 9 "DI_MOTOR_PM275C" 8 "DI_MOTOR_PM291D" 7 "DI_MOTOR_PM291C" 6 "DI_MOTOR_PM228C" 5 "DI_MOTOR_PM350B" 4 "DI_MOTOR_PM275B" 3 "DI_MOTOR_IM130D_AL" 2 "DI_MOTOR_IM130D" 1 "DI_MOTOR_PM216D" 0 "DI_MOTOR_SNA" ;
VAL_ 1622 DIF_siliconType 1 "IGBT" 0 "MOSFET" ;
VAL_ 1622 DIF_mechSafeStateType 2 "DI_MECH_SAFE_STATE_TYPE_PRESENT" 1 "DI_MECH_SAFE_STATE_TYPE_NONE" 0 "DI_MECH_SAFE_STATE_TYPE_SNA" ;
VAL_ 1622 DIF_oilPumpBuildType 4 "INFO_MFG_BUILD" 3 "INFO_TRACEABLE_CI_BUILD" 2 "INFO_LOCAL_BUILD" 1 "INFO_PLATFORM_BUILD" 0 "INFO_UNKNOWN_BUILD" ;
VAL_ 421 DIF_targetFluxMode 2 "DI_FLUXMODE_FW" 1 "DI_FLUXMODE_FS" 0 "DI_FLUXMODE_OPTIMUM" ;
VAL_ 918 DIF_oilPumpState 7 "OIL_PUMP_SNA" 6 "OIL_PUMP_FAULTED" 2 "OIL_PUMP_COLD_STARTUP" 1 "OIL_PUMP_ENABLE" 0 "OIL_PUMP_STANDBY" ;
VAL_ 918 DIF_oilPumpFluidTQF 1 "OIL_PUMP_FLUIDT_HIGH_CONFIDENCE" 0 "OIL_PUMP_FLUIDT_LOW_CONFIDENCE" ;
VAL_ 725 DIF_state 4 "DI_STATE_ENABLE" 3 "DI_STATE_ABORT" 2 "DI_STATE_FAULT" 1 "DI_STATE_STANDBY" 0 "DI_STATE_UNAVAILABLE" ;
VAL_ 725 DIF_keepAliveRequest 1 "KEEP_ALIVE" 0 "NO_REQUEST" ;
VAL_ 725 DIF_soptState 9 "SOPT_DISABLED" 8 "SOPT_SNA" 7 "SOPT_TEST_FAILED" 6 "SOPT_TEST_SKIPPED" 5 "SOPT_TEST_PASSED" 4 "SOPT_CURRENT_TEST" 3 "SOPT_ASC_TEST" 2 "SOPT_PSTG_BRING_UP_AT_SPEED" 1 "SOPT_PSTG_BRING_UP" 0 "SOPT_INIT" ;
VAL_ 725 DIF_adState 3 "AD_STATE_FAULTED" 2 "AD_STATE_BACKUP" 1 "AD_STATE_NORMAL" 0 "AD_STATE_STARTUP" ;
VAL_ 725 DIF_driveModeState 1 "DM_STATE_DRIVE" 0 "DM_STATE_NONDRIVE" ;
VAL_ 725 DIF_wasteState 3 "DI_WASTE_STATIONARY" 2 "DI_WASTE_ON" 1 "DI_WASTE_AVAILABLE" 0 "DI_WASTE_UNAVAILABLE" ;
VAL_ 725 DIF_haltRequest 2 "DI_HALT_GRACEFUL" 1 "DI_HALT_IMMEDIATE" 0 "DI_HALT_NONE" ;
VAL_ 725 DIF_adDirection 1 "AD_FORWARD" 0 "AD_BACKWARD" ;
VAL_ 725 DIF_spinDownLearningState 9 "SPINDOWN_STATE_DONE" 8 "SPINDOWN_STATE_WRITE" 7 "SPINDOWN_STATE_VERIFY" 6 "SPINDOWN_STATE_CORRECT" 5 "SPINDOWN_STATE_MEASURE" 4 "SPINDOWN_STATE_COAST" 3 "SPINDOWN_STATE_ACCELERATE" 2 "SPINDOWN_STATE_WAIT" 1 "SPINDOWN_STATE_PRECHECK" 0 "SPINDOWN_STATE_INIT" ;
VAL_ 725 DIF_spinDownLearningMode 1 "SPINDOWN_MODE_ON_GROUND" 0 "SPINDOWN_MODE_ON_LIFT" ;
